VERSION ""

NS_ :

BS_:

BU_: APIM_CISM FCIMB RACM_RCIM DSP WCM DACMC HUD_ADV TRM_ITRM ACM GWM _delete APIM IPC GENERIC TSTR

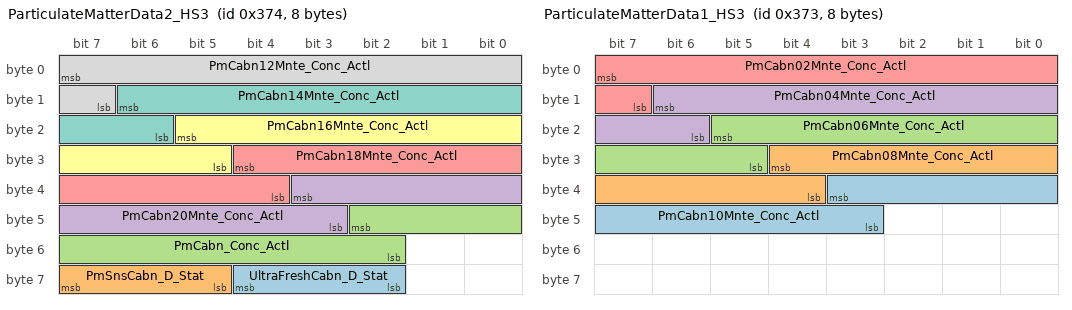
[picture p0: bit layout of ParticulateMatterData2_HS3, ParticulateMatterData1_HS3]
BO_ 884 ParticulateMatterData2_HS3: 8 GWM
 SG_ UltraFreshCabn_D_Stat : 60|3@0+ (1,0) [0|7] "SED"  APIM_CISM,GENERIC
 SG_ PmSnsCabn_D_Stat : 63|3@0+ (1,0) [0|7] "SED"  APIM_CISM,APIM,RACM_RCIM
 SG_ PmCabn_Conc_Actl : 42|9@0+ (1,0) [0|509] "parts/million"  APIM_CISM,APIM,RACM_RCIM
 SG_ PmCabn20Mnte_Conc_Actl : 35|9@0+ (1,0) [0|509] "parts/million"  RACM_RCIM,APIM_CISM,APIM
 SG_ PmCabn18Mnte_Conc_Actl : 28|9@0+ (1,0) [0|509] "parts/million"  RACM_RCIM,APIM_CISM,APIM
 SG_ PmCabn16Mnte_Conc_Actl : 21|9@0+ (1,0) [0|509] "parts/million"  RACM_RCIM,APIM_CISM,APIM
 SG_ PmCabn14Mnte_Conc_Actl : 14|9@0+ (1,0) [0|509] "parts/million"  RACM_RCIM,APIM_CISM,APIM
 SG_ PmCabn12Mnte_Conc_Actl : 7|9@0+ (1,0) [0|509] "parts/million"  RACM_RCIM,APIM_CISM,APIM

BO_ 883 ParticulateMatterData1_HS3: 8 GWM
 SG_ PmCabn10Mnte_Conc_Actl : 35|9@0+ (1,0) [0|509] "parts/million"  RACM_RCIM,APIM_CISM,APIM
 SG_ PmCabn08Mnte_Conc_Actl : 28|9@0+ (1,0) [0|509] "parts/million"  RACM_RCIM,APIM_CISM,APIM
 SG_ PmCabn06Mnte_Conc_Actl : 21|9@0+ (1,0) [0|509] "parts/million"  RACM_RCIM,APIM_CISM,APIM
 SG_ PmCabn04Mnte_Conc_Actl : 14|9@0+ (1,0) [0|509] "parts/million"  RACM_RCIM,APIM_CISM,APIM
 SG_ PmCabn02Mnte_Conc_Actl : 7|9@0+ (1,0) [0|509] "parts/million"  RACM_RCIM,APIM_CISM,APIM

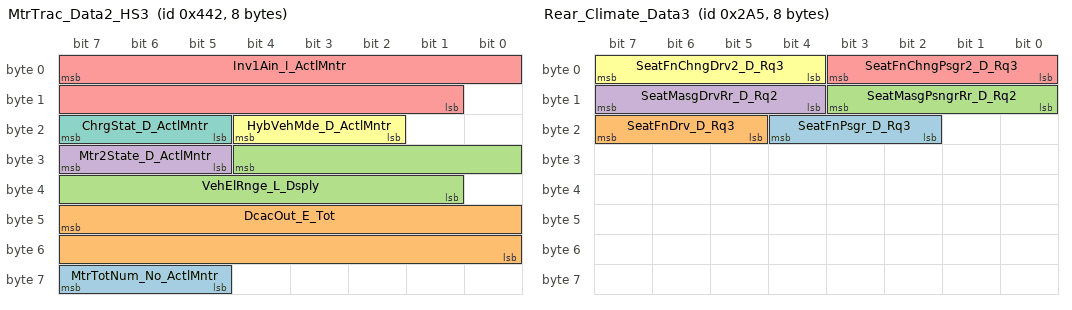
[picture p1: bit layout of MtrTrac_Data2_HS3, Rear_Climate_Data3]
BO_ 1090 MtrTrac_Data2_HS3: 8 GWM
 SG_ MtrTotNum_No_ActlMntr : 63|3@0+ (1,0) [0|7] "unitless"  GENERIC
 SG_ DcacOut_E_Tot : 47|16@0+ (20,0) [0|1310700] "watthour"  APIM_CISM,APIM
 SG_ VehElRnge_L_Dsply : 28|12@0+ (0.1,0) [0|409.3] "kilometer"  APIM_CISM,APIM,HUD_ADV,IPC
 SG_ Mtr2State_D_ActlMntr : 31|3@0+ (1,0) [0|7] "SED" Vector__XXX
 SG_ Inv1Ain_I_ActlMntr : 7|15@0+ (0.1,-1000) [-1000|2276.5] "ampere"  GENERIC
 SG_ HybVehMde_D_ActlMntr : 20|3@0+ (1,0) [0|7] "SED"  GENERIC
 SG_ ChrgStat_D_ActlMntr : 23|3@0+ (1,0) [0|7] "SED"  GENERIC

BO_ 677 Rear_Climate_Data3: 8 RACM_RCIM
 SG_ SeatFnPsgr_D_Rq3 : 20|3@0+ (1,0) [0|7] "SED"  GWM
 SG_ SeatFnDrv_D_Rq3 : 23|3@0+ (1,0) [0|7] "SED"  GWM
 SG_ SeatMasgPsngrRr_D_Rq2 : 11|4@0+ (1,0) [0|15] "SED"  GWM
 SG_ SeatMasgDrvRr_D_Rq2 : 15|4@0+ (1,0) [0|15] "SED"  GWM
 SG_ SeatFnChngPsgr2_D_Rq3 : 3|4@0+ (1,0) [0|15] "SED"  GWM
 SG_ SeatFnChngDrv2_D_Rq3 : 7|4@0+ (1,0) [0|15] "SED"  GWM

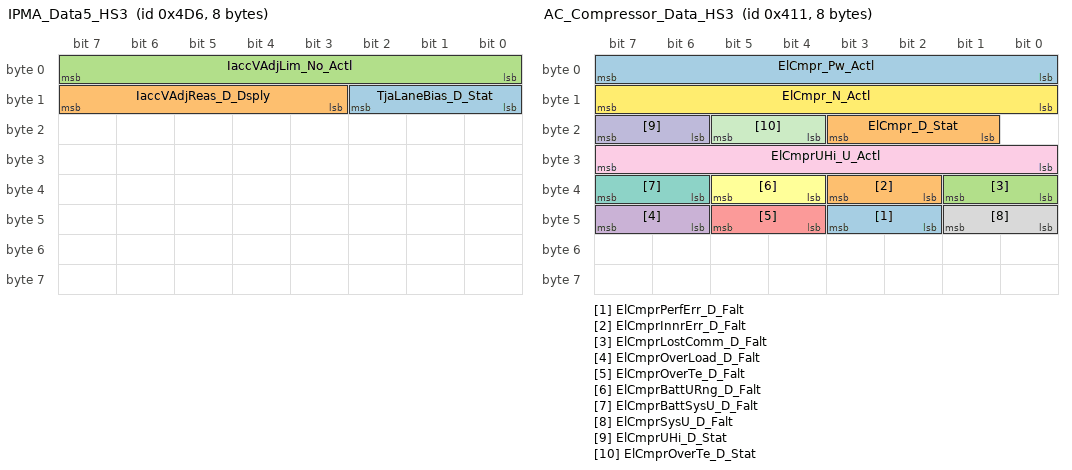
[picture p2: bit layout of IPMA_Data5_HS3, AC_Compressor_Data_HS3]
BO_ 1238 IPMA_Data5_HS3: 8 GWM
 SG_ TjaLaneBias_D_Stat : 10|3@0+ (1,0) [0|7] "SED"  IPC
 SG_ IaccVAdjReas_D_Dsply : 15|5@0+ (1,0) [0|31] "SED"  APIM,APIM_CISM,IPC
 SG_ IaccVAdjLim_No_Actl : 7|8@0+ (1,0) [0|255] "unitless"  APIM,APIM_CISM,IPC

BO_ 1041 AC_Compressor_Data_HS3: 8 GWM
 SG_ ElCmprPerfErr_D_Falt : 43|2@0+ (1,0) [0|3] "SED" Vector__XXX
 SG_ ElCmprInnrErr_D_Falt : 35|2@0+ (1,0) [0|3] "SED" Vector__XXX
 SG_ ElCmprLostComm_D_Falt : 33|2@0+ (1,0) [0|3] "SED" Vector__XXX
 SG_ ElCmprOverLoad_D_Falt : 47|2@0+ (1,0) [0|3] "SED" Vector__XXX
 SG_ ElCmprOverTe_D_Falt : 45|2@0+ (1,0) [0|3] "SED" Vector__XXX
 SG_ ElCmprBattURng_D_Falt : 37|2@0+ (1,0) [0|3] "SED" Vector__XXX
 SG_ ElCmprBattSysU_D_Falt : 39|2@0+ (1,0) [0|3] "SED" Vector__XXX
 SG_ ElCmprSysU_D_Falt : 41|2@0+ (1,0) [0|3] "SED" Vector__XXX
 SG_ ElCmprUHi_U_Actl : 31|8@0+ (2,0) [0|510] "volt" Vector__XXX
 SG_ ElCmprUHi_D_Stat : 23|2@0+ (1,0) [0|3] "SED" Vector__XXX
 SG_ ElCmprOverTe_D_Stat : 21|2@0+ (1,0) [0|3] "SED" Vector__XXX
 SG_ ElCmpr_N_Actl : 15|8@0+ (50,0) [0|12700] "RPM"  WCM
 SG_ ElCmpr_Pw_Actl : 7|8@0+ (40,0) [0|10160] "watts" Vector__XXX
 SG_ ElCmpr_D_Stat : 19|3@0+ (1,0) [0|7] "SED" Vector__XXX

BO_ 2609971416 OTAPhysGWM_ECGtoWCM: 8 GWM
 SG_ OTAPhysGWM_ECGtoWCM : 7|29@0+ (1,0) [0|536870911] "unitless"  WCM

BO_ 2610126912 OTAPhysWCMtoGWM_ECG: 8 WCM
 SG_ OTAPhysWCMtoGWM_ECG : 7|29@0+ (1,0) [0|536870911] "unitless"  GWM

BO_ 2611019992 PARSEDPhysGWM_ECGtoWCM: 8 GWM
 SG_ PARSEDPhysGWM_ECGtoWCM : 7|29@0+ (1,0) [0|536870911] "unitless"  WCM

BO_ 2611175488 PARSEDPhysWCMtoGWM_ECG: 8 WCM
 SG_ PARSEDPhysWCMtoGWM_ECG : 7|29@0+ (1,0) [0|536870911] "unitless"  GWM

BO_ 2612068568 PARSEDPushFcGWM_ECGtoWCM: 8 GWM
 SG_ PARSEDPushFcGWM_ECGtoWCM : 7|29@0+ (1,0) [0|536870911] "unitless"  WCM

BO_ 2612224064 PARSEDPushWCMtoGWM_ECG: 8 WCM
 SG_ PARSEDPushWCMtoGWM_ECG : 7|29@0+ (1,0) [0|536870911] "unitless"  GWM

BO_ 557 DSPAMP_Send_Signals_2: 8 DSP
 SG_ AudioToneTouchY_D_Stat : 15|8@0+ (1,0) [0|255] "SED"  APIM_CISM,APIM
 SG_ AudioToneTouchX_D_Stat : 7|8@0+ (1,0) [0|255] "SED"  APIM_CISM,APIM
 SG_ AudioToneTouch_D_Stat : 23|2@0+ (1,0) [0|3] "SED"  APIM_CISM,APIM

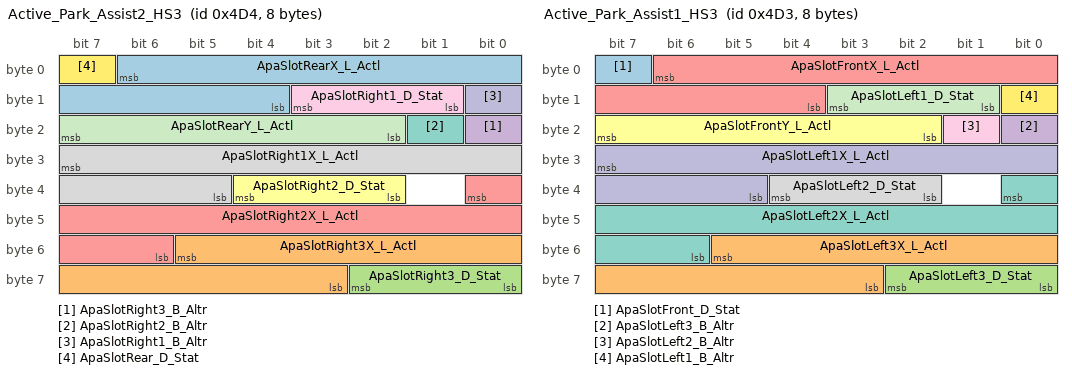
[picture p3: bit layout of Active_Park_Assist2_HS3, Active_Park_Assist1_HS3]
BO_ 1236 Active_Park_Assist2_HS3: 8 GWM
 SG_ ApaSlotRearX_L_Actl : 6|11@0+ (0.02,-20.96) [-20.96|19.98] "meter"  APIM_CISM,APIM
 SG_ ApaSlotRight3X_L_Actl : 53|11@0+ (0.02,-20.96) [-20.96|19.98] "meter"  APIM_CISM,APIM
 SG_ ApaSlotRight3_D_Stat : 58|3@0+ (1,0) [0|7] "SED"  APIM_CISM,APIM
 SG_ ApaSlotRight3_B_Altr : 16|1@0+ (1,0) [0|1] "SED"  APIM_CISM,APIM
 SG_ ApaSlotRight2X_L_Actl : 32|11@0+ (0.02,-20.96) [-20.96|19.98] "meter"  APIM_CISM,APIM
 SG_ ApaSlotRight2_D_Stat : 36|3@0+ (1,0) [0|7] "SED"  APIM_CISM,APIM
 SG_ ApaSlotRight2_B_Altr : 17|1@0+ (1,0) [0|1] "SED"  APIM_CISM,APIM
 SG_ ApaSlotRight1X_L_Actl : 31|11@0+ (0.02,-20.96) [-20.96|19.98] "meter"  APIM_CISM,APIM
 SG_ ApaSlotRight1_D_Stat : 11|3@0+ (1,0) [0|7] "SED"  APIM_CISM,APIM
 SG_ ApaSlotRight1_B_Altr : 8|1@0+ (1,0) [0|1] "SED"  APIM_CISM,APIM
 SG_ ApaSlotRearY_L_Actl : 23|6@0+ (0.2,-6.4) [-6.4|6.2] "meter"  APIM_CISM,APIM
 SG_ ApaSlotRear_D_Stat : 7|1@0+ (1,0) [0|1] "SED"  APIM_CISM,APIM

BO_ 1235 Active_Park_Assist1_HS3: 8 GWM
 SG_ ApaSlotFront_D_Stat : 7|1@0+ (1,0) [0|1] "SED"  APIM_CISM,APIM
 SG_ ApaSlotLeft3X_L_Actl : 53|11@0+ (0.02,-20.96) [-20.96|19.98] "meter"  APIM_CISM,APIM
 SG_ ApaSlotLeft3_D_Stat : 58|3@0+ (1,0) [0|7] "SED"  APIM_CISM,APIM
 SG_ ApaSlotLeft3_B_Altr : 16|1@0+ (1,0) [0|1] "SED"  APIM_CISM,APIM
 SG_ ApaSlotFrontX_L_Actl : 6|11@0+ (0.02,-20.96) [-20.96|19.98] "meter"  APIM_CISM,APIM
 SG_ ApaSlotFrontY_L_Actl : 23|6@0+ (0.2,-6.4) [-6.4|6.2] "meter"  APIM_CISM,APIM
 SG_ ApaSlotLeft2X_L_Actl : 32|11@0+ (0.02,-20.96) [-20.96|19.98] "meter"  APIM_CISM,APIM
 SG_ ApaSlotLeft2_D_Stat : 36|3@0+ (1,0) [0|7] "SED"  APIM_CISM,APIM
 SG_ ApaSlotLeft2_B_Altr : 17|1@0+ (1,0) [0|1] "SED"  APIM_CISM,APIM
 SG_ ApaSlotLeft1X_L_Actl : 31|11@0+ (0.02,-20.96) [-20.96|19.98] "meter"  APIM_CISM,APIM
 SG_ ApaSlotLeft1_D_Stat : 11|3@0+ (1,0) [0|7] "SED"  APIM_CISM,APIM
 SG_ ApaSlotLeft1_B_Altr : 8|1@0+ (1,0) [0|1] "SED"  APIM_CISM,APIM

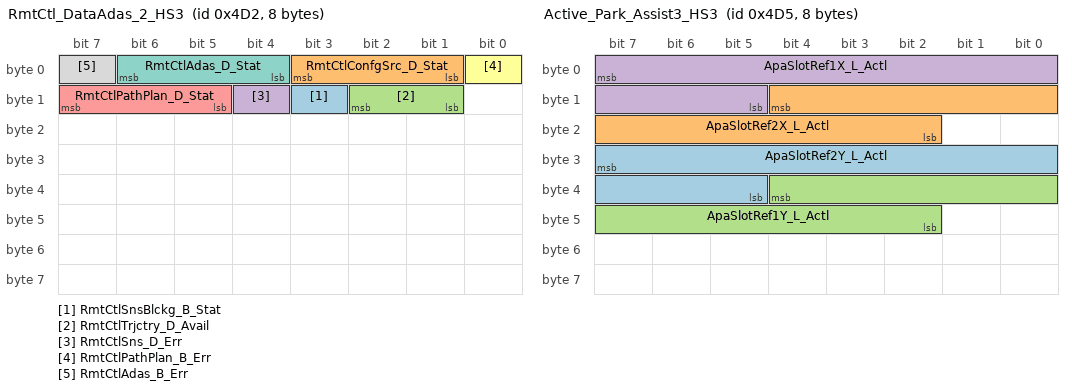
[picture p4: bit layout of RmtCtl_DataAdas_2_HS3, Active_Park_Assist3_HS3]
BO_ 1234 RmtCtl_DataAdas_2_HS3: 8 GWM
 SG_ RmtCtlSnsBlckg_B_Stat : 11|1@0+ (1,0) [0|1] "SED"  GENERIC
 SG_ RmtCtlConfgSrc_D_Stat : 3|3@0+ (1,0) [0|7] "SED"  GENERIC
 SG_ RmtCtlTrjctry_D_Avail : 10|2@0+ (1,0) [0|3] "SED"  GENERIC
 SG_ RmtCtlSns_D_Err : 12|1@0+ (1,0) [0|1] "SED"  GENERIC
 SG_ RmtCtlPathPlan_D_Stat : 15|3@0+ (1,0) [0|7] "SED"  GENERIC
 SG_ RmtCtlPathPlan_B_Err : 0|1@0+ (1,0) [0|1] "SED"  GENERIC
 SG_ RmtCtlAdas_D_Stat : 6|3@0+ (1,0) [0|7] "SED"  GENERIC
 SG_ RmtCtlAdas_B_Err : 7|1@0+ (1,0) [0|1] "SED"  GENERIC

BO_ 1237 Active_Park_Assist3_HS3: 8 GWM
 SG_ ApaSlotRef2Y_L_Actl : 31|11@0+ (0.02,-20.96) [-20.96|19.98] "meter"  APIM_CISM,APIM
 SG_ ApaSlotRef2X_L_Actl : 12|11@0+ (0.02,-20.96) [-20.96|19.98] "meter"  APIM_CISM,APIM
 SG_ ApaSlotRef1Y_L_Actl : 36|11@0+ (0.02,-20.96) [-20.96|19.98] "meter"  APIM_CISM,APIM
 SG_ ApaSlotRef1X_L_Actl : 7|11@0+ (0.02,-20.96) [-20.96|19.98] "meter"  APIM_CISM,APIM

BO_ 976 VehCharacteristicSet2_HS3: 8 GWM
 SG_ VehLong2_A_Actl_UB : 34|1@0+ (1,0) [0|1] "SED"  APIM_CISM,ACM
 SG_ VehLong2_A_Actl : 52|13@0+ (0.01,-40) [-40|41.89] "m/s^2"  APIM_CISM,ACM

BO_ 715 SSPClnt_SSPSrv_WORD_Rx: 8 APIM
 SG_ RDISP_SSP_WORD_Rx : 7|64@0+ (1,0) [0|1.84467440737096E+019] "unitless"  APIM_CISM,ACM

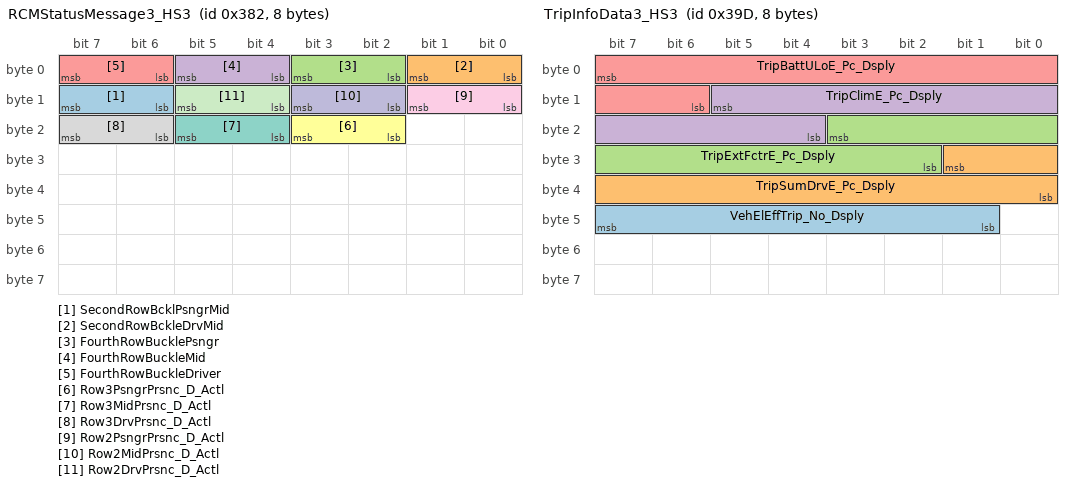
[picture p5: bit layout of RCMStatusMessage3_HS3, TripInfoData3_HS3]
BO_ 898 RCMStatusMessage3_HS3: 8 GWM
 SG_ SecondRowBcklPsngrMid : 15|2@0+ (1,0) [0|3] "SED"  IPC
 SG_ SecondRowBckleDrvMid : 1|2@0+ (1,0) [0|3] "SED"  IPC
 SG_ FourthRowBucklePsngr : 3|2@0+ (1,0) [0|3] "SED"  IPC
 SG_ FourthRowBuckleMid : 5|2@0+ (1,0) [0|3] "SED"  IPC
 SG_ FourthRowBuckleDriver : 7|2@0+ (1,0) [0|3] "SED"  IPC
 SG_ Row3PsngrPrsnc_D_Actl : 19|2@0+ (1,0) [0|3] "SED"  IPC
 SG_ Row3MidPrsnc_D_Actl : 21|2@0+ (1,0) [0|3] "SED"  IPC
 SG_ Row3DrvPrsnc_D_Actl : 23|2@0+ (1,0) [0|3] "SED"  IPC
 SG_ Row2PsngrPrsnc_D_Actl : 9|2@0+ (1,0) [0|3] "SED"  IPC
 SG_ Row2MidPrsnc_D_Actl : 11|2@0+ (1,0) [0|3] "SED"  IPC
 SG_ Row2DrvPrsnc_D_Actl : 13|2@0+ (1,0) [0|3] "SED"  IPC

BO_ 925 TripInfoData3_HS3: 8 GWM
 SG_ VehElEffTrip_No_Dsply : 47|7@0+ (10,-100) [-100|1150] "wattHr/km"  APIM_CISM,APIM,IPC
 SG_ TripSumDrvE_Pc_Dsply : 25|10@0+ (0.1,0) [0|102.1] "percent"  APIM_CISM,APIM,IPC
 SG_ TripExtFctrE_Pc_Dsply : 19|10@0+ (0.1,0) [0|102.1] "percent"  APIM_CISM,APIM,IPC
 SG_ TripClimE_Pc_Dsply : 13|10@0+ (0.1,0) [0|102.1] "percent"  APIM_CISM,APIM,IPC
 SG_ TripBattULoE_Pc_Dsply : 7|10@0+ (0.1,0) [0|102.1] "percent"  APIM_CISM,APIM,IPC

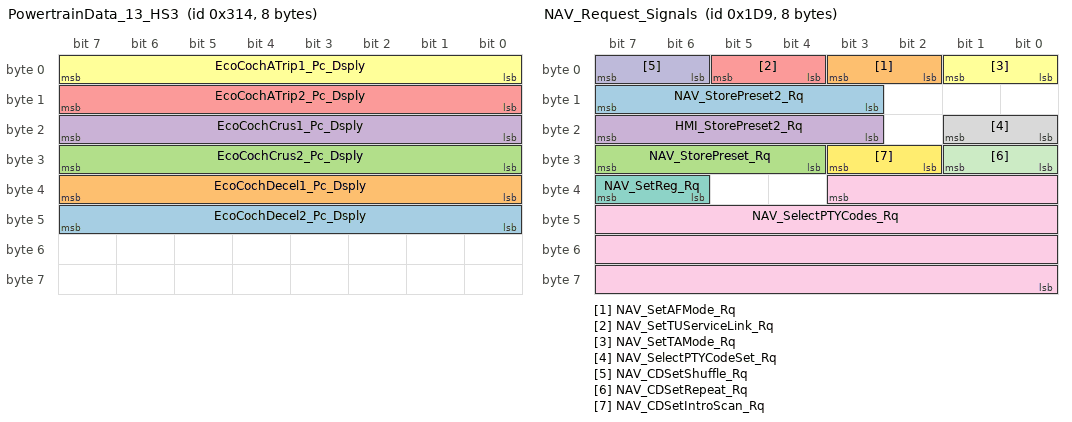
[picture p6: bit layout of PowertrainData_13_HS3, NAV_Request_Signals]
BO_ 788 PowertrainData_13_HS3: 8 GWM
 SG_ EcoCochDecel2_Pc_Dsply : 47|8@0+ (0.392157,0) [0|100.000035] "percent"  APIM_CISM,APIM
 SG_ EcoCochDecel1_Pc_Dsply : 39|8@0+ (0.392157,0) [0|100.000035] "percent"  APIM_CISM,APIM
 SG_ EcoCochCrus2_Pc_Dsply : 31|8@0+ (0.392157,0) [0|100.000035] "percent"  APIM_CISM,APIM
 SG_ EcoCochCrus1_Pc_Dsply : 23|8@0+ (0.392157,0) [0|100.000035] "percent"  APIM_CISM,APIM
 SG_ EcoCochATrip2_Pc_Dsply : 15|8@0+ (0.392157,0) [0|100.000035] "percent"  APIM_CISM,APIM
 SG_ EcoCochATrip1_Pc_Dsply : 7|8@0+ (0.392157,0) [0|100.000035] "percent"  APIM_CISM,APIM

BO_ 473 NAV_Request_Signals: 8 APIM
 SG_ NAV_StorePreset2_Rq : 15|5@0+ (1,0) [0|31] "SED"  APIM_CISM,ACM
 SG_ NAV_SetAFMode_Rq : 3|2@0+ (1,0) [0|3] "SED"  APIM_CISM,ACM,GENERIC
 SG_ NAV_StorePreset_Rq : 31|4@0+ (1,0) [0|15] "SED"  APIM_CISM,ACM,GENERIC
 SG_ HMI_StorePreset2_Rq : 23|5@0+ (1,0) [0|31] "SED"  APIM_CISM,ACM
 SG_ NAV_SetTUServiceLink_Rq : 5|2@0+ (1,0) [0|3] "SED"  APIM_CISM,ACM
 SG_ NAV_SetTAMode_Rq : 1|2@0+ (1,0) [0|3] "SED"  APIM_CISM,ACM
 SG_ NAV_SetReg_Rq : 39|2@0+ (1,0) [0|3] "SED"  APIM_CISM,ACM
 SG_ NAV_SelectPTYCodeSet_Rq : 17|2@0+ (1,0) [0|3] "SED"  APIM_CISM,ACM
 SG_ NAV_SelectPTYCodes_Rq : 35|28@0+ (1,0) [0|268435455] "unitless"  APIM_CISM,ACM
 SG_ NAV_CDSetShuffle_Rq : 7|2@0+ (1,0) [0|3] "SED"  APIM_CISM,ACM
 SG_ NAV_CDSetRepeat_Rq : 25|2@0+ (1,0) [0|3] "SED"  APIM_CISM,ACM
 SG_ NAV_CDSetIntroScan_Rq : 27|2@0+ (1,0) [0|3] "SED"  APIM_CISM,ACM

BO_ 2000 TesterPhysicalReqAPIM: 8 TSTR
 SG_ TesterPhysicalReqAPIM : 7|64@0+ (1,0) [0|1.84467E+019] "unitless"  APIM,APIM_CISM

BO_ 810 ECG_Data_HS3: 8 GWM
 SG_ ExtLghtDsply_B_StatArb : 7|1@0+ (1,0) [0|1] "SED"  APIM_CISM,APIM
 SG_ OneTEditActv_B_RqCld : 32|1@0+ (1,0) [0|1] "SED"  APIM_CISM,APIM

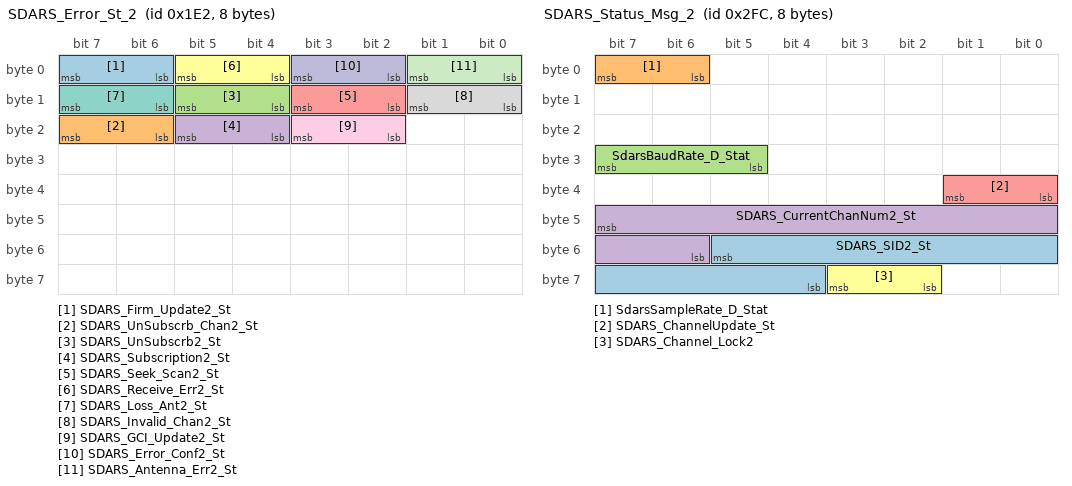
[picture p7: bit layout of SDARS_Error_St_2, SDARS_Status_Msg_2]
BO_ 482 SDARS_Error_St_2: 8 APIM
 SG_ SDARS_Firm_Update2_St : 7|2@0+ (1,0) [0|3] "SED"  RACM_RCIM,HUD_ADV,IPC
 SG_ SDARS_UnSubscrb_Chan2_St : 23|2@0+ (1,0) [0|3] "SED"  RACM_RCIM,HUD_ADV,IPC
 SG_ SDARS_UnSubscrb2_St : 13|2@0+ (1,0) [0|3] "SED"  RACM_RCIM,HUD_ADV,IPC
 SG_ SDARS_Subscription2_St : 21|2@0+ (1,0) [0|3] "SED"  RACM_RCIM,HUD_ADV,IPC
 SG_ SDARS_Seek_Scan2_St : 11|2@0+ (1,0) [0|3] "SED"  RACM_RCIM,HUD_ADV,IPC
 SG_ SDARS_Receive_Err2_St : 5|2@0+ (1,0) [0|3] "SED"  RACM_RCIM,HUD_ADV,IPC
 SG_ SDARS_Loss_Ant2_St : 15|2@0+ (1,0) [0|3] "SED"  RACM_RCIM,HUD_ADV,IPC
 SG_ SDARS_Invalid_Chan2_St : 9|2@0+ (1,0) [0|3] "SED"  RACM_RCIM,HUD_ADV,IPC
 SG_ SDARS_GCI_Update2_St : 19|2@0+ (1,0) [0|3] "SED"  RACM_RCIM,HUD_ADV,IPC
 SG_ SDARS_Error_Conf2_St : 3|2@0+ (1,0) [0|3] "SED"  RACM_RCIM,HUD_ADV,IPC
 SG_ SDARS_Antenna_Err2_St : 1|2@0+ (1,0) [0|3] "SED"  RACM_RCIM,HUD_ADV,IPC

BO_ 764 SDARS_Status_Msg_2: 8 APIM
 SG_ SDARS_SID2_St : 53|10@0+ (1,0) [0|1023] "unitless"  APIM_CISM,HUD_ADV,RACM_RCIM,ACM
 SG_ SdarsSampleRate_D_Stat : 7|2@0+ (1,0) [0|3] "SED"  APIM_CISM,ACM
 SG_ SdarsBaudRate_D_Stat : 31|3@0+ (1,0) [0|7] "SED"  APIM_CISM,ACM
 SG_ SDARS_CurrentChanNum2_St : 47|10@0+ (1,0) [0|1023] "unitless"  APIM_CISM,HUD_ADV,RACM_RCIM,IPC,ACM
 SG_ SDARS_ChannelUpdate_St : 33|2@0+ (1,0) [0|3] "SED"  APIM_CISM,ACM
 SG_ SDARS_Channel_Lock2 : 59|2@0+ (1,0) [0|3] "SED"  APIM_CISM,HUD_ADV,RACM_RCIM,ACM

BO_ 628 GWM_Send_Signals_9_HS3: 8 GWM
 SG_ CamraRearBttn_D_Stat_UB : 58|1@0+ (1,0) [0|1] "SED"  APIM_CISM,APIM
 SG_ CamraRearBttn_D_Stat : 59|1@0+ (1,0) [0|1] "SED"  APIM_CISM,APIM
 SG_ GearEngag_D_Actl_UB : 47|1@0+ (1,0) [0|1] "SED"  IPC
 SG_ GearEngag_D_Actl : 34|3@0+ (1,0) [0|7] "SED"  IPC
 SG_ RvltnMatchAllw_D_Stat_UB : 35|1@0+ (1,0) [0|1] "SED"  IPC
 SG_ RvltnMatchAllw_D_Stat : 37|2@0+ (1,0) [0|3] "SED"  IPC
 SG_ SeatScrnPsngrOn_B_Rq : 39|1@0+ (1,0) [0|1] "SED"  APIM_CISM,APIM
 SG_ SeatScrnPsngrOn_B_Rq_UB : 38|1@0+ (1,0) [0|1] "SED"  APIM_CISM,APIM
 SG_ CamraRearOn_B_RqBalrl_UB : 6|1@0+ (1,0) [0|1] "SED"  APIM_CISM,ACM,APIM
 SG_ CamraRearOn_B_RqBalrr_UB : 4|1@0+ (1,0) [0|1] "SED"  APIM_CISM,ACM,APIM
 SG_ CamraRearOn_B_RqBalrr : 5|1@0+ (1,0) [0|1] "SED"  APIM_CISM,ACM,APIM
 SG_ CamraRearOn_B_RqBalrl : 7|1@0+ (1,0) [0|1] "SED"  APIM_CISM,ACM,APIM
 SG_ PwFlwFuelDrv_D_Dsply : 50|3@0+ (1,0) [0|7] "SED"  APIM_CISM,APIM
 SG_ PwFlwFuelClimt_B_Dsply : 51|1@0+ (1,0) [0|1] "SED"  APIM_CISM,APIM
 SG_ PwFlwFuelBatt_B_Dsply : 53|1@0+ (1,0) [0|1] "SED"  APIM_CISM,APIM
 SG_ PwFlwBattGen_D_Dsply : 55|1@0+ (1,0) [0|1] "SED"  APIM_CISM,APIM
 SG_ PwFlwBattClimt_B_Dsply : 41|1@0+ (1,0) [0|1] "SED"  APIM_CISM,APIM
 SG_ PwFlwBatt_D_Dsply : 46|4@0+ (1,0) [0|15] "SED"  APIM_CISM,APIM
 SG_ PwFlwFuelDrv_D_Dsply_UB : 62|1@0+ (1,0) [0|1] "SED"  APIM_CISM,APIM
 SG_ PwFlwFuelClimt_B_Dsply_UB : 63|1@0+ (1,0) [0|1] "SED"  APIM_CISM,APIM
 SG_ PwFlwFuelBatt_B_Dsply_UB : 52|1@0+ (1,0) [0|1] "SED"  APIM_CISM,APIM
 SG_ PwFlwBattGen_D_Dsply_UB : 54|1@0+ (1,0) [0|1] "SED"  APIM_CISM,APIM
 SG_ PwFlwBattClimt_B_Dsply_UB : 40|1@0+ (1,0) [0|1] "SED"  APIM_CISM,APIM
 SG_ PwFlwBatt_D_Dsply_UB : 42|1@0+ (1,0) [0|1] "SED"  APIM_CISM,APIM
 SG_ TrailCtlMsgTxt_D_Rq : 3|4@0+ (1,0) [0|15] "SED"  IPC
 SG_ TrailCtlMsgTxt_D_Rq_UB : 15|1@0+ (1,0) [0|1] "SED"  IPC
 SG_ TrailCtl_D_Stat_UB : 20|1@0+ (1,0) [0|1] "SED"  IPC
 SG_ TrailCtl_D_Stat : 23|3@0+ (1,0) [0|7] "SED"  IPC
 SG_ Veh_V_DsplyTrailCtlSet : 14|6@0+ (0.5,0) [0|31] "unitless"  IPC
 SG_ Veh_V_DsplyTrailCtlSet_UB : 8|1@0+ (1,0) [0|1] "SED"  IPC
 SG_ SeatScrnDrvOn_B_Rq_UB : 17|1@0+ (1,0) [0|1] "SED"  APIM_CISM,APIM
 SG_ SeatScrnDrvOn_B_Rq : 18|1@0+ (1,0) [0|1] "SED"  APIM_CISM,APIM

BO_ 710 BEZEL_RDISP_WORD_Tx_HS3: 8 GWM
 SG_ BEZEL_RDISP_WORD_Tx : 7|64@0+ (1,0) [0|1.84467440737096E+019] "unitless"  APIM,APIM_CISM

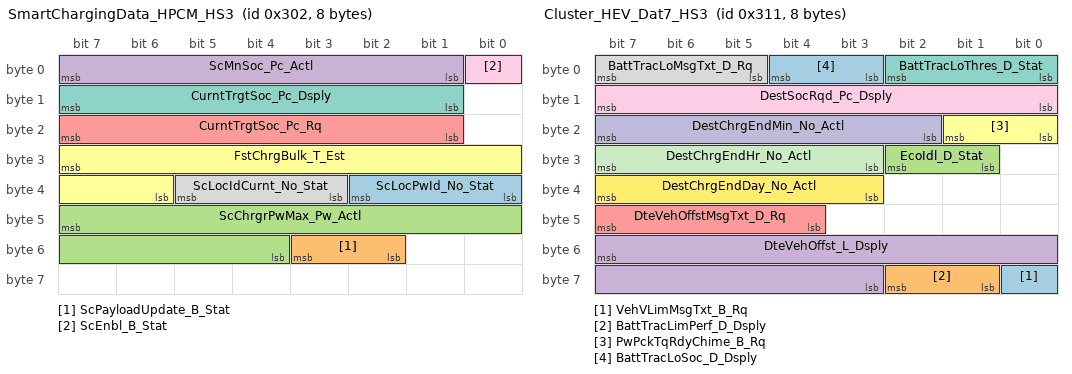
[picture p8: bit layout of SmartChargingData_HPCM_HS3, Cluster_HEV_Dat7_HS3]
BO_ 770 SmartChargingData_HPCM_HS3: 8 GWM
 SG_ ScLocPwId_No_Stat : 34|3@0+ (1,0) [0|7] "unitless"  GENERIC
 SG_ ScPayloadUpdate_B_Stat : 51|2@0+ (1,0) [0|3] "SED"  GENERIC
 SG_ ScChrgrPwMax_Pw_Actl : 47|12@0+ (50,0) [0|204700] "watts"  GENERIC
 SG_ ScMnSoc_Pc_Actl : 7|7@0+ (1,0) [0|127] "percent"  APIM_CISM,APIM
 SG_ CurntTrgtSoc_Pc_Rq : 23|7@0+ (1,0) [0|127] "percent"  GENERIC
 SG_ FstChrgBulk_T_Est : 31|10@0+ (1,0) [0|1023] "minute"  APIM_CISM,APIM,IPC
 SG_ CurntTrgtSoc_Pc_Dsply : 15|7@0+ (1,0) [0|127] "percent"  APIM_CISM,APIM,IPC
 SG_ ScLocIdCurnt_No_Stat : 37|3@0+ (1,0) [0|7] "unitless"  APIM_CISM,APIM
 SG_ ScEnbl_B_Stat : 0|1@0+ (1,0) [0|1] "SED"  APIM_CISM,APIM

BO_ 785 Cluster_HEV_Dat7_HS3: 8 GWM
 SG_ VehVLimMsgTxt_B_Rq : 56|1@0+ (1,0) [0|1] "SED"  IPC
 SG_ BattTracLimPerf_D_Dsply : 58|2@0+ (1,0) [0|3] "SED"  IPC
 SG_ EcoIdl_D_Stat : 26|2@0+ (1,0) [0|3] "SED"  APIM_CISM,APIM
 SG_ DteVehOffst_L_Dsply : 55|13@0+ (0.1,-400) [-400|418.9] "kilometer"  APIM_CISM,APIM,IPC
 SG_ DteVehOffstMsgTxt_D_Rq : 47|4@0+ (1,0) [0|15] "SED"  APIM_CISM,APIM,IPC
 SG_ PwPckTqRdyChime_B_Rq : 17|2@0+ (1,0) [0|3] "SED"  IPC
 SG_ BattTracLoThres_D_Stat : 2|3@0+ (1,0) [0|7] "SED"  APIM_CISM,APIM
 SG_ BattTracLoMsgTxt_D_Rq : 7|3@0+ (1,0) [0|7] "SED"  IPC
 SG_ DestSocRqd_Pc_Dsply : 15|8@0+ (0.5,0) [0|127.5] "percent"  APIM_CISM,APIM,IPC
 SG_ DestChrgEndMin_No_Actl : 23|6@0+ (1,0) [0|63] "Minutes"  APIM_CISM,APIM,IPC
 SG_ DestChrgEndHr_No_Actl : 31|5@0+ (1,0) [0|31] "Hours"  APIM_CISM,APIM,IPC
 SG_ DestChrgEndDay_No_Actl : 39|5@0+ (1,0) [1|31] "days"  APIM_CISM,APIM,IPC
 SG_ BattTracLoSoc_D_Dsply : 4|2@0+ (1,0) [0|3] "SED"  APIM_CISM,APIM,IPC

BO_ 1202 SDARS_VR_WORD_Rx: 8 APIM
 SG_ SDARS_VR_WORD_Rx : 7|64@0+ (1,0) [0|1.84467440737096E+019] "unitless"  APIM_CISM,ACM

BO_ 1210 SDARS_VR_WORD_Tx: 8 ACM
 SG_ SDARS_VR_WORD_Tx : 7|64@0+ (1,0) [0|1.84467440737096E+019] "unitless"  APIM_CISM,APIM

BO_ 391 ACU_Request_Signals_3: 8 ACM
 SG_ ACU_CtrlChimeChan_Rq : 7|2@0+ (1,0) [0|3] "SED"  DSP

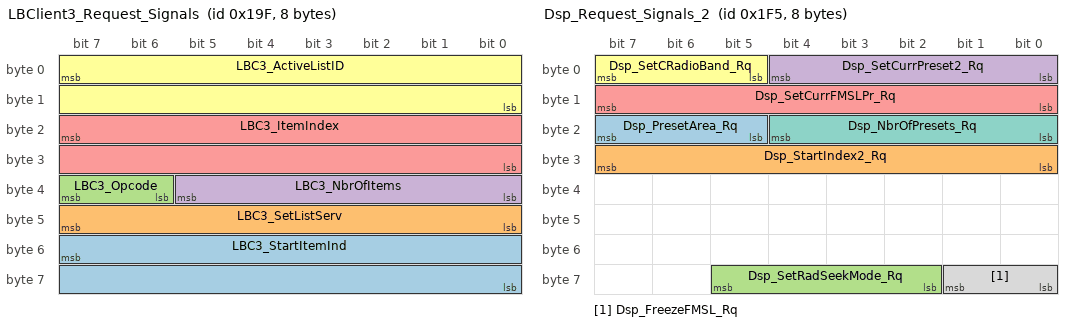
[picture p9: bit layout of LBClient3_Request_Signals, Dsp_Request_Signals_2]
BO_ 415 LBClient3_Request_Signals: 8 RACM_RCIM
 SG_ LBC3_StartItemInd : 55|16@0+ (1,0) [0|65535] "unitless"  APIM_CISM,APIM,ACM
 SG_ LBC3_SetListServ : 47|8@0+ (1,0) [0|255] "unitless"  APIM_CISM,APIM,ACM
 SG_ LBC3_Opcode : 39|2@0+ (1,0) [0|3] "SED"  APIM_CISM,APIM,ACM
 SG_ LBC3_NbrOfItems : 37|6@0+ (1,0) [0|63] "unitless"  APIM_CISM,ACM,APIM
 SG_ LBC3_ItemIndex : 23|16@0+ (1,0) [0|65535] "unitless"  APIM_CISM,ACM,APIM
 SG_ LBC3_ActiveListID : 7|16@0+ (1,0) [0|65535] "unitless"  APIM_CISM,APIM,ACM

BO_ 703 CONMP_MC_WORD_Rx: 8 IPC
 SG_ CONMP_MC_WORD_Rx : 7|64@0+ (1,0) [0|1.84467440737096E+019] "unitless"  APIM_CISM,APIM

BO_ 695 CONMP_MC_WORD_Tx: 8 APIM
 SG_ CONMP_MC_WORD_Tx : 7|64@0+ (1,0) [0|1.84467440737096E+019] "unitless"  APIM_CISM,IPC

BO_ 501 Dsp_Request_Signals_2: 8 APIM
 SG_ Dsp_PresetArea_Rq : 23|3@0+ (1,0) [0|7] "SED"  APIM_CISM,ACM
 SG_ Dsp_StartIndex2_Rq : 31|8@0+ (1,0) [0|255] "unitless"  APIM_CISM,ACM
 SG_ Dsp_SetRadSeekMode_Rq : 61|4@0+ (1,0) [0|15] "SED"  APIM_CISM,ACM
 SG_ Dsp_SetCurrPreset2_Rq : 4|5@0+ (1,0) [0|30] "SED"  APIM_CISM,ACM
 SG_ Dsp_SetCurrFMSLPr_Rq : 15|8@0+ (1,0) [0|254] "unitless"  APIM_CISM,ACM
 SG_ Dsp_SetCRadioBand_Rq : 7|3@0+ (1,0) [0|7] "SED"  APIM_CISM,ACM
 SG_ Dsp_NbrOfPresets_Rq : 20|5@0+ (1,0) [0|30] "unitless"  APIM_CISM,ACM
 SG_ Dsp_FreezeFMSL_Rq : 57|2@0+ (1,0) [0|3] "SED"  APIM_CISM,ACM

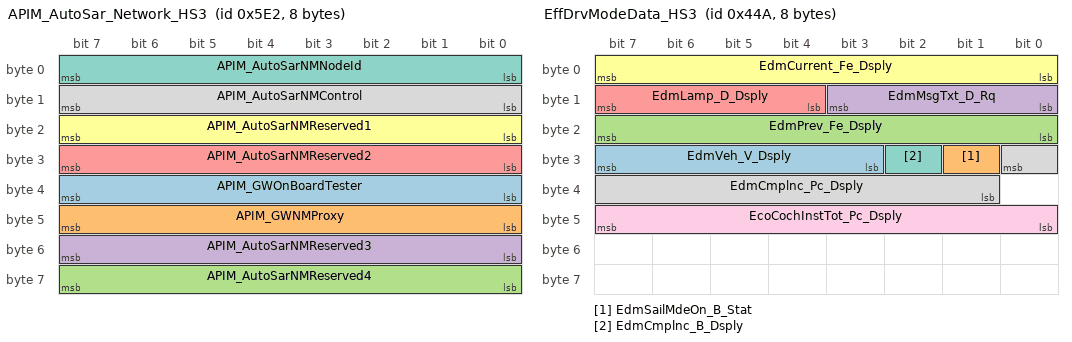
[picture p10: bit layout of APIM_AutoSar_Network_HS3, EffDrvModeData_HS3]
BO_ 1506 APIM_AutoSar_Network_HS3: 8 APIM
 SG_ APIM_GWOnBoardTester : 39|8@0+ (1,0) [0|255] "unitless"  HUD_ADV
 SG_ APIM_GWNMProxy : 47|8@0+ (1,0) [0|255] "unitless"  HUD_ADV
 SG_ APIM_AutoSarNMReserved4 : 63|8@0+ (1,0) [0|255] "unitless"  HUD_ADV
 SG_ APIM_AutoSarNMReserved3 : 55|8@0+ (1,0) [0|255] "unitless"  HUD_ADV
 SG_ APIM_AutoSarNMReserved2 : 31|8@0+ (1,0) [0|255] "unitless"  HUD_ADV
 SG_ APIM_AutoSarNMReserved1 : 23|8@0+ (1,0) [0|255] "unitless"  HUD_ADV
 SG_ APIM_AutoSarNMNodeId : 7|8@0+ (1,0) [0|255] "unitless"  HUD_ADV
 SG_ APIM_AutoSarNMControl : 15|8@0+ (1,0) [0|255] "unitless"  HUD_ADV

BO_ 651 TCU_Send_Signals_HS3: 8 GWM
 SG_ TelematicsSrvc_D_St : 47|3@0+ (1,0) [0|7] "SED"  APIM_CISM,ACM,APIM
 SG_ EmgcyCallMute_D_Stat : 39|3@0+ (1,0) [0|7] "SED"  APIM_CISM,ACM,APIM,DSP

BO_ 1098 EffDrvModeData_HS3: 8 GWM
 SG_ EdmVeh_V_Dsply : 31|5@0+ (5,0) [0|155] "km/h"  IPC
 SG_ EdmSailMdeOn_B_Stat : 25|1@0+ (1,0) [0|1] "SED"  IPC
 SG_ EdmPrev_Fe_Dsply : 23|8@0+ (0.1,0) [0|25.5] "litre/100km"  IPC
 SG_ EdmMsgTxt_D_Rq : 11|4@0+ (1,0) [0|15] "SED"  IPC
 SG_ EdmLamp_D_Dsply : 15|4@0+ (1,0) [0|15] "SED"  HUD_ADV,IPC
 SG_ EdmCurrent_Fe_Dsply : 7|8@0+ (0.1,0) [0|25.5] "litre/100km"  IPC
 SG_ EdmCmplnc_B_Dsply : 26|1@0+ (1,0) [0|1] "SED"  HUD_ADV,IPC
 SG_ EdmCmplnc_Pc_Dsply : 24|8@0+ (0.392157,0) [0|100.000035] "percent"  IPC
 SG_ EcoCochInstTot_Pc_Dsply : 47|8@0+ (0.392157,0) [0|100.000035] "percent"  IPC

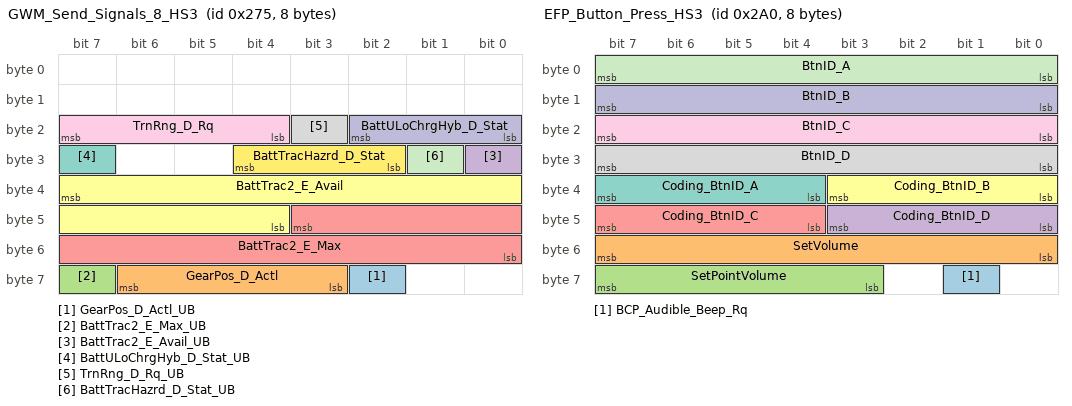
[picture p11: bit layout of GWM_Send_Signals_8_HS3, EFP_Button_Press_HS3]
BO_ 629 GWM_Send_Signals_8_HS3: 8 GWM
 SG_ GearPos_D_Actl_UB : 58|1@0+ (1,0) [0|1] "SED"  APIM,APIM_CISM
 SG_ GearPos_D_Actl : 62|4@0+ (1,0) [0|15] "SED"  APIM,APIM_CISM
 SG_ BattTrac2_E_Max_UB : 63|1@0+ (1,0) [0|1] "SED"  APIM_CISM,APIM
 SG_ BattTrac2_E_Avail_UB : 24|1@0+ (1,0) [0|1] "SED"  APIM_CISM,APIM
 SG_ BattTrac2_E_Max : 43|12@0+ (50,0) [0|204650] "watt*hour"  APIM_CISM,APIM
 SG_ BattTrac2_E_Avail : 39|12@0+ (50,0) [0|204650] "watt*hour"  APIM_CISM,APIM
 SG_ BattULoChrgHyb_D_Stat_UB : 31|1@0+ (1,0) [0|1] "SED"  IPC
 SG_ TrnRng_D_Rq_UB : 19|1@0+ (1,0) [0|1] "SED"  APIM,APIM_CISM
 SG_ TrnRng_D_Rq : 23|4@0+ (1,0) [0|15] "SED"  APIM,APIM_CISM
 SG_ BattULoChrgHyb_D_Stat : 18|3@0+ (1,0) [0|7] "SED"  IPC
 SG_ BattTracHazrd_D_Stat_UB : 25|1@0+ (1,0) [0|1] "SED"  IPC
 SG_ BattTracHazrd_D_Stat : 28|3@0+ (1,0) [0|7] "SED"  IPC

BO_ 718 BEZEL_RDISP_WORD_Rx: 8 APIM
 SG_ BEZEL_RDISP_WORD_Rx : 7|64@0+ (1,0) [0|1.84467440737096E+019] "unitless"  GWM

BO_ 672 EFP_Button_Press_HS3: 8 FCIMB
 SG_ BCP_Audible_Beep_Rq : 57|1@0+ (1,0) [0|1] "SED"  APIM_CISM,ACM,DSP
 SG_ SetVolume : 55|8@0+ (1,-30) [-30|30] "unitless"  DSP,APIM_CISM,ACM,APIM
 SG_ SetPointVolume : 63|5@0+ (1,0) [0|31] "unitless"  DSP,APIM_CISM,ACM,APIM
 SG_ Coding_BtnID_D : 43|4@0+ (1,0) [0|15] "SED"  APIM_CISM,ACM,APIM
 SG_ Coding_BtnID_C : 47|4@0+ (1,0) [0|15] "SED"  APIM_CISM,ACM,APIM
 SG_ Coding_BtnID_B : 35|4@0+ (1,0) [0|15] "SED"  APIM_CISM,ACM,APIM
 SG_ Coding_BtnID_A : 39|4@0+ (1,0) [0|15] "SED"  APIM_CISM,ACM,APIM
 SG_ BtnID_D : 31|8@0+ (1,0) [0|255] "unitless"  APIM_CISM,ACM,APIM
 SG_ BtnID_C : 23|8@0+ (1,0) [0|255] "unitless"  APIM_CISM,ACM,APIM
 SG_ BtnID_B : 15|8@0+ (1,0) [0|255] "unitless"  APIM_CISM,ACM,APIM
 SG_ BtnID_A : 7|8@0+ (1,0) [0|255] "unitless"  APIM_CISM,ACM,APIM

BO_ 1952 TesterPhysicalReqFCIMB: 8 TSTR
 SG_ TesterPhysicalReqFCIMB : 7|64@0+ (1,0) [0|1.84467E+019] "unitless"  FCIMB

BO_ 1960 TesterPhysicalResFCIMB: 8 FCIMB
 SG_ TesterPhysicalResFCIMB : 7|64@0+ (1,0) [0|1.84467E+019] "unitless"  TSTR

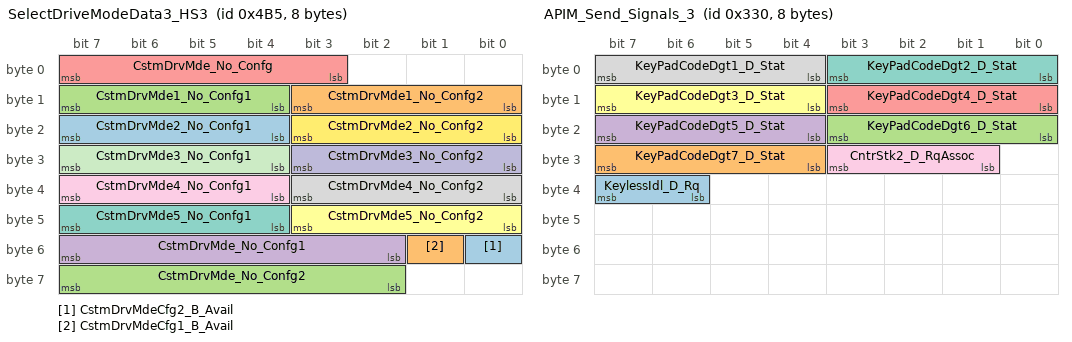
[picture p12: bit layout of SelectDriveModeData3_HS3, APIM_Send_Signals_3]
BO_ 1205 SelectDriveModeData3_HS3: 8 GWM
 SG_ CstmDrvMdeCfg2_B_Avail : 48|1@0+ (1,0) [0|1] "SED"  IPC
 SG_ CstmDrvMdeCfg1_B_Avail : 49|1@0+ (1,0) [0|1] "SED"  IPC
 SG_ CstmDrvMde_No_Confg2 : 63|6@0+ (1,0) [0|63] "unitless"  IPC
 SG_ CstmDrvMde_No_Confg1 : 55|6@0+ (1,0) [0|63] "unitless"  IPC
 SG_ CstmDrvMde_No_Confg : 7|5@0+ (1,0) [0|31] "unitless"  IPC
 SG_ CstmDrvMde5_No_Confg2 : 43|4@0+ (1,0) [0|15] "unitless"  IPC
 SG_ CstmDrvMde5_No_Confg1 : 47|4@0+ (1,0) [0|15] "unitless"  IPC
 SG_ CstmDrvMde4_No_Confg2 : 35|4@0+ (1,0) [0|15] "unitless"  IPC
 SG_ CstmDrvMde4_No_Confg1 : 39|4@0+ (1,0) [0|15] "unitless"  IPC
 SG_ CstmDrvMde3_No_Confg2 : 27|4@0+ (1,0) [0|15] "unitless"  IPC
 SG_ CstmDrvMde3_No_Confg1 : 31|4@0+ (1,0) [0|15] "unitless"  IPC
 SG_ CstmDrvMde2_No_Confg2 : 19|4@0+ (1,0) [0|15] "unitless"  IPC
 SG_ CstmDrvMde2_No_Confg1 : 23|4@0+ (1,0) [0|15] "unitless"  IPC
 SG_ CstmDrvMde1_No_Confg2 : 11|4@0+ (1,0) [0|15] "unitless"  IPC
 SG_ CstmDrvMde1_No_Confg1 : 15|4@0+ (1,0) [0|15] "unitless"  IPC

BO_ 1829 TesterPhysicalReqWCM: 8 TSTR
 SG_ TesterPhysicalReqWCM : 7|64@0+ (1,0) [0|1.84467E+019] "unitless"  WCM

BO_ 601 ECG_MC_WORD_Rx: 8 IPC
 SG_ ECG_MC_WORD_Rx : 7|64@0+ (1,0) [0|1.84467440737096E+019] "unitless"  GWM

BO_ 593 ECG_MC_WORD_Tx: 8 GWM
 SG_ ECG_MC_WORD_Tx : 7|64@0+ (1,0) [0|1.84467440737096E+019] "unitless"  IPC

BO_ 816 APIM_Send_Signals_3: 8 APIM
 SG_ KeylessIdl_D_Rq : 39|2@0+ (1,0) [0|3] "SED"  GWM
 SG_ KeyPadCodeDgt7_D_Stat : 31|4@0+ (1,0) [0|15] "SED"  GWM
 SG_ KeyPadCodeDgt6_D_Stat : 19|4@0+ (1,0) [0|15] "SED"  GWM
 SG_ KeyPadCodeDgt5_D_Stat : 23|4@0+ (1,0) [0|15] "SED"  GWM
 SG_ KeyPadCodeDgt4_D_Stat : 11|4@0+ (1,0) [0|15] "SED"  GWM
 SG_ KeyPadCodeDgt3_D_Stat : 15|4@0+ (1,0) [0|15] "SED"  GWM
 SG_ KeyPadCodeDgt2_D_Stat : 3|4@0+ (1,0) [0|15] "SED"  GWM
 SG_ KeyPadCodeDgt1_D_Stat : 7|4@0+ (1,0) [0|15] "SED"  GWM
 SG_ CntrStk2_D_RqAssoc : 27|3@0+ (1,0) [0|7] "SED"  GWM

BO_ 636 TCU_Send_Signals_3_HS3: 8 GWM
 SG_ WifiHtsptFqBand_D_Stat : 60|2@0+ (1,0) [0|3] "SED"  ACM,APIM,APIM_CISM
 SG_ WifiHtspt_D_Falt : 51|4@0+ (1,0) [0|15] "SED"  ACM,APIM,APIM_CISM
 SG_ WifiNoDevcCnnct_No_Actl : 47|8@0+ (1,0) [0|255] "unitless"  APIM_CISM,APIM
 SG_ WifiHtsptCnnct_D_Stat : 26|2@0+ (1,0) [0|3] "SED"  APIM_CISM,APIM
 SG_ Telematics_D_Falt : 39|3@0+ (1,0) [0|7] "SED"  APIM_CISM,APIM
 SG_ WifiEnbl_D_Stat : 4|2@0+ (1,0) [0|3] "SED"  APIM_CISM,APIM
 SG_ WifiHtsptVisbl_D_Stat : 13|2@0+ (1,0) [0|3] "SED"  APIM_CISM,APIM
 SG_ WifiHtsptScrty_D_Stat : 15|2@0+ (1,0) [0|3] "SED"  APIM_CISM,APIM
 SG_ WifiHtsptEnbl_D_Stat : 2|2@0+ (1,0) [0|3] "SED"  APIM_CISM,APIM
 SG_ WifiDevcListNew_B_Stat : 5|1@0+ (1,0) [0|1] "SED"  APIM_CISM,APIM
 SG_ WifiDataUsage_Pc_Actl : 20|4@0+ (5,50) [50|125] "percent"  APIM_CISM,APIM
 SG_ WifiDataUsage_D_Stat : 7|2@0+ (1,0) [0|3] "SED"  APIM_CISM,APIM
 SG_ ModemSigStren_D_Stat : 11|3@0+ (1,0) [0|7] "SED"  APIM_CISM,ACM,APIM
 SG_ ModemTechnology_D2_Stat : 31|3@0+ (1,0) [0|7] "SED"  HUD_ADV,APIM_CISM,APIM
 SG_ WifiHtsptCrdntl_B_Stat : 0|1@0+ (1,0) [0|1] "SED"  APIM,APIM_CISM
 SG_ WifiHtsptFq_D_Avail : 63|3@0+ (1,0) [0|7] "SED"  ACM,APIM,APIM_CISM
 SG_ WifiDataUsageOn_D_Stat : 28|2@0+ (1,0) [0|3] "SED"  APIM_CISM,APIM

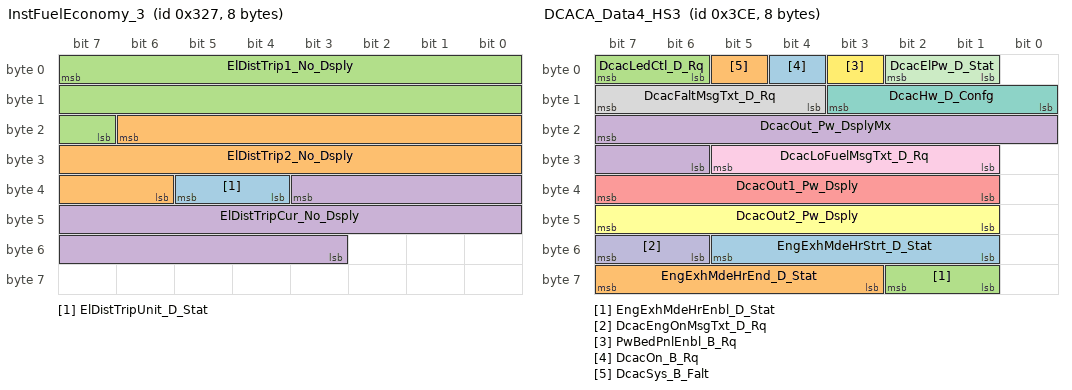
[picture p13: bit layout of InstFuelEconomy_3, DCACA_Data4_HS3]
BO_ 807 InstFuelEconomy_3: 8 IPC
 SG_ ElDistTripUnit_D_Stat : 37|2@0+ (1,0) [0|3] "SED"  APIM_CISM,APIM
 SG_ ElDistTrip2_No_Dsply : 22|17@0+ (0.1,0) [0|13107.1] "unitless"  APIM_CISM,APIM
 SG_ ElDistTrip1_No_Dsply : 7|17@0+ (0.1,0) [0|13107.1] "unitless"  APIM_CISM,APIM
 SG_ ElDistTripCur_No_Dsply : 35|17@0+ (0.1,0) [0|13107.1] "unitless"  APIM_CISM,APIM

BO_ 974 DCACA_Data4_HS3: 8 GWM
 SG_ EngExhMdeHrStrt_D_Stat : 53|5@0+ (1,0) [0|31] "SED"  APIM_CISM,APIM
 SG_ EngExhMdeHrEnd_D_Stat : 63|5@0+ (1,0) [0|31] "SED"  APIM_CISM,APIM
 SG_ EngExhMdeHrEnbl_D_Stat : 58|2@0+ (1,0) [0|3] "SED"  APIM_CISM,APIM
 SG_ DcacOut_Pw_DsplyMx : 23|10@0+ (10,0) [0|10220] "watts"  APIM_CISM,APIM
 SG_ DcacOut1_Pw_Dsply : 39|7@0+ (100,0) [0|12600] "watts"  APIM_CISM,APIM
 SG_ DcacOut2_Pw_Dsply : 47|7@0+ (100,0) [0|12600] "watts"  APIM_CISM,APIM
 SG_ DcacHw_D_Confg : 11|4@0+ (1,0) [0|15] "SED"  APIM_CISM,APIM
 SG_ DcacFaltMsgTxt_D_Rq : 15|4@0+ (1,0) [0|15] "SED"  APIM_CISM,APIM
 SG_ DcacLoFuelMsgTxt_D_Rq : 29|5@0+ (1,0) [0|31] "SED"  APIM_CISM,APIM
 SG_ DcacEngOnMsgTxt_D_Rq : 55|2@0+ (1,0) [0|3] "SED"  APIM_CISM,APIM
 SG_ DcacElPw_D_Stat : 2|2@0+ (1,0) [0|3] "SED"  APIM_CISM,APIM
 SG_ PwBedPnlEnbl_B_Rq : 3|1@0+ (1,0) [0|1] "SED"  GENERIC
 SG_ DcacOn_B_Rq : 4|1@0+ (1,0) [0|1] "SED"  GENERIC
 SG_ DcacSys_B_Falt : 5|1@0+ (1,0) [0|1] "SED"  GENERIC
 SG_ DcacLedCtl_D_Rq : 7|2@0+ (1,0) [0|3] "SED"  GWM

BO_ 805 InstFuelEconomy_2: 8 IPC
 SG_ InstFeTripUnit_D_Stat : 23|4@0+ (1,0) [0|15] "SED"  APIM_CISM,APIM
 SG_ InstFe_No_Dsply : 7|14@0+ (0.1,0) [0|1638.3] "unitless"  APIM_CISM,APIM

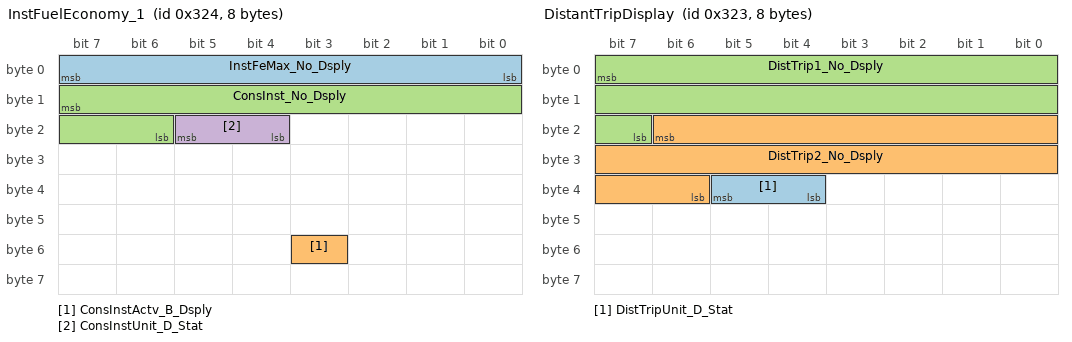
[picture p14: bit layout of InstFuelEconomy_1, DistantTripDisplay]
BO_ 804 InstFuelEconomy_1: 8 IPC
 SG_ InstFeMax_No_Dsply : 7|8@0+ (1,0) [0|255] "unitless"  APIM_CISM,APIM
 SG_ ConsInstActv_B_Dsply : 51|1@0+ (1,0) [0|1] "SED"  APIM_CISM,APIM
 SG_ ConsInst_No_Dsply : 15|10@0+ (0.1,0) [0|102.3] "percent"  APIM_CISM,APIM
 SG_ ConsInstUnit_D_Stat : 21|2@0+ (1,0) [0|3] "SED"  APIM_CISM,APIM

BO_ 803 DistantTripDisplay: 8 IPC
 SG_ DistTripUnit_D_Stat : 37|2@0+ (1,0) [0|3] "SED"  APIM_CISM,APIM
 SG_ DistTrip2_No_Dsply : 22|17@0+ (0.1,0) [0|13107.1] "unitless"  APIM_CISM,APIM
 SG_ DistTrip1_No_Dsply : 7|17@0+ (0.1,0) [0|13107.1] "unitless"  APIM_CISM,APIM

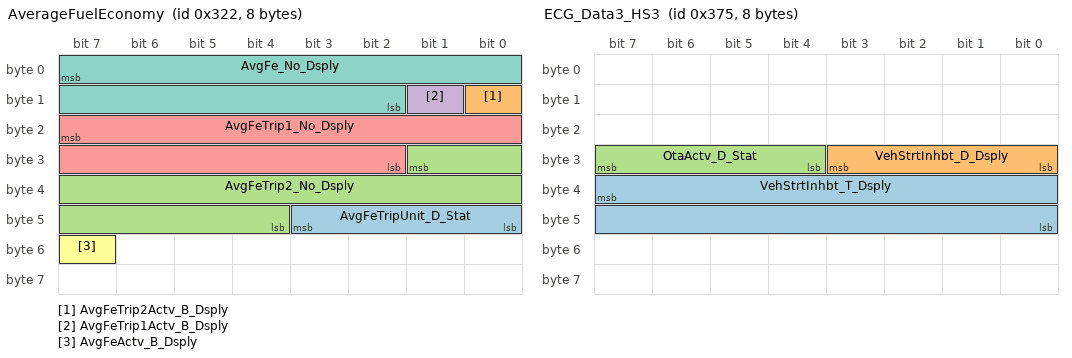
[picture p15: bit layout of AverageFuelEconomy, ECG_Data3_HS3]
BO_ 802 AverageFuelEconomy: 8 IPC
 SG_ AvgFeTripUnit_D_Stat : 43|4@0+ (1,0) [0|15] "SED"  APIM_CISM,APIM
 SG_ AvgFeTrip2Actv_B_Dsply : 8|1@0+ (1,0) [0|1] "SED"  APIM_CISM,APIM
 SG_ AvgFeTrip2_No_Dsply : 25|14@0+ (0.1,0) [0|1638.3] "unitless"  APIM_CISM,APIM
 SG_ AvgFeTrip1Actv_B_Dsply : 9|1@0+ (1,0) [0|1] "SED"  APIM_CISM,APIM
 SG_ AvgFeTrip1_No_Dsply : 23|14@0+ (0.1,0) [0|1638.3] "unitless"  APIM_CISM,APIM
 SG_ AvgFeActv_B_Dsply : 55|1@0+ (1,0) [0|1] "SED"  APIM_CISM,APIM
 SG_ AvgFe_No_Dsply : 7|14@0+ (0.1,0) [0|1638.3] "unitless"  APIM_CISM,APIM

BO_ 812 TimerDisplay_Data: 8 IPC
 SG_ TimerTrip2_T_Dsply : 29|26@0+ (1,0) [0|67108863] "second"  APIM_CISM,APIM
 SG_ TimerTrip1_T_Dsply : 7|26@0+ (1,0) [0|67108863] "second"  APIM_CISM,APIM

BO_ 885 ECG_Data3_HS3: 8 GWM
 SG_ VehStrtInhbt_T_Dsply : 39|16@0+ (1,0) [0|65535] "second"  IPC
 SG_ VehStrtInhbt_D_Dsply : 27|4@0+ (1,0) [0|15] "SED"  IPC
 SG_ OtaActv_D_Stat : 31|4@0+ (1,0) [0|15] "SED"  IPC

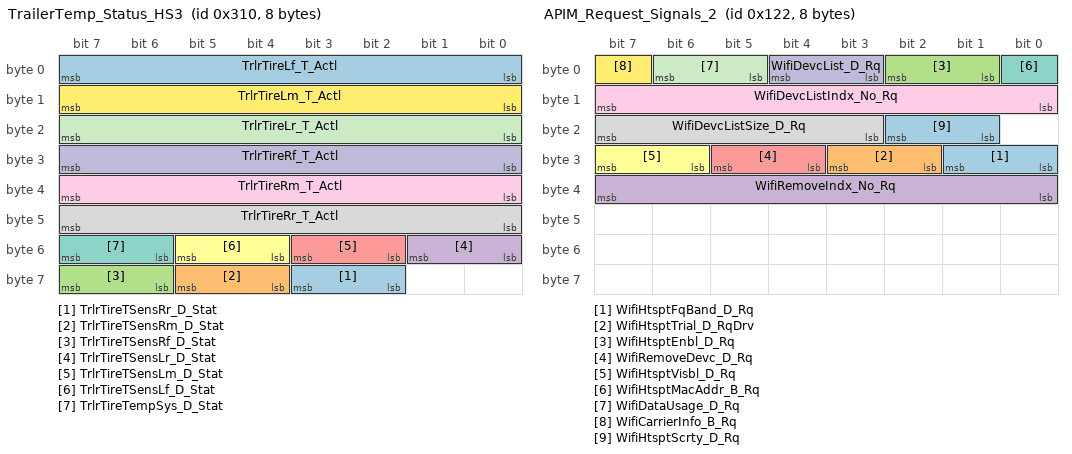
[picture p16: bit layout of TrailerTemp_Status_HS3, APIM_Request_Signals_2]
BO_ 784 TrailerTemp_Status_HS3: 8 GWM
 SG_ TrlrTireTSensRr_D_Stat : 59|2@0+ (1,0) [0|3] "SED"  IPC
 SG_ TrlrTireTSensRm_D_Stat : 61|2@0+ (1,0) [0|3] "SED"  IPC
 SG_ TrlrTireTSensRf_D_Stat : 63|2@0+ (1,0) [0|3] "SED"  IPC
 SG_ TrlrTireTSensLr_D_Stat : 49|2@0+ (1,0) [0|3] "SED"  IPC
 SG_ TrlrTireTSensLm_D_Stat : 51|2@0+ (1,0) [0|3] "SED"  IPC
 SG_ TrlrTireTSensLf_D_Stat : 53|2@0+ (1,0) [0|3] "SED"  IPC
 SG_ TrlrTireTempSys_D_Stat : 55|2@0+ (1,0) [0|3] "SED"  IPC
 SG_ TrlrTireRr_T_Actl : 47|8@0+ (1,-60) [-60|193] "degC"  IPC
 SG_ TrlrTireRm_T_Actl : 39|8@0+ (1,-60) [-60|193] "degC"  IPC
 SG_ TrlrTireRf_T_Actl : 31|8@0+ (1,-60) [-60|193] "degC"  IPC
 SG_ TrlrTireLr_T_Actl : 23|8@0+ (1,-60) [-60|193] "degC"  IPC
 SG_ TrlrTireLm_T_Actl : 15|8@0+ (1,-60) [-60|193] "degC"  IPC
 SG_ TrlrTireLf_T_Actl : 7|8@0+ (1,-60) [-60|193] "degC"  IPC

BO_ 1119 LocationServices_Data2: 8 APIM
 SG_ LocationServices_2 : 7|64@0+ (1,0) [0|1.84467440737096E+019] "unitless"  IPC,GWM

BO_ 1118 LocationServices_Data1: 8 APIM
 SG_ LocationServices_1 : 7|64@0+ (1,0) [0|1.84467440737096E+019] "unitless"  IPC,GWM

BO_ 290 APIM_Request_Signals_2: 8 APIM
 SG_ WifiHtsptFqBand_D_Rq : 25|2@0+ (1,0) [0|3] "SED"  GWM
 SG_ WifiHtsptTrial_D_RqDrv : 27|2@0+ (1,0) [0|3] "SED"  GWM
 SG_ WifiHtsptEnbl_D_Rq : 2|2@0+ (1,0) [0|3] "SED"  GWM
 SG_ WifiRemoveIndx_No_Rq : 39|8@0+ (1,0) [0|255] "unitless"  GWM
 SG_ WifiRemoveDevc_D_Rq : 29|2@0+ (1,0) [0|3] "SED"  GWM
 SG_ WifiHtsptVisbl_D_Rq : 31|2@0+ (1,0) [0|3] "SED"  GWM
 SG_ WifiHtsptMacAddr_B_Rq : 0|1@0+ (1,0) [0|1] "SED"  GWM
 SG_ WifiDevcListSize_D_Rq : 23|5@0+ (1,0) [0|31] "unitless"  GWM
 SG_ WifiDevcListIndx_No_Rq : 15|8@0+ (1,0) [0|255] "unitless"  GWM
 SG_ WifiDevcList_D_Rq : 4|2@0+ (1,0) [0|3] "SED"  GWM
 SG_ WifiDataUsage_D_Rq : 6|2@0+ (1,0) [0|3] "SED"  GWM
 SG_ WifiCarrierInfo_B_Rq : 7|1@0+ (1,0) [0|1] "SED"  GWM
 SG_ WifiHtsptScrty_D_Rq : 18|2@0+ (1,0) [0|3] "SED"  GWM

BO_ 2612101336 PARSEDPushFcGWMtoIPC: 8 GWM
 SG_ PARSEDPushFcGWM_ECGtoIPC : 7|29@0+ (1,0) [0|536870911] "unitless"  IPC

BO_ 1043 ABS_BrkData_HS3: 8 GWM
 SG_ SelDrvMdeHmi02_D_Rq : 47|5@0+ (1,0) [0|31] "SED"  APIM_CISM,APIM,HUD_ADV,IPC
 SG_ SelDrvMdeHmi04_D_Rq : 55|5@0+ (1,0) [0|31] "SED"  APIM_CISM,ACM,DACMC
 SG_ IndvMdeSusp_No_Stat : 27|4@0+ (1,0) [0|15] "unitless"  IPC
 SG_ IndvMdeSte_No_Stat : 31|4@0+ (1,0) [0|15] "unitless"  IPC
 SG_ IndvMdeSel_No_Rq : 19|4@0+ (1,0) [0|15] "unitless"  IPC
 SG_ IndvMdeSel_D_Stat : 9|2@0+ (1,0) [0|3] "SED"  IPC
 SG_ IndvMdeMsgTxt_D_Rq : 23|4@0+ (1,0) [0|15] "SED"  IPC
 SG_ IndvMde5_B_Avail : 35|1@0+ (1,0) [0|1] "SED"  IPC
 SG_ IndvMde4_B_Avail : 36|1@0+ (1,0) [0|1] "SED"  IPC
 SG_ IndvMde3_B_Avail : 37|1@0+ (1,0) [0|1] "SED"  IPC
 SG_ IndvMde2_B_Avail : 38|1@0+ (1,0) [0|1] "SED"  IPC
 SG_ IndvMde1_B_Avail : 39|1@0+ (1,0) [0|1] "SED"  IPC
 SG_ TrailOnePdlMde_D_Ind : 15|3@0+ (1,0) [0|7] "SED"  IPC
 SG_ TrailOnePdlMsgTxt_D_Rq : 12|3@0+ (1,0) [0|7] "SED"  IPC
 SG_ OrtaSwtchLamp_B_Rq : 0|1@0+ (1,0) [0|1] "SED"  APIM,APIM_CISM
 SG_ OrtaMsgTxt_D_Rq : 4|4@0+ (1,0) [0|15] "SED"  IPC
 SG_ OrtaMde_D_Ind : 7|3@0+ (1,0) [0|7] "SED"  IPC

BO_ 813 TimerDisplay_Data2: 8 IPC
 SG_ TimerTripCurnt_T_Dsply : 7|26@0+ (1,0) [0|67108863] "second"  APIM,APIM_CISM

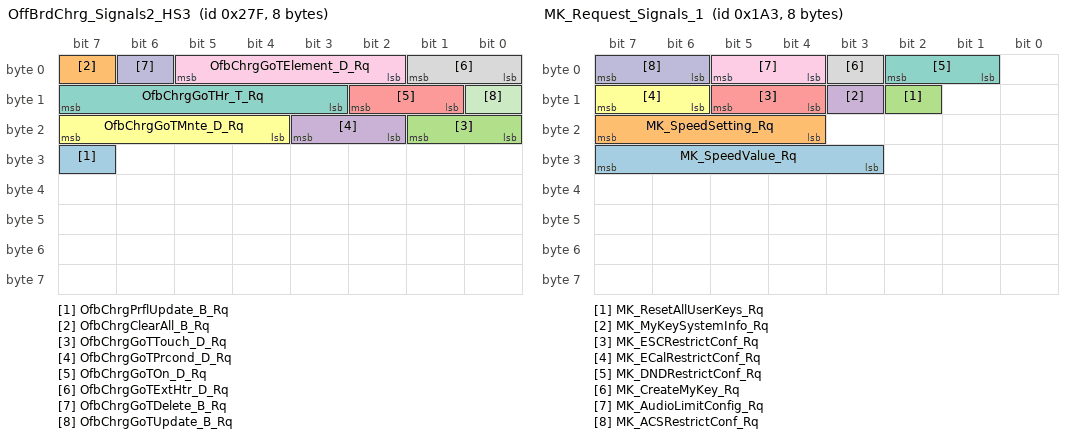
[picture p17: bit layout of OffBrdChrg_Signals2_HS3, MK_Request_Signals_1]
BO_ 639 OffBrdChrg_Signals2_HS3: 8 GWM
 SG_ OfbChrgPrflUpdate_B_Rq : 31|1@0+ (1,0) [0|1] "SED"  APIM_CISM,APIM
 SG_ OfbChrgClearAll_B_Rq : 7|1@0+ (1,0) [0|1] "SED"  GENERIC
 SG_ OfbChrgGoTTouch_D_Rq : 17|2@0+ (1,0) [0|3] "SED"  GENERIC
 SG_ OfbChrgGoTPrcond_D_Rq : 19|2@0+ (1,0) [0|3] "SED"  GENERIC
 SG_ OfbChrgGoTOn_D_Rq : 10|2@0+ (1,0) [0|3] "SED"  GENERIC
 SG_ OfbChrgGoTMnte_D_Rq : 23|4@0+ (1,0) [0|15] "minute"  GENERIC
 SG_ OfbChrgGoTHr_T_Rq : 15|5@0+ (1,0) [0|29] "hour"  GENERIC
 SG_ OfbChrgGoTExtHtr_D_Rq : 1|2@0+ (1,0) [0|3] "SED"  GENERIC
 SG_ OfbChrgGoTElement_D_Rq : 5|4@0+ (1,0) [0|15] "Unitless"  GENERIC
 SG_ OfbChrgGoTDelete_B_Rq : 6|1@0+ (1,0) [0|1] "SED"  GENERIC
 SG_ OfbChrgGoTUpdate_B_Rq : 8|1@0+ (1,0) [0|1] "SED"  APIM_CISM,APIM

BO_ 419 MK_Request_Signals_1: 8 APIM
 SG_ MK_SpeedValue_Rq : 31|5@0+ (1,0) [0|31] "SED"  IPC
 SG_ MK_SpeedSetting_Rq : 23|4@0+ (1,0) [0|15] "SED"  IPC
 SG_ MK_ResetAllUserKeys_Rq : 10|1@0+ (1,0) [0|1] "SED"  IPC
 SG_ MK_MyKeySystemInfo_Rq : 11|1@0+ (1,0) [0|1] "SED"  IPC
 SG_ MK_ESCRestrictConf_Rq : 13|2@0+ (1,0) [0|3] "SED"  IPC
 SG_ MK_ECalRestrictConf_Rq : 15|2@0+ (1,0) [0|3] "SED"  IPC
 SG_ MK_DNDRestrictConf_Rq : 2|2@0+ (1,0) [0|3] "SED"  IPC
 SG_ MK_CreateMyKey_Rq : 3|1@0+ (1,0) [0|1] "SED"  IPC
 SG_ MK_AudioLimitConfig_Rq : 5|2@0+ (1,0) [0|3] "SED"  IPC
 SG_ MK_ACSRestrictConf_Rq : 7|2@0+ (1,0) [0|3] "SED"  IPC

BO_ 542 LocationServices_3_HS3: 8 GWM
 SG_ LocationServices_3 : 7|64@0+ (1,0) [0|1.84467440737096E+019] "unitless"  APIM_CISM,IPC,APIM,ACM

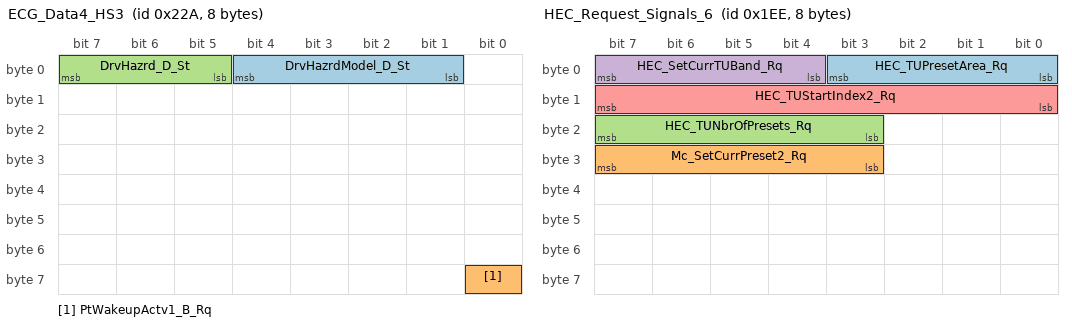
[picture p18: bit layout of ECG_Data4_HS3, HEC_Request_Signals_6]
BO_ 554 ECG_Data4_HS3: 8 GWM
 SG_ DrvHazrdModel_D_St : 4|4@0+ (1,0) [0|15] "SED"  APIM_CISM,APIM,IPC
 SG_ PtWakeupActv1_B_Rq : 56|1@0+ (1,0) [0|1] "SED"  APIM_CISM,APIM
 SG_ DrvHazrd_D_St : 7|3@0+ (1,0) [0|7] "SED"  APIM_CISM,APIM,IPC

BO_ 494 HEC_Request_Signals_6: 8 IPC
 SG_ HEC_TUPresetArea_Rq : 3|4@0+ (1,0) [0|15] "SED"  APIM_CISM,ACM
 SG_ Mc_SetCurrPreset2_Rq : 31|5@0+ (1,0) [0|30] "SED"  APIM_CISM,ACM
 SG_ HEC_TUNbrOfPresets_Rq : 23|5@0+ (1,0) [0|30] "unitless"  APIM_CISM,ACM
 SG_ HEC_SetCurrTUBand_Rq : 7|4@0+ (1,0) [0|15] "SED"  APIM_CISM,ACM
 SG_ HEC_TUStartIndex2_Rq : 15|8@0+ (1,0) [0|255] "unitless"  APIM_CISM,ACM

BO_ 714 SDARS_MC_WORD_Rx: 8 IPC
 SG_ SDARS_MC_WORD_Rx : 7|64@0+ (1,0) [0|1.84467440737096E+019] "unitless"  APIM_CISM,ACM

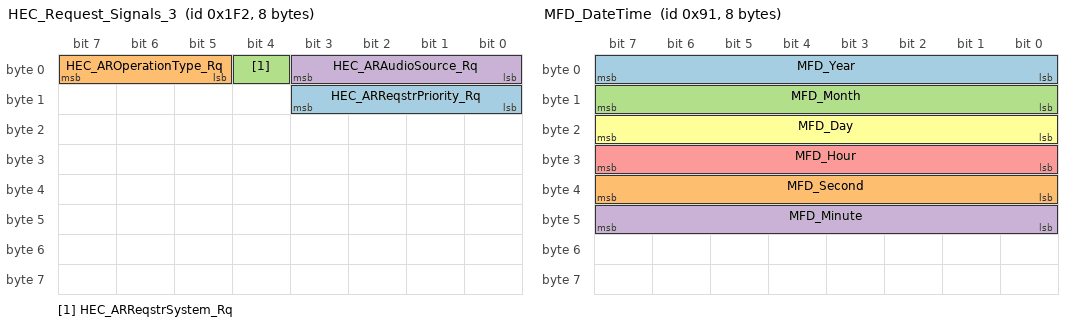
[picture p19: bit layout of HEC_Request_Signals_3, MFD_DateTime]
BO_ 498 HEC_Request_Signals_3: 8 IPC
 SG_ HEC_ARReqstrPriority_Rq : 11|4@0+ (1,0) [0|15] "SED"  APIM_CISM,ACM
 SG_ HEC_AROperationType_Rq : 7|3@0+ (1,0) [0|7] "SED"  APIM_CISM,ACM
 SG_ HEC_ARReqstrSystem_Rq : 4|1@0+ (1,0) [0|1] "SED"  APIM_CISM,ACM
 SG_ HEC_ARAudioSource_Rq : 3|4@0+ (1,0) [0|15] "SED"  APIM_CISM,ACM

BO_ 644 GWM_Send_Signals_19_HS3: 8 GWM
 SG_ VehOnSrc_D_Stat_UB : 3|1@0+ (1,0) [0|1] "SED"  APIM_CISM,APIM,IPC
 SG_ VehOnSrc_D_Stat : 7|4@0+ (1,0) [0|15] "SED"  APIM_CISM,APIM,IPC

BO_ 643 GWM_Send_Signals_18_HS3: 8 GWM
 SG_ StrtInGearMsgTxt_D_Rq_UB : 48|1@0+ (1,0) [0|1] "SED"  IPC
 SG_ StrtInGearMsgTxt_D_Rq : 59|4@0+ (1,0) [0|15] "SED"  IPC
 SG_ StabBarCnnct_D_Stat_UB : 49|1@0+ (1,0) [0|1] "SED"  APIM_CISM,APIM
 SG_ StabBarCnnct_D_Stat : 63|4@0+ (1,0) [0|15] "SED"  APIM_CISM,APIM
 SG_ FstChrgCmplt_T_Est : 33|10@0+ (1,0) [0|1023] "minute"  APIM_CISM,APIM,IPC
 SG_ GearPos_D_Trg_UB : 23|1@0+ (1,0) [0|1] "SED"  APIM_CISM,APIM
 SG_ GearPos_D_Trg : 11|4@0+ (1,0) [0|15] "SED"  APIM_CISM,APIM
 SG_ PwTgateStepMsgTxt_B_Rq : 13|1@0+ (1,0) [0|1] "SED"  IPC
 SG_ PwTgateStepMsgTxt_B_Rq_UB : 12|1@0+ (1,0) [0|1] "SED"  IPC
 SG_ PwTgateMsgTxt_B_Rq_UB : 14|1@0+ (1,0) [0|1] "SED"  IPC
 SG_ PwTgateLamp_B_Rq_UB : 0|1@0+ (1,0) [0|1] "SED"  IPC
 SG_ PwTgateMsgTxt_B_Rq : 15|1@0+ (1,0) [0|1] "SED"  IPC
 SG_ PwTgateLamp_B_Rq : 1|1@0+ (1,0) [0|1] "SED"  IPC
 SG_ PwRnngBoardSwtch_D_Stat_UB : 5|1@0+ (1,0) [0|1] "SED"  APIM_CISM,IPC,APIM
 SG_ PwRnngBoardT_D_Stat_UB : 2|1@0+ (1,0) [0|1] "SED"  APIM_CISM,IPC,APIM
 SG_ PwRnngBoardT_D_Stat : 4|2@0+ (1,0) [0|3] "SED"  APIM_CISM,IPC,APIM
 SG_ PwRnngBoardSwtch_D_Stat : 7|2@0+ (1,0) [0|3] "SED"  APIM_CISM,IPC,APIM
 SG_ OnePdlDrvLamp_B_Rq_UB : 52|1@0+ (1,0) [0|1] "SED"  IPC
 SG_ OnePdlDrv_D_Dsply_UB : 53|1@0+ (1,0) [0|1] "SED"  APIM_CISM,IPC,APIM
 SG_ OnePdlDrvLamp_B_Rq : 34|1@0+ (1,0) [0|1] "SED"  IPC
 SG_ OnePdlDrv_D_Dsply : 55|2@0+ (1,0) [0|3] "SED"  APIM_CISM,IPC,APIM
 SG_ SeatSlprPosMsgTxt_B_Rq_UB : 50|1@0+ (1,0) [0|1] "SED"  IPC
 SG_ SeatSlprPosMsgTxt_B_Rq : 51|1@0+ (1,0) [0|1] "SED"  IPC
 SG_ DrPrsntRearPsngr_D_Stat_UB : 36|1@0+ (1,0) [0|1] "SED"  IPC
 SG_ DrPrsntPsngr_D_Stat_UB : 37|1@0+ (1,0) [0|1] "SED"  IPC
 SG_ DrPsngrMsgTxt_B_Rq_UB : 38|1@0+ (1,0) [0|1] "SED"  IPC
 SG_ DrPsngrMsgTxt_B_Rq : 39|1@0+ (1,0) [0|1] "SED"  IPC
 SG_ DrPrsntRearPsngr_D_Stat : 25|2@0+ (1,0) [0|3] "SED"  IPC
 SG_ DrPrsntPsngr_D_Stat : 27|2@0+ (1,0) [0|3] "SED"  IPC
 SG_ DrPrsntRearDrv_D_Stat_UB : 30|1@0+ (1,0) [0|1] "SED"  IPC
 SG_ DrDrvMsgTxt_B_Rq_UB : 28|1@0+ (1,0) [0|1] "SED"  IPC
 SG_ DrPrsntDrv_D_Stat_UB : 31|1@0+ (1,0) [0|1] "SED"  IPC
 SG_ DrPrsntDrv_D_Stat : 19|2@0+ (1,0) [0|3] "SED"  IPC
 SG_ DrPrsntRearDrv_D_Stat : 17|2@0+ (1,0) [0|3] "SED"  IPC
 SG_ DrDrvMsgTxt_B_Rq : 29|1@0+ (1,0) [0|1] "SED"  IPC
 SG_ FstChrgCmplt_T_Est_UB : 35|1@0+ (1,0) [0|1] "SED"  APIM_CISM,APIM,IPC
 SG_ TrunkFrontOpen_D_Stat_UB : 20|1@0+ (1,0) [0|1] "SED"  APIM_CISM,APIM
 SG_ TrunkFrontOpen_D_Stat : 22|2@0+ (1,0) [0|3] "SED"  APIM_CISM,APIM

BO_ 145 MFD_DateTime: 8 APIM
 SG_ MFD_Year : 7|8@0+ (1,2000) [2000|2254] "year"  DSP,IPC,RACM_RCIM
 SG_ MFD_Second : 39|8@0+ (1,0) [0|59] "second"  DSP,IPC,RACM_RCIM
 SG_ MFD_Month : 15|8@0+ (1,0) [0|12] "month"  DSP,IPC,RACM_RCIM
 SG_ MFD_Minute : 47|8@0+ (1,0) [0|59] "minute"  DSP,IPC,RACM_RCIM
 SG_ MFD_Hour : 31|8@0+ (1,0) [0|23] "hour"  DSP,IPC,RACM_RCIM
 SG_ MFD_Day : 23|8@0+ (1,0) [0|31] "day"  DSP,IPC,RACM_RCIM

BO_TX_BU_ 715 : APIM_CISM,APIM;
BO_TX_BU_ 473 : APIM_CISM,APIM;
BO_TX_BU_ 482 : APIM_CISM,APIM;
BO_TX_BU_ 764 : APIM_CISM,APIM;
BO_TX_BU_ 1202 : APIM_CISM,APIM;
BO_TX_BU_ 1210 : APIM_CISM,ACM;
BO_TX_BU_ 391 : APIM_CISM,ACM;
BO_TX_BU_ 695 : APIM_CISM,APIM;
BO_TX_BU_ 501 : APIM_CISM,APIM;
BO_TX_BU_ 1506 : APIM_CISM,APIM;
BO_TX_BU_ 718 : APIM_CISM,APIM;
BO_TX_BU_ 672 : GWM,FCIMB;
BO_TX_BU_ 816 : APIM_CISM,APIM;
BO_TX_BU_ 1119 : APIM_CISM,APIM;
BO_TX_BU_ 1118 : APIM_CISM,APIM;
BO_TX_BU_ 290 : APIM_CISM,APIM;
BO_TX_BU_ 419 : APIM_CISM,APIM;
BO_TX_BU_ 145 : APIM_CISM,APIM;
CM_ SG_ 473 NAV_SetAFMode_Rq "Object Tuner.SetAFMode";
CM_ SG_ 473 NAV_StorePreset_Rq "Object Tuner.StorePreset

NOTE: If used on CANalyzer/CANoe for the older DENSO HighNav System, wrong values will be shown!";
CM_ SG_ 473 NAV_SetTUServiceLink_Rq "Object Tuner.NAV_SetTUServiceLink_Rq";
CM_ SG_ 473 NAV_SetTAMode_Rq "Object Tuner.SetTAMode";
CM_ SG_ 473 NAV_SetReg_Rq "Object Tuner.SetREG";
CM_ SG_ 473 NAV_SelectPTYCodeSet_Rq "Object Tuner.SelectPTYCodes

Set PTY code with the follow bit encoding";
CM_ SG_ 473 NAV_SelectPTYCodes_Rq "Object Tuner.SelectPTYCodes

28 bit bitfield where each PTY code can be set separately:
Bit 0:  0:  PTY Code 2 not selected; 1:  PTY Code 2 selected
...
Bit 27: PTY Code 29 not selected; 1:  PTY Code 29 selected";
CM_ SG_ 473 NAV_CDSetShuffle_Rq "Object Single CD.SetShuffle";
CM_ SG_ 473 NAV_CDSetRepeat_Rq "Object Single CD.SetRepeat";
CM_ SG_ 473 NAV_CDSetIntroScan_Rq "Object Single CD.SetIntroScan";
CM_ SG_ 482 SDARS_Firm_Update2_St "Object Tuner.SDARS Tuner.FirmwareUpdate";
CM_ SG_ 482 SDARS_UnSubscrb_Chan2_St "Object Tuner.SDARS Tuner.Unsubscribed Channel ";
CM_ SG_ 482 SDARS_UnSubscrb2_St "Object Tuner.SDARS Tuner.Unsubscribed Receiver ";
CM_ SG_ 482 SDARS_Subscription2_St "Object Tuner.SDARS Tuner.Subscription Update ";
CM_ SG_ 482 SDARS_Seek_Scan2_St "Method SDARS_Error_Msg
Int Seek/Scan No Channels Available

0x1: No Channel Available
Object Tuner.SDARS Tuner.";
CM_ SG_ 482 SDARS_Receive_Err2_St "Object Tuner.SDARS Tuner.Receiver Error";
CM_ SG_ 482 SDARS_Loss_Ant2_St "Object Tuner.SDARS Tuner.Loss of Antenna Signal ";
CM_ SG_ 482 SDARS_Invalid_Chan2_St "Object Tuner.SDARS Tuner.";
CM_ SG_ 482 SDARS_GCI_Update2_St "Object Tuner.SDARS Tuner.GCI Update ";
CM_ SG_ 482 SDARS_Error_Conf2_St "Object Tuner.SDARS Tuner.Configuration Status";
CM_ SG_ 482 SDARS_Antenna_Err2_St "Object Tuner.SDARS Tuner.Antenna Error";
CM_ SG_ 764 SDARS_SID2_St "Object Tuner.SDARS.ServiceID
$0: SID_0
$1: SID_1
$2: SID_2
$FE: SID_254
$FF: SID_255

";
CM_ SG_ 764 SDARS_CurrentChanNum2_St "Object Tuner.SDARS Tuner.CurrentChanNum.ChanNum 
$0: Channel_0
$1: Channel_1
$2: Channel_2
$FE: Channel_254
$FF: Inactive";
CM_ SG_ 764 SDARS_Channel_Lock2 "Method SDARS_Channel_Lock";
CM_ BO_ 710 "TP message(Transport Protocol), Rx's HS3 APIM & MFD, transmitted immediately";
CM_ SG_ 391 ACU_CtrlChimeChan_Rq "Object BodyInterface.StdChimeIF.ControlChimeChannel.Rq";
CM_ SG_ 415 LBC3_StartItemInd "Object. ListBrowser.ItemInf.Rq.StartItemInd
0x0000:Inactive
0x0001:1
0xFFFE:65634
0xFFFF:Reserved";
CM_ SG_ 415 LBC3_SetListServ "Object. ListBrowser.ItemInf.Rq.SetListServ
0x00:Inactive
0x01:ServerID_1
0xFF:ALL";
CM_ SG_ 415 LBC3_Opcode "Object. ListBrowser.ItemInf.Rq.Opcode";
CM_ SG_ 415 LBC3_NbrOfItems "Object. ListBrowser.ItemInf.Rq.NbrOfItems
0x00:Inactive
0x01:1Item
0x3F:63Items";
CM_ SG_ 415 LBC3_ItemIndex "Object. ListBrowser.ItemInf.Rq.ItemIndex
0x0000:BrowseActiveListID
0x0001:EntryIndex_1
0xFFFF:ParentOfActiveListID";
CM_ SG_ 415 LBC3_ActiveListID "Object. ListBrowser.ItemInf.Rq.ActiveListID
0x0000:Root
0xFFFF:Reserved";
CM_ SG_ 703 CONMP_MC_WORD_Rx "MM ISO 15765-2 Message Catalogue
Section CONMP - MC
Section MediaPlayerServer - MediaPlayerClient";
CM_ SG_ 695 CONMP_MC_WORD_Tx "MM ISO 15765-2 Message Catalogue
Section CONMP - MC
Section MediaPlayerServer - MediaPlayerClient";
CM_ SG_ 501 Dsp_PresetArea_Rq "Object Tuner.GetPresetInfo2.PresetArea

$5: Get AMAST (MW) Preset Data
$6: Get AM (LW) Preset Data";
CM_ SG_ 501 Dsp_StartIndex2_Rq "Object Tuner.GetPresetInfo2.StartingIndex

$1-$FF: Preset 1 to 255";
CM_ SG_ 501 Dsp_SetRadSeekMode_Rq "Object Tuner.SetRadioSeekMode";
CM_ SG_ 501 Dsp_SetCurrPreset2_Rq "Object Tuner.SetCurrentPreset2

$1-$1E: Preset 1 to 30
$0: Inactive
";
CM_ SG_ 501 Dsp_SetCurrFMSLPr_Rq "Object.AMFMSlave.SetCurrentSLStation.Rq.Index
0x01 : Index 1
0x02 : Index 2
0x03 : Index 3
...
...
0xFE : Index 254";
CM_ SG_ 501 Dsp_SetCRadioBand_Rq "Object Tuner.SetCurrRadioBand
$5: AM (LLN, HLN: MW)
$6: AM AST (LLN, HLN: LW)";
CM_ BO_ 651 "TCU CPPM Tx";
CM_ SG_ 629 GearPos_D_Actl "Powersplit HEVs with HF45, HPCM will Tx  this message.  For all other programs it will be Tx by PCM or TCM. ";
CM_ SG_ 629 TrnRng_D_Rq "Powersplit HEVs with HF45, HPCM will Tx  this message.  For all other programs it will be Tx by PCM or TCM. ";
CM_ SG_ 672 BCP_Audible_Beep_Rq "Object.AlertMethod.BCP_Audible_Beep";
CM_ SG_ 672 SetVolume "$0: -30Steps
$1: -29Steps
$2: -28Steps
$1D: -1Step
$1E: NotPressed_Inactive
$1F: +1Step
$20: +2Steps
$21: +3Steps
$3C: +30Steps";
CM_ SG_ 672 SetPointVolume "Method: EFP_Button_Press
0x0:Inactive
$0: Inactive
$1: No_Volume
$2: Volume_Step1
$3: Vol_Step2
$1F: Vol_Step30";
CM_ SG_ 672 Coding_BtnID_D "Object InputControlInterface ICI ButtonCoding_D
Object InputControlInterface ICI ButtonID_D";
CM_ SG_ 672 Coding_BtnID_C "Object InputControlInterface.ICI ButtonCoding_C
Object InputControlInterface.ICI ButtonID_C";
CM_ SG_ 672 Coding_BtnID_B "Object InputControlInterface ICI ButtonCoding_B
Object InputControlInterface.ICI ButtonID_B";
CM_ SG_ 672 Coding_BtnID_A "Object InputControlInterface ICI ButtonCoding_A
Object InputControlInterface.ICI ButtonID A";
CM_ SG_ 672 BtnID_D "Object InputControlInterface ICI ButtonID_D... 0xFF: Inactive";
CM_ SG_ 672 BtnID_C "Object InputControlInterface ICI ButtonID_D... 0xFF: Inactive";
CM_ SG_ 672 BtnID_B "Object InputControlInterface ICI ButtonID_D... 0xFF: Inactive";
CM_ SG_ 672 BtnID_A "Object InputControlInterface ICI ButtonID_D... 0xFF: Inactive";
CM_ BO_ 885 "NOTE: START BITS 8-11 MUST BE OPEN SPEC REQUIREMENT";
CM_ SG_ 1119 LocationServices_2 "Tx by HS3 APIM";
CM_ SG_ 1118 LocationServices_1 "Tx by HS3 APIM";
CM_ SG_ 419 MK_SpeedValue_Rq "Object MyKey.1 SpeedSettingConfig_Rq.SpeedValue (Parameter2)";
CM_ SG_ 419 MK_SpeedSetting_Rq "Object MyKey.1 SpeedSettingConfig_Rq.SpeedSetting (Parameter1)";
CM_ SG_ 419 MK_ResetAllUserKeys_Rq "Object MyKey.ResetAllKeys_Rq";
CM_ SG_ 419 MK_MyKeySystemInfo_Rq "Object MyKey.MyKeySystemInfo_Rq";
CM_ SG_ 419 MK_ESCRestrictConf_Rq "Object MyKey.ESCRestrictionConfig_Rq";
CM_ SG_ 419 MK_ECalRestrictConf_Rq "Object MyKey.ECallRestrictionConfig_Rq";
CM_ SG_ 419 MK_DNDRestrictConf_Rq "Object MyKey.DNDRestrictionConfig_Rq";
CM_ SG_ 419 MK_CreateMyKey_Rq "Object MyKey.CreateMyKey_Rq";
CM_ SG_ 419 MK_AudioLimitConfig_Rq "Object MyKey.AudioLimitConfig_Rq";
CM_ SG_ 419 MK_ACSRestrictConf_Rq "Object MyKey.ACSRestrictionConfig_Rq";
CM_ SG_ 542 LocationServices_3 "Tx by HS3 APIM";
CM_ BO_ 554 "TCU_CPPM Tx";
CM_ SG_ 554 PtWakeupActv1_B_Rq "ECG Application signal";
CM_ SG_ 494 HEC_TUPresetArea_Rq "Object Tuner.GetTUPresetInfo.PresetArea

$5: Get AMAST (MW) Preset Data
$6: Get AM (LW) Preset Data";
CM_ SG_ 494 Mc_SetCurrPreset2_Rq "Object Tuner.SetCurrentPreset2

$1-$1E: Preset 1 to 30
$0: Inactive
";
CM_ SG_ 494 HEC_TUNbrOfPresets_Rq "Object Tuner.GetTUPresetInfo.NumberOfPresets

$1-$1E: Preset 1 to 30";
CM_ SG_ 494 HEC_SetCurrTUBand_Rq "Object Tuner.SetCurrTUBand
$5: AM (LLN, HLN: MW)
$6: AM AST (LLN, HLN: LW)";
CM_ SG_ 494 HEC_TUStartIndex2_Rq "Object Tuner.GetTUPresetInfo.StartIndex2

$1-$FF: Preset 1 to 255";
CM_ SG_ 498 HEC_ARReqstrPriority_Rq "Object Audio Management Audio Client.AudioRequest.Requester Priority";
CM_ SG_ 498 HEC_AROperationType_Rq "Object Audio Management Audio Client.AudioRequest.Operation Type";
CM_ SG_ 498 HEC_ARReqstrSystem_Rq "Object Audio Management Audio Client.AudioRequest.Requester System";
CM_ SG_ 498 HEC_ARAudioSource_Rq "Object Audio Management Audio Client.AudioRequest.Requested Audio Source";
CM_ SG_ 643 GearPos_D_Trg "Powersplit HEVs with HF45, HPCM will Tx  this message.  For all other programs it will be Tx by PCM or TCM. ";
CM_ BO_ 145 "MFD Shall not send this message when configured as a slave

Method: Clock Modes";
CM_ SG_ 145 MFD_Year "Used by MFD to distribute actual Master Clock data to the Slave";
CM_ SG_ 145 MFD_Second "Used by MFD to distribute actual Master Clock data to the Slave";
CM_ SG_ 145 MFD_Month "Used by MFD to distribute actual Master Clock data to the Slave";
CM_ SG_ 145 MFD_Minute "Used by MFD to distribute actual Master Clock data to the Slave";
CM_ SG_ 145 MFD_Hour "Used by MFD to distribute actual Master Clock data to the Slave";
CM_ SG_ 145 MFD_Day "Used by MFD to distribute actual Master Clock data to the Slave";
BA_DEF_ BO_  "FrameRouting" STRING ;
BA_DEF_ BO_  "FrameGatewayNetwork" STRING ;
BA_DEF_ BO_  "NetworkInitialization" ENUM  "No","Yes";
BA_DEF_ BO_  "FrameGatewayId" HEX 0 1407;
BA_DEF_ BO_  "EventRateOfChange" INT 10 10000;
BA_DEF_ BO_  "GenMsgStartDelayTime" INT 0 10000;
BA_DEF_ BO_  "GenMsgNrOfRepetition" INT 0 100;
BA_DEF_ BO_  "GenMsgDelayTime" INT 0 1000;
BA_DEF_ BO_  "GenMsgCycleTime" INT 0 100000;
BA_DEF_ BO_  "GenMsgSendType" ENUM  "FixedPeriodic","Event","EnabledPeriodic","NotUsed","NotUsed","EventPeriodic","NotUsed","NotUsed","NoMsgSendType";
BA_DEF_ SG_  "U_U55X_MY2022_Tx" ENUM  "No","Yes";
BA_DEF_ SG_  "U_CD542_MY2021_Tx" ENUM  "No","Yes";
BA_DEF_ SG_  "ECGUsedTxSignal" ENUM  "No","Yes";
BA_DEF_ SG_  "U_T6_MCA_MY2020_Tx" ENUM  "No","Yes";
BA_DEF_ SG_  "U_P702_MY2021_Tx" ENUM  "No","Yes";
BA_DEF_ SG_  "U_CX727_MY2021_Tx" ENUM  "No","Yes";
BA_DEF_ SG_  "U_FNV2_IVI_Rx" ENUM  "No","Yes";
BA_DEF_ SG_  "U_U55X_MY2022_Rx" ENUM  "No","Yes";
BA_DEF_ SG_  "U_CD542_MY2021_Rx" ENUM  "No","Yes";
BA_DEF_ SG_  "ECGUsedRxSignal" ENUM  "No","Yes";
BA_DEF_ SG_  "U_T6_MCA_MY2020_Rx" ENUM  "No","Yes";
BA_DEF_ SG_  "U_P702_MY2021_Rx" ENUM  "No","Yes";
BA_DEF_ SG_  "U_CX727_MY2021_Rx" ENUM  "No","Yes";
BA_DEF_ SG_  "GenSigStartValue" HEX 0 268435455;
BA_DEF_ SG_  "MetaData" ENUM  "No","Yes";
BA_DEF_ SG_  "ContentDependant" ENUM  "No","Yes";
BA_DEF_ SG_  "GenSigStartValueInteger" INT 0 1000000000;
BA_DEF_ SG_  "UsedOnPgmDBC" ENUM  "No","Yes";
BA_DEF_ SG_  "WakeupSignal" ENUM  "No","Yes";
BA_DEF_ SG_  "GenSigInactiveValue" INT 0 100000;
BA_DEF_ SG_  "GenSigSendType" ENUM  "Cyclic","OnWrite","vector_leerstring","OnChange","vector_leerstring","IfActive","vector_leerstring","NoSigSendType";
BA_DEF_ BO_  "OvtpPushApplication" ENUM  "FALSE","TRUE";
BA_DEF_ BO_  "SCP_FreshnessValueLength" INT 0 512;
BA_DEF_ BO_  "SCP_FreshnessValueTxLength" INT 0 512;
BA_DEF_ BO_  "SCP_AuthInfoTxLength" INT 0 512;
BA_DEF_ BO_  "GenMsgRoutingTimeoutTime" INT 0 5000;
BA_DEF_ BO_  "MessageGateway" ENUM  "No","Yes";
BA_DEF_ BO_  "NmAsrMessage" ENUM  "No","Yes";
BA_DEF_ BO_  "DiagState" ENUM  "No","Yes";
BA_DEF_ BO_  "TpTxIndex" INT 0 536870911;
BA_DEF_ BO_  "DiagRequest" ENUM  "No","Yes";
BA_DEF_ BO_  "DiagResponse" ENUM  "No","Yes";
BA_DEF_ BO_  "GenMsgILSupport" ENUM  "No","Yes";
BA_DEF_DEF_  "FrameRouting" "";
BA_DEF_DEF_  "FrameGatewayNetwork" "NONE";
BA_DEF_DEF_  "NetworkInitialization" "Yes";
BA_DEF_DEF_  "FrameGatewayId" 0;
BA_DEF_DEF_  "EventRateOfChange" 10000;
BA_DEF_DEF_  "GenMsgStartDelayTime" 0;
BA_DEF_DEF_  "GenMsgNrOfRepetition" 1;
BA_DEF_DEF_  "GenMsgDelayTime" 20;
BA_DEF_DEF_  "GenMsgCycleTime" 0;
BA_DEF_DEF_  "GenMsgSendType" "NoMsgSendType";
BA_DEF_DEF_  "U_U55X_MY2022_Tx" "No";
BA_DEF_DEF_  "U_CD542_MY2021_Tx" "No";
BA_DEF_DEF_  "ECGUsedTxSignal" "No";
BA_DEF_DEF_  "U_T6_MCA_MY2020_Tx" "No";
BA_DEF_DEF_  "U_P702_MY2021_Tx" "No";
BA_DEF_DEF_  "U_CX727_MY2021_Tx" "No";
BA_DEF_DEF_  "U_FNV2_IVI_Rx" "No";
BA_DEF_DEF_  "U_U55X_MY2022_Rx" "No";
BA_DEF_DEF_  "U_CD542_MY2021_Rx" "No";
BA_DEF_DEF_  "ECGUsedRxSignal" "No";
BA_DEF_DEF_  "U_T6_MCA_MY2020_Rx" "No";
BA_DEF_DEF_  "U_P702_MY2021_Rx" "No";
BA_DEF_DEF_  "U_CX727_MY2021_Rx" "No";
BA_DEF_DEF_  "GenSigStartValue" 0;
BA_DEF_DEF_  "MetaData" "No";
BA_DEF_DEF_  "ContentDependant" "No";
BA_DEF_DEF_  "GenSigStartValueInteger" 0;
BA_DEF_DEF_  "UsedOnPgmDBC" "Yes";
BA_DEF_DEF_  "WakeupSignal" "No";
BA_DEF_DEF_  "GenSigInactiveValue" 0;
BA_DEF_DEF_  "GenSigSendType" "NoSigSendType";
BA_DEF_DEF_  "OvtpPushApplication" "FALSE";
BA_DEF_DEF_  "SCP_FreshnessValueLength" 64;
BA_DEF_DEF_  "SCP_FreshnessValueTxLength" 11;
BA_DEF_DEF_  "SCP_AuthInfoTxLength" 53;
BA_DEF_DEF_  "GenMsgRoutingTimeoutTime" 0;
BA_DEF_DEF_  "MessageGateway" "No";
BA_DEF_DEF_  "NmAsrMessage" "No";
BA_DEF_DEF_  "DiagState" "No";
BA_DEF_DEF_  "TpTxIndex" 0;
BA_DEF_DEF_  "DiagRequest" "No";
BA_DEF_DEF_  "DiagResponse" "No";
BA_DEF_DEF_  "GenMsgILSupport" "Yes";
BA_ "FrameGatewayId" BO_ 884 884;
BA_ "FrameGatewayNetwork" BO_ 884 "MS1_CAN";
BA_ "FrameRouting" BO_ 884 "MS1_CAN,0x374;";
BA_ "FrameGatewayId" BO_ 883 883;
BA_ "FrameGatewayNetwork" BO_ 883 "MS1_CAN";
BA_ "FrameRouting" BO_ 883 "MS1_CAN,0x373;";
BA_ "FrameRouting" BO_ 1090 "FD1_CAN,0x442;HS1_CAN,0x442";
BA_ "GenMsgSendType" BO_ 677 5;
BA_ "GenMsgCycleTime" BO_ 677 1000;
BA_ "FrameGatewayId" BO_ 1238 1238;
BA_ "FrameGatewayNetwork" BO_ 1238 "FD1_CAN";
BA_ "FrameRouting" BO_ 1238 "FD1_CAN,0x4D6;";
BA_ "FrameGatewayId" BO_ 1041 1041;
BA_ "FrameGatewayNetwork" BO_ 1041 "HS1_CAN";
BA_ "FrameRouting" BO_ 1041 "HS1_CAN,0x411;";
BA_ "TpTxIndex" BO_ 2609971416 462487768;
BA_ "GenMsgSendType" BO_ 2609971416 1;
BA_ "GenMsgDelayTime" BO_ 2609971416 0;
BA_ "NetworkInitialization" BO_ 2609971416 0;
BA_ "TpTxIndex" BO_ 2610126912 462487768;
BA_ "GenMsgSendType" BO_ 2610126912 1;
BA_ "GenMsgDelayTime" BO_ 2610126912 0;
BA_ "NetworkInitialization" BO_ 2610126912 0;
BA_ "TpTxIndex" BO_ 2611019992 463536344;
BA_ "GenMsgSendType" BO_ 2611019992 1;
BA_ "GenMsgDelayTime" BO_ 2611019992 0;
BA_ "NetworkInitialization" BO_ 2611019992 0;
BA_ "TpTxIndex" BO_ 2611175488 463536344;
BA_ "GenMsgSendType" BO_ 2611175488 1;
BA_ "GenMsgDelayTime" BO_ 2611175488 0;
BA_ "NetworkInitialization" BO_ 2611175488 0;
BA_ "TpTxIndex" BO_ 2612068568 464584920;
BA_ "OvtpPushApplication" BO_ 2612068568 1;
BA_ "GenMsgSendType" BO_ 2612068568 1;
BA_ "GenMsgDelayTime" BO_ 2612068568 0;
BA_ "NetworkInitialization" BO_ 2612068568 0;
BA_ "TpTxIndex" BO_ 2612224064 464584920;
BA_ "GenMsgSendType" BO_ 2612224064 1;
BA_ "GenMsgDelayTime" BO_ 2612224064 0;
BA_ "NetworkInitialization" BO_ 2612224064 0;
BA_ "GenMsgSendType" BO_ 557 5;
BA_ "GenMsgCycleTime" BO_ 557 1000;
BA_ "FrameGatewayId" BO_ 1236 1236;
BA_ "FrameGatewayNetwork" BO_ 1236 "FD1_CAN";
BA_ "FrameRouting" BO_ 1236 "FD1_CAN,0x4D4;";
BA_ "FrameGatewayId" BO_ 1235 1235;
BA_ "FrameGatewayNetwork" BO_ 1235 "FD1_CAN";
BA_ "FrameRouting" BO_ 1235 "FD1_CAN,0x4D3;";
BA_ "FrameGatewayId" BO_ 1234 1234;
BA_ "FrameGatewayNetwork" BO_ 1234 "FD1_CAN";
BA_ "FrameRouting" BO_ 1234 "FD1_CAN,0x4D2;";
BA_ "FrameGatewayId" BO_ 1237 1237;
BA_ "FrameGatewayNetwork" BO_ 1237 "FD1_CAN";
BA_ "FrameRouting" BO_ 1237 "FD1_CAN,0x4D5;";
BA_ "GenMsgSendType" BO_ 976 5;
BA_ "GenMsgCycleTime" BO_ 976 1000;
BA_ "TpTxIndex" BO_ 715 23;
BA_ "FrameGatewayId" BO_ 925 925;
BA_ "FrameGatewayNetwork" BO_ 925 "FD1_CAN";
BA_ "FrameRouting" BO_ 925 "FD1_CAN,0x39D";
BA_ "FrameGatewayId" BO_ 788 788;
BA_ "FrameGatewayNetwork" BO_ 788 "FD1_CAN";
BA_ "FrameRouting" BO_ 788 "FD1_CAN,0x314;";
BA_ "GenMsgSendType" BO_ 473 1;
BA_ "GenMsgILSupport" BO_ 2000 0;
BA_ "DiagRequest" BO_ 2000 1;
BA_ "GenMsgSendType" BO_ 2000 1;
BA_ "GenMsgDelayTime" BO_ 2000 0;
BA_ "NetworkInitialization" BO_ 2000 0;
BA_ "GenMsgSendType" BO_ 810 5;
BA_ "GenMsgCycleTime" BO_ 810 1000;
BA_ "GenMsgSendType" BO_ 482 5;
BA_ "GenMsgCycleTime" BO_ 482 1000;
BA_ "GenMsgSendType" BO_ 764 5;
BA_ "GenMsgCycleTime" BO_ 764 1000;
BA_ "GenMsgSendType" BO_ 628 5;
BA_ "GenMsgCycleTime" BO_ 628 1000;
BA_ "TpTxIndex" BO_ 710 26;
BA_ "FrameGatewayId" BO_ 710 710;
BA_ "FrameGatewayNetwork" BO_ 710 "MS1_CAN";
BA_ "FrameRouting" BO_ 710 "MS1_CAN,0x2C6;";
BA_ "FrameGatewayId" BO_ 770 770;
BA_ "FrameGatewayNetwork" BO_ 770 "FD1_CAN";
BA_ "FrameRouting" BO_ 770 "FD1_CAN,0x302;";
BA_ "FrameGatewayId" BO_ 785 785;
BA_ "FrameGatewayNetwork" BO_ 785 "FD1_CAN";
BA_ "FrameRouting" BO_ 785 "FD1_CAN,0x311;";
BA_ "TpTxIndex" BO_ 1202 40;
BA_ "TpTxIndex" BO_ 1210 40;
BA_ "GenMsgSendType" BO_ 391 1;
BA_ "GenMsgSendType" BO_ 415 1;
BA_ "TpTxIndex" BO_ 703 18;
BA_ "TpTxIndex" BO_ 695 18;
BA_ "GenMsgSendType" BO_ 501 1;
BA_ "GenMsgILSupport" BO_ 1506 0;
BA_ "NmAsrMessage" BO_ 1506 1;
BA_ "GenMsgSendType" BO_ 1506 0;
BA_ "GenMsgCycleTime" BO_ 1506 1000;
BA_ "NetworkInitialization" BO_ 1506 0;
BA_ "FrameGatewayId" BO_ 651 651;
BA_ "FrameGatewayNetwork" BO_ 651 "HS4_CAN";
BA_ "FrameRouting" BO_ 651 "HS4_CAN,0x28B";
BA_ "FrameGatewayId" BO_ 1098 1098;
BA_ "FrameGatewayNetwork" BO_ 1098 "FD1_CAN";
BA_ "FrameRouting" BO_ 1098 "FD1_CAN,0x44A;HS1_CAN,0x44A";
BA_ "GenMsgSendType" BO_ 629 5;
BA_ "GenMsgCycleTime" BO_ 629 1000;
BA_ "TpTxIndex" BO_ 718 26;
BA_ "GenMsgSendType" BO_ 672 5;
BA_ "GenMsgCycleTime" BO_ 672 1000;
BA_ "GenMsgStartDelayTime" BO_ 672 150;
BA_ "GenMsgILSupport" BO_ 1952 0;
BA_ "DiagRequest" BO_ 1952 1;
BA_ "GenMsgSendType" BO_ 1952 1;
BA_ "GenMsgDelayTime" BO_ 1952 0;
BA_ "NetworkInitialization" BO_ 1952 0;
BA_ "GenMsgILSupport" BO_ 1960 0;
BA_ "DiagResponse" BO_ 1960 1;
BA_ "GenMsgSendType" BO_ 1960 1;
BA_ "GenMsgDelayTime" BO_ 1960 0;
BA_ "NetworkInitialization" BO_ 1960 0;
BA_ "FrameGatewayId" BO_ 1205 1205;
BA_ "FrameGatewayNetwork" BO_ 1205 "FD1_CAN";
BA_ "FrameRouting" BO_ 1205 "FD1_CAN,0x4B5";
BA_ "GenMsgILSupport" BO_ 1829 0;
BA_ "DiagRequest" BO_ 1829 1;
BA_ "GenMsgSendType" BO_ 1829 1;
BA_ "GenMsgDelayTime" BO_ 1829 0;
BA_ "NetworkInitialization" BO_ 1829 0;
BA_ "TpTxIndex" BO_ 601 58;
BA_ "TpTxIndex" BO_ 593 58;
BA_ "GenMsgSendType" BO_ 816 5;
BA_ "GenMsgCycleTime" BO_ 816 1000;
BA_ "FrameGatewayId" BO_ 636 636;
BA_ "FrameGatewayNetwork" BO_ 636 "HS4_CAN";
BA_ "FrameRouting" BO_ 636 "HS4_CAN,0x27C";
BA_ "GenMsgSendType" BO_ 807 5;
BA_ "GenMsgCycleTime" BO_ 807 1000;
BA_ "FrameGatewayId" BO_ 974 878;
BA_ "FrameGatewayNetwork" BO_ 974 "FD1_CAN";
BA_ "FrameRouting" BO_ 974 "FD1_CAN,0x36E;";
BA_ "GenMsgSendType" BO_ 805 0;
BA_ "GenMsgCycleTime" BO_ 805 100;
BA_ "GenMsgSendType" BO_ 804 5;
BA_ "GenMsgCycleTime" BO_ 804 1000;
BA_ "GenMsgSendType" BO_ 803 5;
BA_ "GenMsgCycleTime" BO_ 803 1000;
BA_ "GenMsgSendType" BO_ 802 5;
BA_ "GenMsgCycleTime" BO_ 802 1000;
BA_ "GenMsgSendType" BO_ 812 5;
BA_ "GenMsgCycleTime" BO_ 812 1000;
BA_ "GenMsgSendType" BO_ 885 0;
BA_ "GenMsgCycleTime" BO_ 885 200;
BA_ "FrameGatewayId" BO_ 784 784;
BA_ "FrameGatewayNetwork" BO_ 784 "MS2_CAN";
BA_ "FrameRouting" BO_ 784 "MS2_CAN,0x310;";
BA_ "GenMsgSendType" BO_ 1119 1;
BA_ "GenMsgSendType" BO_ 1118 1;
BA_ "GenMsgSendType" BO_ 290 1;
BA_ "TpTxIndex" BO_ 2612101336 464617688;
BA_ "OvtpPushApplication" BO_ 2612101336 1;
BA_ "GenMsgSendType" BO_ 2612101336 1;
BA_ "GenMsgDelayTime" BO_ 2612101336 0;
BA_ "NetworkInitialization" BO_ 2612101336 0;
BA_ "FrameGatewayId" BO_ 1043 1043;
BA_ "FrameGatewayNetwork" BO_ 1043 "FD1_CAN";
BA_ "FrameRouting" BO_ 1043 "FD1_CAN,0x413;";
BA_ "GenMsgSendType" BO_ 813 5;
BA_ "GenMsgCycleTime" BO_ 813 1000;
BA_ "GenMsgSendType" BO_ 639 5;
BA_ "GenMsgCycleTime" BO_ 639 1000;
BA_ "GenMsgSendType" BO_ 419 1;
BA_ "FrameGatewayId" BO_ 542 542;
BA_ "FrameGatewayNetwork" BO_ 542 "HS4_CAN";
BA_ "FrameRouting" BO_ 542 "HS4_CAN,0x21E;";
BA_ "GenMsgSendType" BO_ 554 5;
BA_ "GenMsgCycleTime" BO_ 554 1000;
BA_ "GenMsgSendType" BO_ 494 1;
BA_ "TpTxIndex" BO_ 714 28;
BA_ "GenMsgSendType" BO_ 498 1;
BA_ "GenMsgSendType" BO_ 644 0;
BA_ "GenMsgCycleTime" BO_ 644 100;
BA_ "GenMsgSendType" BO_ 643 5;
BA_ "GenMsgCycleTime" BO_ 643 1000;
BA_ "GenMsgSendType" BO_ 145 1;
BA_ "GenSigStartValueInteger" SG_ 884 PmSnsCabn_D_Stat 5;
BA_ "GenSigStartValue" SG_ 884 PmSnsCabn_D_Stat 5;
BA_ "U_U55X_MY2022_Rx" SG_ 884 PmSnsCabn_D_Stat 1;
BA_ "U_P702_MY2021_Rx" SG_ 884 PmSnsCabn_D_Stat 1;
BA_ "U_T6_MCA_MY2020_Rx" SG_ 884 PmSnsCabn_D_Stat 1;
BA_ "U_CD542_MY2021_Rx" SG_ 884 PmSnsCabn_D_Stat 1;
BA_ "GenSigStartValueInteger" SG_ 884 PmCabn_Conc_Actl 510;
BA_ "GenSigStartValue" SG_ 884 PmCabn_Conc_Actl 510;
BA_ "U_U55X_MY2022_Rx" SG_ 884 PmCabn_Conc_Actl 1;
BA_ "U_P702_MY2021_Rx" SG_ 884 PmCabn_Conc_Actl 1;
BA_ "U_T6_MCA_MY2020_Rx" SG_ 884 PmCabn_Conc_Actl 1;
BA_ "U_CD542_MY2021_Rx" SG_ 884 PmCabn_Conc_Actl 1;
BA_ "GenSigStartValueInteger" SG_ 884 PmCabn20Mnte_Conc_Actl 510;
BA_ "GenSigStartValue" SG_ 884 PmCabn20Mnte_Conc_Actl 510;
BA_ "U_U55X_MY2022_Rx" SG_ 884 PmCabn20Mnte_Conc_Actl 1;
BA_ "U_P702_MY2021_Rx" SG_ 884 PmCabn20Mnte_Conc_Actl 1;
BA_ "U_T6_MCA_MY2020_Rx" SG_ 884 PmCabn20Mnte_Conc_Actl 1;
BA_ "U_CD542_MY2021_Rx" SG_ 884 PmCabn20Mnte_Conc_Actl 1;
BA_ "GenSigStartValueInteger" SG_ 884 PmCabn18Mnte_Conc_Actl 510;
BA_ "GenSigStartValue" SG_ 884 PmCabn18Mnte_Conc_Actl 510;
BA_ "U_U55X_MY2022_Rx" SG_ 884 PmCabn18Mnte_Conc_Actl 1;
BA_ "U_P702_MY2021_Rx" SG_ 884 PmCabn18Mnte_Conc_Actl 1;
BA_ "U_T6_MCA_MY2020_Rx" SG_ 884 PmCabn18Mnte_Conc_Actl 1;
BA_ "U_CD542_MY2021_Rx" SG_ 884 PmCabn18Mnte_Conc_Actl 1;
BA_ "GenSigStartValueInteger" SG_ 884 PmCabn16Mnte_Conc_Actl 510;
BA_ "GenSigStartValue" SG_ 884 PmCabn16Mnte_Conc_Actl 510;
BA_ "U_U55X_MY2022_Rx" SG_ 884 PmCabn16Mnte_Conc_Actl 1;
BA_ "U_P702_MY2021_Rx" SG_ 884 PmCabn16Mnte_Conc_Actl 1;
BA_ "U_T6_MCA_MY2020_Rx" SG_ 884 PmCabn16Mnte_Conc_Actl 1;
BA_ "U_CD542_MY2021_Rx" SG_ 884 PmCabn16Mnte_Conc_Actl 1;
BA_ "GenSigStartValueInteger" SG_ 884 PmCabn14Mnte_Conc_Actl 510;
BA_ "GenSigStartValue" SG_ 884 PmCabn14Mnte_Conc_Actl 510;
BA_ "U_U55X_MY2022_Rx" SG_ 884 PmCabn14Mnte_Conc_Actl 1;
BA_ "U_P702_MY2021_Rx" SG_ 884 PmCabn14Mnte_Conc_Actl 1;
BA_ "U_T6_MCA_MY2020_Rx" SG_ 884 PmCabn14Mnte_Conc_Actl 1;
BA_ "U_CD542_MY2021_Rx" SG_ 884 PmCabn14Mnte_Conc_Actl 1;
BA_ "GenSigStartValueInteger" SG_ 884 PmCabn12Mnte_Conc_Actl 510;
BA_ "GenSigStartValue" SG_ 884 PmCabn12Mnte_Conc_Actl 510;
BA_ "U_U55X_MY2022_Rx" SG_ 884 PmCabn12Mnte_Conc_Actl 1;
BA_ "U_P702_MY2021_Rx" SG_ 884 PmCabn12Mnte_Conc_Actl 1;
BA_ "U_T6_MCA_MY2020_Rx" SG_ 884 PmCabn12Mnte_Conc_Actl 1;
BA_ "U_CD542_MY2021_Rx" SG_ 884 PmCabn12Mnte_Conc_Actl 1;
BA_ "GenSigStartValueInteger" SG_ 883 PmCabn10Mnte_Conc_Actl 510;
BA_ "GenSigStartValue" SG_ 883 PmCabn10Mnte_Conc_Actl 510;
BA_ "U_U55X_MY2022_Rx" SG_ 883 PmCabn10Mnte_Conc_Actl 1;
BA_ "U_P702_MY2021_Rx" SG_ 883 PmCabn10Mnte_Conc_Actl 1;
BA_ "U_T6_MCA_MY2020_Rx" SG_ 883 PmCabn10Mnte_Conc_Actl 1;
BA_ "U_CD542_MY2021_Rx" SG_ 883 PmCabn10Mnte_Conc_Actl 1;
BA_ "GenSigStartValueInteger" SG_ 883 PmCabn08Mnte_Conc_Actl 510;
BA_ "GenSigStartValue" SG_ 883 PmCabn08Mnte_Conc_Actl 510;
BA_ "U_U55X_MY2022_Rx" SG_ 883 PmCabn08Mnte_Conc_Actl 1;
BA_ "U_P702_MY2021_Rx" SG_ 883 PmCabn08Mnte_Conc_Actl 1;
BA_ "U_T6_MCA_MY2020_Rx" SG_ 883 PmCabn08Mnte_Conc_Actl 1;
BA_ "U_CD542_MY2021_Rx" SG_ 883 PmCabn08Mnte_Conc_Actl 1;
BA_ "GenSigStartValueInteger" SG_ 883 PmCabn06Mnte_Conc_Actl 510;
BA_ "GenSigStartValue" SG_ 883 PmCabn06Mnte_Conc_Actl 510;
BA_ "U_U55X_MY2022_Rx" SG_ 883 PmCabn06Mnte_Conc_Actl 1;
BA_ "U_P702_MY2021_Rx" SG_ 883 PmCabn06Mnte_Conc_Actl 1;
BA_ "U_T6_MCA_MY2020_Rx" SG_ 883 PmCabn06Mnte_Conc_Actl 1;
BA_ "U_CD542_MY2021_Rx" SG_ 883 PmCabn06Mnte_Conc_Actl 1;
BA_ "GenSigStartValueInteger" SG_ 883 PmCabn04Mnte_Conc_Actl 510;
BA_ "GenSigStartValue" SG_ 883 PmCabn04Mnte_Conc_Actl 510;
BA_ "U_U55X_MY2022_Rx" SG_ 883 PmCabn04Mnte_Conc_Actl 1;
BA_ "U_P702_MY2021_Rx" SG_ 883 PmCabn04Mnte_Conc_Actl 1;
BA_ "U_T6_MCA_MY2020_Rx" SG_ 883 PmCabn04Mnte_Conc_Actl 1;
BA_ "U_CD542_MY2021_Rx" SG_ 883 PmCabn04Mnte_Conc_Actl 1;
BA_ "GenSigStartValueInteger" SG_ 883 PmCabn02Mnte_Conc_Actl 510;
BA_ "GenSigStartValue" SG_ 883 PmCabn02Mnte_Conc_Actl 510;
BA_ "U_U55X_MY2022_Rx" SG_ 883 PmCabn02Mnte_Conc_Actl 1;
BA_ "U_P702_MY2021_Rx" SG_ 883 PmCabn02Mnte_Conc_Actl 1;
BA_ "U_T6_MCA_MY2020_Rx" SG_ 883 PmCabn02Mnte_Conc_Actl 1;
BA_ "U_CD542_MY2021_Rx" SG_ 883 PmCabn02Mnte_Conc_Actl 1;
BA_ "GenSigStartValueInteger" SG_ 1090 VehElRnge_L_Dsply 4095;
BA_ "GenSigStartValue" SG_ 1090 VehElRnge_L_Dsply 4093;
BA_ "U_U55X_MY2022_Rx" SG_ 1090 VehElRnge_L_Dsply 1;
BA_ "U_T6_MCA_MY2020_Rx" SG_ 1090 VehElRnge_L_Dsply 1;
BA_ "U_CD542_MY2021_Rx" SG_ 1090 VehElRnge_L_Dsply 1;
BA_ "GenSigStartValueInteger" SG_ 1090 Inv1Ain_I_ActlMntr 32766;
BA_ "GenSigStartValue" SG_ 1090 Inv1Ain_I_ActlMntr 32765;
BA_ "GenSigSendType" SG_ 677 SeatFnPsgr_D_Rq3 3;
BA_ "U_U55X_MY2022_Tx" SG_ 677 SeatFnPsgr_D_Rq3 1;
BA_ "GenSigSendType" SG_ 677 SeatFnDrv_D_Rq3 3;
BA_ "U_U55X_MY2022_Tx" SG_ 677 SeatFnDrv_D_Rq3 1;
BA_ "GenSigSendType" SG_ 677 SeatMasgPsngrRr_D_Rq2 3;
BA_ "U_U55X_MY2022_Tx" SG_ 677 SeatMasgPsngrRr_D_Rq2 1;
BA_ "GenSigSendType" SG_ 677 SeatMasgDrvRr_D_Rq2 3;
BA_ "U_U55X_MY2022_Tx" SG_ 677 SeatMasgDrvRr_D_Rq2 1;
BA_ "GenSigSendType" SG_ 677 SeatFnChngPsgr2_D_Rq3 3;
BA_ "U_U55X_MY2022_Tx" SG_ 677 SeatFnChngPsgr2_D_Rq3 1;
BA_ "GenSigSendType" SG_ 677 SeatFnChngDrv2_D_Rq3 3;
BA_ "U_U55X_MY2022_Tx" SG_ 677 SeatFnChngDrv2_D_Rq3 1;
BA_ "U_CD542_MY2021_Rx" SG_ 1238 IaccVAdjReas_D_Dsply 1;
BA_ "U_U55X_MY2022_Rx" SG_ 1238 IaccVAdjReas_D_Dsply 1;
BA_ "U_CD542_MY2021_Rx" SG_ 1238 IaccVAdjLim_No_Actl 1;
BA_ "U_U55X_MY2022_Rx" SG_ 1238 IaccVAdjLim_No_Actl 1;
BA_ "U_U55X_MY2022_Rx" SG_ 1041 ElCmpr_N_Actl 1;
BA_ "GenSigSendType" SG_ 2609971416 OTAPhysGWM_ECGtoWCM 3;
BA_ "U_CD542_MY2021_Rx" SG_ 2609971416 OTAPhysGWM_ECGtoWCM 1;
BA_ "U_U55X_MY2022_Rx" SG_ 2609971416 OTAPhysGWM_ECGtoWCM 1;
BA_ "ECGUsedTxSignal" SG_ 2609971416 OTAPhysGWM_ECGtoWCM 1;
BA_ "U_CD542_MY2021_Tx" SG_ 2609971416 OTAPhysGWM_ECGtoWCM 1;
BA_ "GenSigSendType" SG_ 2610126912 OTAPhysWCMtoGWM_ECG 3;
BA_ "ECGUsedRxSignal" SG_ 2610126912 OTAPhysWCMtoGWM_ECG 1;
BA_ "U_CD542_MY2021_Rx" SG_ 2610126912 OTAPhysWCMtoGWM_ECG 1;
BA_ "U_CD542_MY2021_Tx" SG_ 2610126912 OTAPhysWCMtoGWM_ECG 1;
BA_ "U_U55X_MY2022_Tx" SG_ 2610126912 OTAPhysWCMtoGWM_ECG 1;
BA_ "GenSigSendType" SG_ 2611019992 PARSEDPhysGWM_ECGtoWCM 3;
BA_ "U_CD542_MY2021_Rx" SG_ 2611019992 PARSEDPhysGWM_ECGtoWCM 1;
BA_ "U_U55X_MY2022_Rx" SG_ 2611019992 PARSEDPhysGWM_ECGtoWCM 1;
BA_ "ECGUsedTxSignal" SG_ 2611019992 PARSEDPhysGWM_ECGtoWCM 1;
BA_ "U_CD542_MY2021_Tx" SG_ 2611019992 PARSEDPhysGWM_ECGtoWCM 1;
BA_ "GenSigSendType" SG_ 2611175488 PARSEDPhysWCMtoGWM_ECG 3;
BA_ "ECGUsedRxSignal" SG_ 2611175488 PARSEDPhysWCMtoGWM_ECG 1;
BA_ "U_CD542_MY2021_Rx" SG_ 2611175488 PARSEDPhysWCMtoGWM_ECG 1;
BA_ "U_U55X_MY2022_Tx" SG_ 2611175488 PARSEDPhysWCMtoGWM_ECG 1;
BA_ "GenSigSendType" SG_ 2612068568 PARSEDPushFcGWM_ECGtoWCM 3;
BA_ "U_CD542_MY2021_Rx" SG_ 2612068568 PARSEDPushFcGWM_ECGtoWCM 1;
BA_ "U_U55X_MY2022_Rx" SG_ 2612068568 PARSEDPushFcGWM_ECGtoWCM 1;
BA_ "ECGUsedTxSignal" SG_ 2612068568 PARSEDPushFcGWM_ECGtoWCM 1;
BA_ "U_CD542_MY2021_Tx" SG_ 2612068568 PARSEDPushFcGWM_ECGtoWCM 1;
BA_ "GenSigSendType" SG_ 2612224064 PARSEDPushWCMtoGWM_ECG 3;
BA_ "ECGUsedRxSignal" SG_ 2612224064 PARSEDPushWCMtoGWM_ECG 1;
BA_ "U_CD542_MY2021_Rx" SG_ 2612224064 PARSEDPushWCMtoGWM_ECG 1;
BA_ "U_CD542_MY2021_Tx" SG_ 2612224064 PARSEDPushWCMtoGWM_ECG 1;
BA_ "U_U55X_MY2022_Tx" SG_ 2612224064 PARSEDPushWCMtoGWM_ECG 1;
BA_ "GenSigSendType" SG_ 557 AudioToneTouchY_D_Stat 3;
BA_ "U_T6_MCA_MY2020_Rx" SG_ 557 AudioToneTouchY_D_Stat 1;
BA_ "U_U55X_MY2022_Rx" SG_ 557 AudioToneTouchY_D_Stat 1;
BA_ "GenSigSendType" SG_ 557 AudioToneTouchX_D_Stat 3;
BA_ "U_T6_MCA_MY2020_Rx" SG_ 557 AudioToneTouchX_D_Stat 1;
BA_ "U_U55X_MY2022_Rx" SG_ 557 AudioToneTouchX_D_Stat 1;
BA_ "GenSigSendType" SG_ 557 AudioToneTouch_D_Stat 3;
BA_ "U_T6_MCA_MY2020_Rx" SG_ 557 AudioToneTouch_D_Stat 1;
BA_ "U_U55X_MY2022_Rx" SG_ 557 AudioToneTouch_D_Stat 1;
BA_ "GenSigStartValue" SG_ 1236 ApaSlotRearX_L_Actl 1048;
BA_ "U_U55X_MY2022_Rx" SG_ 1236 ApaSlotRearX_L_Actl 1;
BA_ "GenSigStartValue" SG_ 1236 ApaSlotRight3X_L_Actl 1048;
BA_ "U_U55X_MY2022_Rx" SG_ 1236 ApaSlotRight3X_L_Actl 1;
BA_ "U_U55X_MY2022_Rx" SG_ 1236 ApaSlotRight3_D_Stat 1;
BA_ "U_U55X_MY2022_Rx" SG_ 1236 ApaSlotRight3_B_Altr 1;
BA_ "GenSigStartValue" SG_ 1236 ApaSlotRight2X_L_Actl 1048;
BA_ "U_U55X_MY2022_Rx" SG_ 1236 ApaSlotRight2X_L_Actl 1;
BA_ "U_U55X_MY2022_Rx" SG_ 1236 ApaSlotRight2_D_Stat 1;
BA_ "U_U55X_MY2022_Rx" SG_ 1236 ApaSlotRight2_B_Altr 1;
BA_ "GenSigStartValue" SG_ 1236 ApaSlotRight1X_L_Actl 1048;
BA_ "U_U55X_MY2022_Rx" SG_ 1236 ApaSlotRight1X_L_Actl 1;
BA_ "U_U55X_MY2022_Rx" SG_ 1236 ApaSlotRight1_D_Stat 1;
BA_ "U_U55X_MY2022_Rx" SG_ 1236 ApaSlotRight1_B_Altr 1;
BA_ "GenSigStartValue" SG_ 1236 ApaSlotRearY_L_Actl 32;
BA_ "U_U55X_MY2022_Rx" SG_ 1236 ApaSlotRearY_L_Actl 1;
BA_ "U_U55X_MY2022_Rx" SG_ 1236 ApaSlotRear_D_Stat 1;
BA_ "U_U55X_MY2022_Rx" SG_ 1235 ApaSlotFront_D_Stat 1;
BA_ "GenSigStartValue" SG_ 1235 ApaSlotLeft3X_L_Actl 1048;
BA_ "U_U55X_MY2022_Rx" SG_ 1235 ApaSlotLeft3X_L_Actl 1;
BA_ "U_U55X_MY2022_Rx" SG_ 1235 ApaSlotLeft3_D_Stat 1;
BA_ "U_U55X_MY2022_Rx" SG_ 1235 ApaSlotLeft3_B_Altr 1;
BA_ "GenSigStartValue" SG_ 1235 ApaSlotFrontX_L_Actl 1048;
BA_ "U_U55X_MY2022_Rx" SG_ 1235 ApaSlotFrontX_L_Actl 1;
BA_ "GenSigStartValue" SG_ 1235 ApaSlotFrontY_L_Actl 32;
BA_ "U_U55X_MY2022_Rx" SG_ 1235 ApaSlotFrontY_L_Actl 1;
BA_ "GenSigStartValue" SG_ 1235 ApaSlotLeft2X_L_Actl 1048;
BA_ "U_U55X_MY2022_Rx" SG_ 1235 ApaSlotLeft2X_L_Actl 1;
BA_ "U_U55X_MY2022_Rx" SG_ 1235 ApaSlotLeft2_D_Stat 1;
BA_ "U_U55X_MY2022_Rx" SG_ 1235 ApaSlotLeft2_B_Altr 1;
BA_ "GenSigStartValue" SG_ 1235 ApaSlotLeft1X_L_Actl 1048;
BA_ "U_U55X_MY2022_Rx" SG_ 1235 ApaSlotLeft1X_L_Actl 1;
BA_ "U_U55X_MY2022_Rx" SG_ 1235 ApaSlotLeft1_D_Stat 1;
BA_ "U_U55X_MY2022_Rx" SG_ 1235 ApaSlotLeft1_B_Altr 1;
BA_ "GenSigStartValue" SG_ 1234 RmtCtlConfgSrc_D_Stat 1;
BA_ "U_U55X_MY2022_Rx" SG_ 1237 ApaSlotRef2Y_L_Actl 1;
BA_ "U_U55X_MY2022_Rx" SG_ 1237 ApaSlotRef2X_L_Actl 1;
BA_ "U_U55X_MY2022_Rx" SG_ 1237 ApaSlotRef1Y_L_Actl 1;
BA_ "U_U55X_MY2022_Rx" SG_ 1237 ApaSlotRef1X_L_Actl 1;
BA_ "U_P702_MY2021_Rx" SG_ 976 VehLong2_A_Actl_UB 1;
BA_ "U_T6_MCA_MY2020_Rx" SG_ 976 VehLong2_A_Actl_UB 1;
BA_ "U_U55X_MY2022_Rx" SG_ 976 VehLong2_A_Actl_UB 1;
BA_ "GenSigStartValueInteger" SG_ 976 VehLong2_A_Actl 8190;
BA_ "GenSigStartValue" SG_ 976 VehLong2_A_Actl 8190;
BA_ "U_P702_MY2021_Rx" SG_ 976 VehLong2_A_Actl 1;
BA_ "U_T6_MCA_MY2020_Rx" SG_ 976 VehLong2_A_Actl 1;
BA_ "U_U55X_MY2022_Rx" SG_ 976 VehLong2_A_Actl 1;
BA_ "U_P702_MY2021_Rx" SG_ 715 RDISP_SSP_WORD_Rx 1;
BA_ "U_T6_MCA_MY2020_Rx" SG_ 715 RDISP_SSP_WORD_Rx 1;
BA_ "U_CD542_MY2021_Rx" SG_ 715 RDISP_SSP_WORD_Rx 1;
BA_ "U_U55X_MY2022_Rx" SG_ 715 RDISP_SSP_WORD_Rx 1;
BA_ "U_P702_MY2021_Tx" SG_ 715 RDISP_SSP_WORD_Rx 1;
BA_ "U_T6_MCA_MY2020_Tx" SG_ 715 RDISP_SSP_WORD_Rx 1;
BA_ "U_CD542_MY2021_Tx" SG_ 715 RDISP_SSP_WORD_Rx 1;
BA_ "U_U55X_MY2022_Tx" SG_ 715 RDISP_SSP_WORD_Rx 1;
BA_ "GenSigStartValue" SG_ 898 SecondRowBcklPsngrMid 3;
BA_ "GenSigStartValue" SG_ 898 SecondRowBckleDrvMid 3;
BA_ "GenSigStartValue" SG_ 898 FourthRowBucklePsngr 3;
BA_ "GenSigStartValue" SG_ 898 FourthRowBuckleMid 3;
BA_ "GenSigStartValue" SG_ 898 FourthRowBuckleDriver 3;
BA_ "GenSigStartValue" SG_ 898 Row3PsngrPrsnc_D_Actl 3;
BA_ "GenSigStartValue" SG_ 898 Row3MidPrsnc_D_Actl 3;
BA_ "GenSigStartValue" SG_ 898 Row3DrvPrsnc_D_Actl 3;
BA_ "GenSigStartValue" SG_ 898 Row2PsngrPrsnc_D_Actl 3;
BA_ "GenSigStartValue" SG_ 898 Row2MidPrsnc_D_Actl 3;
BA_ "GenSigStartValue" SG_ 898 Row2DrvPrsnc_D_Actl 3;
BA_ "GenSigStartValueInteger" SG_ 925 VehElEffTrip_No_Dsply 126;
BA_ "GenSigStartValue" SG_ 925 VehElEffTrip_No_Dsply 126;
BA_ "U_U55X_MY2022_Rx" SG_ 925 VehElEffTrip_No_Dsply 1;
BA_ "GenSigStartValueInteger" SG_ 925 TripSumDrvE_Pc_Dsply 1022;
BA_ "GenSigStartValue" SG_ 925 TripSumDrvE_Pc_Dsply 1022;
BA_ "U_U55X_MY2022_Rx" SG_ 925 TripSumDrvE_Pc_Dsply 1;
BA_ "GenSigStartValueInteger" SG_ 925 TripExtFctrE_Pc_Dsply 1022;
BA_ "GenSigStartValue" SG_ 925 TripExtFctrE_Pc_Dsply 1022;
BA_ "U_U55X_MY2022_Rx" SG_ 925 TripExtFctrE_Pc_Dsply 1;
BA_ "GenSigStartValueInteger" SG_ 925 TripClimE_Pc_Dsply 1022;
BA_ "GenSigStartValue" SG_ 925 TripClimE_Pc_Dsply 1022;
BA_ "U_U55X_MY2022_Rx" SG_ 925 TripClimE_Pc_Dsply 1;
BA_ "GenSigStartValueInteger" SG_ 925 TripBattULoE_Pc_Dsply 1022;
BA_ "GenSigStartValue" SG_ 925 TripBattULoE_Pc_Dsply 1022;
BA_ "U_U55X_MY2022_Rx" SG_ 925 TripBattULoE_Pc_Dsply 1;
BA_ "GenSigStartValueInteger" SG_ 788 EcoCochDecel2_Pc_Dsply 255;
BA_ "GenSigStartValue" SG_ 788 EcoCochDecel2_Pc_Dsply 255;
BA_ "U_U55X_MY2022_Rx" SG_ 788 EcoCochDecel2_Pc_Dsply 1;
BA_ "GenSigStartValueInteger" SG_ 788 EcoCochDecel1_Pc_Dsply 255;
BA_ "GenSigStartValue" SG_ 788 EcoCochDecel1_Pc_Dsply 255;
BA_ "U_U55X_MY2022_Rx" SG_ 788 EcoCochDecel1_Pc_Dsply 1;
BA_ "GenSigStartValueInteger" SG_ 788 EcoCochCrus2_Pc_Dsply 255;
BA_ "GenSigStartValue" SG_ 788 EcoCochCrus2_Pc_Dsply 255;
BA_ "U_U55X_MY2022_Rx" SG_ 788 EcoCochCrus2_Pc_Dsply 1;
BA_ "GenSigStartValueInteger" SG_ 788 EcoCochCrus1_Pc_Dsply 255;
BA_ "GenSigStartValue" SG_ 788 EcoCochCrus1_Pc_Dsply 255;
BA_ "U_U55X_MY2022_Rx" SG_ 788 EcoCochCrus1_Pc_Dsply 1;
BA_ "GenSigStartValueInteger" SG_ 788 EcoCochATrip2_Pc_Dsply 255;
BA_ "GenSigStartValue" SG_ 788 EcoCochATrip2_Pc_Dsply 255;
BA_ "U_U55X_MY2022_Rx" SG_ 788 EcoCochATrip2_Pc_Dsply 1;
BA_ "GenSigStartValueInteger" SG_ 788 EcoCochATrip1_Pc_Dsply 255;
BA_ "GenSigStartValue" SG_ 788 EcoCochATrip1_Pc_Dsply 255;
BA_ "U_U55X_MY2022_Rx" SG_ 788 EcoCochATrip1_Pc_Dsply 1;
BA_ "GenSigSendType" SG_ 473 NAV_StorePreset2_Rq 3;
BA_ "U_T6_MCA_MY2020_Rx" SG_ 473 NAV_StorePreset2_Rq 1;
BA_ "U_CD542_MY2021_Rx" SG_ 473 NAV_StorePreset2_Rq 1;
BA_ "U_U55X_MY2022_Rx" SG_ 473 NAV_StorePreset2_Rq 1;
BA_ "U_T6_MCA_MY2020_Tx" SG_ 473 NAV_StorePreset2_Rq 1;
BA_ "U_CD542_MY2021_Tx" SG_ 473 NAV_StorePreset2_Rq 1;
BA_ "U_U55X_MY2022_Tx" SG_ 473 NAV_StorePreset2_Rq 1;
BA_ "GenSigSendType" SG_ 473 NAV_SetAFMode_Rq 3;
BA_ "U_T6_MCA_MY2020_Rx" SG_ 473 NAV_SetAFMode_Rq 1;
BA_ "U_CD542_MY2021_Rx" SG_ 473 NAV_SetAFMode_Rq 1;
BA_ "U_U55X_MY2022_Rx" SG_ 473 NAV_SetAFMode_Rq 1;
BA_ "U_P702_MY2021_Tx" SG_ 473 NAV_SetAFMode_Rq 1;
BA_ "U_T6_MCA_MY2020_Tx" SG_ 473 NAV_SetAFMode_Rq 1;
BA_ "U_CD542_MY2021_Tx" SG_ 473 NAV_SetAFMode_Rq 1;
BA_ "U_U55X_MY2022_Tx" SG_ 473 NAV_SetAFMode_Rq 1;
BA_ "GenSigSendType" SG_ 473 NAV_StorePreset_Rq 3;
BA_ "U_T6_MCA_MY2020_Rx" SG_ 473 NAV_StorePreset_Rq 1;
BA_ "U_CD542_MY2021_Rx" SG_ 473 NAV_StorePreset_Rq 1;
BA_ "U_U55X_MY2022_Rx" SG_ 473 NAV_StorePreset_Rq 1;
BA_ "U_P702_MY2021_Tx" SG_ 473 NAV_StorePreset_Rq 1;
BA_ "U_T6_MCA_MY2020_Tx" SG_ 473 NAV_StorePreset_Rq 1;
BA_ "U_CD542_MY2021_Tx" SG_ 473 NAV_StorePreset_Rq 1;
BA_ "U_U55X_MY2022_Tx" SG_ 473 NAV_StorePreset_Rq 1;
BA_ "GenSigSendType" SG_ 473 HMI_StorePreset2_Rq 3;
BA_ "U_P702_MY2021_Rx" SG_ 473 HMI_StorePreset2_Rq 1;
BA_ "U_T6_MCA_MY2020_Rx" SG_ 473 HMI_StorePreset2_Rq 1;
BA_ "U_CD542_MY2021_Rx" SG_ 473 HMI_StorePreset2_Rq 1;
BA_ "U_U55X_MY2022_Rx" SG_ 473 HMI_StorePreset2_Rq 1;
BA_ "U_P702_MY2021_Tx" SG_ 473 HMI_StorePreset2_Rq 1;
BA_ "U_T6_MCA_MY2020_Tx" SG_ 473 HMI_StorePreset2_Rq 1;
BA_ "U_CD542_MY2021_Tx" SG_ 473 HMI_StorePreset2_Rq 1;
BA_ "U_U55X_MY2022_Tx" SG_ 473 HMI_StorePreset2_Rq 1;
BA_ "GenSigSendType" SG_ 473 NAV_SetTUServiceLink_Rq 3;
BA_ "U_T6_MCA_MY2020_Rx" SG_ 473 NAV_SetTUServiceLink_Rq 1;
BA_ "U_CD542_MY2021_Rx" SG_ 473 NAV_SetTUServiceLink_Rq 1;
BA_ "U_U55X_MY2022_Rx" SG_ 473 NAV_SetTUServiceLink_Rq 1;
BA_ "U_T6_MCA_MY2020_Tx" SG_ 473 NAV_SetTUServiceLink_Rq 1;
BA_ "U_CD542_MY2021_Tx" SG_ 473 NAV_SetTUServiceLink_Rq 1;
BA_ "U_U55X_MY2022_Tx" SG_ 473 NAV_SetTUServiceLink_Rq 1;
BA_ "GenSigSendType" SG_ 473 NAV_SetTAMode_Rq 3;
BA_ "U_T6_MCA_MY2020_Rx" SG_ 473 NAV_SetTAMode_Rq 1;
BA_ "U_CD542_MY2021_Rx" SG_ 473 NAV_SetTAMode_Rq 1;
BA_ "U_U55X_MY2022_Rx" SG_ 473 NAV_SetTAMode_Rq 1;
BA_ "U_T6_MCA_MY2020_Tx" SG_ 473 NAV_SetTAMode_Rq 1;
BA_ "U_CD542_MY2021_Tx" SG_ 473 NAV_SetTAMode_Rq 1;
BA_ "U_U55X_MY2022_Tx" SG_ 473 NAV_SetTAMode_Rq 1;
BA_ "GenSigSendType" SG_ 473 NAV_SetReg_Rq 3;
BA_ "U_T6_MCA_MY2020_Rx" SG_ 473 NAV_SetReg_Rq 1;
BA_ "U_CD542_MY2021_Rx" SG_ 473 NAV_SetReg_Rq 1;
BA_ "U_U55X_MY2022_Rx" SG_ 473 NAV_SetReg_Rq 1;
BA_ "U_T6_MCA_MY2020_Tx" SG_ 473 NAV_SetReg_Rq 1;
BA_ "U_CD542_MY2021_Tx" SG_ 473 NAV_SetReg_Rq 1;
BA_ "U_U55X_MY2022_Tx" SG_ 473 NAV_SetReg_Rq 1;
BA_ "GenSigSendType" SG_ 473 NAV_SelectPTYCodeSet_Rq 3;
BA_ "U_T6_MCA_MY2020_Rx" SG_ 473 NAV_SelectPTYCodeSet_Rq 1;
BA_ "U_U55X_MY2022_Rx" SG_ 473 NAV_SelectPTYCodeSet_Rq 1;
BA_ "U_T6_MCA_MY2020_Tx" SG_ 473 NAV_SelectPTYCodeSet_Rq 1;
BA_ "U_CD542_MY2021_Tx" SG_ 473 NAV_SelectPTYCodeSet_Rq 1;
BA_ "U_U55X_MY2022_Tx" SG_ 473 NAV_SelectPTYCodeSet_Rq 1;
BA_ "U_T6_MCA_MY2020_Rx" SG_ 473 NAV_SelectPTYCodes_Rq 1;
BA_ "U_CD542_MY2021_Rx" SG_ 473 NAV_SelectPTYCodes_Rq 1;
BA_ "U_U55X_MY2022_Rx" SG_ 473 NAV_SelectPTYCodes_Rq 1;
BA_ "U_T6_MCA_MY2020_Tx" SG_ 473 NAV_SelectPTYCodes_Rq 1;
BA_ "U_CD542_MY2021_Tx" SG_ 473 NAV_SelectPTYCodes_Rq 1;
BA_ "U_U55X_MY2022_Tx" SG_ 473 NAV_SelectPTYCodes_Rq 1;
BA_ "GenSigSendType" SG_ 473 NAV_CDSetShuffle_Rq 3;
BA_ "U_T6_MCA_MY2020_Rx" SG_ 473 NAV_CDSetShuffle_Rq 1;
BA_ "U_T6_MCA_MY2020_Tx" SG_ 473 NAV_CDSetShuffle_Rq 1;
BA_ "U_CD542_MY2021_Tx" SG_ 473 NAV_CDSetShuffle_Rq 1;
BA_ "U_U55X_MY2022_Tx" SG_ 473 NAV_CDSetShuffle_Rq 1;
BA_ "GenSigSendType" SG_ 473 NAV_CDSetRepeat_Rq 3;
BA_ "U_T6_MCA_MY2020_Rx" SG_ 473 NAV_CDSetRepeat_Rq 1;
BA_ "U_T6_MCA_MY2020_Tx" SG_ 473 NAV_CDSetRepeat_Rq 1;
BA_ "U_CD542_MY2021_Tx" SG_ 473 NAV_CDSetRepeat_Rq 1;
BA_ "U_U55X_MY2022_Tx" SG_ 473 NAV_CDSetRepeat_Rq 1;
BA_ "GenSigSendType" SG_ 473 NAV_CDSetIntroScan_Rq 3;
BA_ "U_T6_MCA_MY2020_Rx" SG_ 473 NAV_CDSetIntroScan_Rq 1;
BA_ "U_T6_MCA_MY2020_Tx" SG_ 473 NAV_CDSetIntroScan_Rq 1;
BA_ "U_CD542_MY2021_Tx" SG_ 473 NAV_CDSetIntroScan_Rq 1;
BA_ "U_U55X_MY2022_Tx" SG_ 473 NAV_CDSetIntroScan_Rq 1;
BA_ "GenSigSendType" SG_ 2000 TesterPhysicalReqAPIM 3;
BA_ "U_CD542_MY2021_Rx" SG_ 2000 TesterPhysicalReqAPIM 1;
BA_ "U_P702_MY2021_Rx" SG_ 2000 TesterPhysicalReqAPIM 1;
BA_ "U_T6_MCA_MY2020_Rx" SG_ 2000 TesterPhysicalReqAPIM 1;
BA_ "U_U55X_MY2022_Rx" SG_ 2000 TesterPhysicalReqAPIM 1;
BA_ "WakeupSignal" SG_ 810 ExtLghtDsply_B_StatArb 1;
BA_ "GenSigSendType" SG_ 810 ExtLghtDsply_B_StatArb 3;
BA_ "U_T6_MCA_MY2020_Rx" SG_ 810 ExtLghtDsply_B_StatArb 1;
BA_ "U_U55X_MY2022_Rx" SG_ 810 ExtLghtDsply_B_StatArb 1;
BA_ "U_T6_MCA_MY2020_Tx" SG_ 810 ExtLghtDsply_B_StatArb 1;
BA_ "ECGUsedTxSignal" SG_ 810 ExtLghtDsply_B_StatArb 1;
BA_ "U_CD542_MY2021_Tx" SG_ 810 ExtLghtDsply_B_StatArb 1;
BA_ "U_U55X_MY2022_Tx" SG_ 810 ExtLghtDsply_B_StatArb 1;
BA_ "GenSigSendType" SG_ 810 OneTEditActv_B_RqCld 3;
BA_ "U_U55X_MY2022_Rx" SG_ 810 OneTEditActv_B_RqCld 1;
BA_ "ECGUsedTxSignal" SG_ 810 OneTEditActv_B_RqCld 1;
BA_ "U_CD542_MY2021_Tx" SG_ 810 OneTEditActv_B_RqCld 1;
BA_ "U_U55X_MY2022_Tx" SG_ 810 OneTEditActv_B_RqCld 1;
BA_ "GenSigSendType" SG_ 482 SDARS_Firm_Update2_St 3;
BA_ "U_T6_MCA_MY2020_Rx" SG_ 482 SDARS_Firm_Update2_St 1;
BA_ "U_CD542_MY2021_Rx" SG_ 482 SDARS_Firm_Update2_St 1;
BA_ "U_U55X_MY2022_Rx" SG_ 482 SDARS_Firm_Update2_St 1;
BA_ "U_P702_MY2021_Tx" SG_ 482 SDARS_Firm_Update2_St 1;
BA_ "U_T6_MCA_MY2020_Tx" SG_ 482 SDARS_Firm_Update2_St 1;
BA_ "U_CD542_MY2021_Tx" SG_ 482 SDARS_Firm_Update2_St 1;
BA_ "U_U55X_MY2022_Tx" SG_ 482 SDARS_Firm_Update2_St 1;
BA_ "GenSigSendType" SG_ 482 SDARS_UnSubscrb_Chan2_St 3;
BA_ "U_T6_MCA_MY2020_Rx" SG_ 482 SDARS_UnSubscrb_Chan2_St 1;
BA_ "U_CD542_MY2021_Rx" SG_ 482 SDARS_UnSubscrb_Chan2_St 1;
BA_ "U_U55X_MY2022_Rx" SG_ 482 SDARS_UnSubscrb_Chan2_St 1;
BA_ "U_P702_MY2021_Tx" SG_ 482 SDARS_UnSubscrb_Chan2_St 1;
BA_ "U_T6_MCA_MY2020_Tx" SG_ 482 SDARS_UnSubscrb_Chan2_St 1;
BA_ "U_CD542_MY2021_Tx" SG_ 482 SDARS_UnSubscrb_Chan2_St 1;
BA_ "U_U55X_MY2022_Tx" SG_ 482 SDARS_UnSubscrb_Chan2_St 1;
BA_ "GenSigSendType" SG_ 482 SDARS_UnSubscrb2_St 3;
BA_ "U_T6_MCA_MY2020_Rx" SG_ 482 SDARS_UnSubscrb2_St 1;
BA_ "U_CD542_MY2021_Rx" SG_ 482 SDARS_UnSubscrb2_St 1;
BA_ "U_U55X_MY2022_Rx" SG_ 482 SDARS_UnSubscrb2_St 1;
BA_ "U_P702_MY2021_Tx" SG_ 482 SDARS_UnSubscrb2_St 1;
BA_ "U_T6_MCA_MY2020_Tx" SG_ 482 SDARS_UnSubscrb2_St 1;
BA_ "U_CD542_MY2021_Tx" SG_ 482 SDARS_UnSubscrb2_St 1;
BA_ "U_U55X_MY2022_Tx" SG_ 482 SDARS_UnSubscrb2_St 1;
BA_ "GenSigSendType" SG_ 482 SDARS_Subscription2_St 3;
BA_ "U_T6_MCA_MY2020_Rx" SG_ 482 SDARS_Subscription2_St 1;
BA_ "U_CD542_MY2021_Rx" SG_ 482 SDARS_Subscription2_St 1;
BA_ "U_U55X_MY2022_Rx" SG_ 482 SDARS_Subscription2_St 1;
BA_ "U_P702_MY2021_Tx" SG_ 482 SDARS_Subscription2_St 1;
BA_ "U_T6_MCA_MY2020_Tx" SG_ 482 SDARS_Subscription2_St 1;
BA_ "U_CD542_MY2021_Tx" SG_ 482 SDARS_Subscription2_St 1;
BA_ "U_U55X_MY2022_Tx" SG_ 482 SDARS_Subscription2_St 1;
BA_ "GenSigSendType" SG_ 482 SDARS_Seek_Scan2_St 3;
BA_ "U_T6_MCA_MY2020_Rx" SG_ 482 SDARS_Seek_Scan2_St 1;
BA_ "U_CD542_MY2021_Rx" SG_ 482 SDARS_Seek_Scan2_St 1;
BA_ "U_U55X_MY2022_Rx" SG_ 482 SDARS_Seek_Scan2_St 1;
BA_ "U_P702_MY2021_Tx" SG_ 482 SDARS_Seek_Scan2_St 1;
BA_ "U_T6_MCA_MY2020_Tx" SG_ 482 SDARS_Seek_Scan2_St 1;
BA_ "U_CD542_MY2021_Tx" SG_ 482 SDARS_Seek_Scan2_St 1;
BA_ "U_U55X_MY2022_Tx" SG_ 482 SDARS_Seek_Scan2_St 1;
BA_ "GenSigSendType" SG_ 482 SDARS_Receive_Err2_St 3;
BA_ "U_T6_MCA_MY2020_Rx" SG_ 482 SDARS_Receive_Err2_St 1;
BA_ "U_CD542_MY2021_Rx" SG_ 482 SDARS_Receive_Err2_St 1;
BA_ "U_U55X_MY2022_Rx" SG_ 482 SDARS_Receive_Err2_St 1;
BA_ "U_P702_MY2021_Tx" SG_ 482 SDARS_Receive_Err2_St 1;
BA_ "U_T6_MCA_MY2020_Tx" SG_ 482 SDARS_Receive_Err2_St 1;
BA_ "U_CD542_MY2021_Tx" SG_ 482 SDARS_Receive_Err2_St 1;
BA_ "U_U55X_MY2022_Tx" SG_ 482 SDARS_Receive_Err2_St 1;
BA_ "GenSigSendType" SG_ 482 SDARS_Loss_Ant2_St 3;
BA_ "U_T6_MCA_MY2020_Rx" SG_ 482 SDARS_Loss_Ant2_St 1;
BA_ "U_CD542_MY2021_Rx" SG_ 482 SDARS_Loss_Ant2_St 1;
BA_ "U_U55X_MY2022_Rx" SG_ 482 SDARS_Loss_Ant2_St 1;
BA_ "U_P702_MY2021_Tx" SG_ 482 SDARS_Loss_Ant2_St 1;
BA_ "U_T6_MCA_MY2020_Tx" SG_ 482 SDARS_Loss_Ant2_St 1;
BA_ "U_CD542_MY2021_Tx" SG_ 482 SDARS_Loss_Ant2_St 1;
BA_ "U_U55X_MY2022_Tx" SG_ 482 SDARS_Loss_Ant2_St 1;
BA_ "GenSigSendType" SG_ 482 SDARS_Invalid_Chan2_St 3;
BA_ "U_T6_MCA_MY2020_Rx" SG_ 482 SDARS_Invalid_Chan2_St 1;
BA_ "U_CD542_MY2021_Rx" SG_ 482 SDARS_Invalid_Chan2_St 1;
BA_ "U_U55X_MY2022_Rx" SG_ 482 SDARS_Invalid_Chan2_St 1;
BA_ "U_P702_MY2021_Tx" SG_ 482 SDARS_Invalid_Chan2_St 1;
BA_ "U_T6_MCA_MY2020_Tx" SG_ 482 SDARS_Invalid_Chan2_St 1;
BA_ "U_CD542_MY2021_Tx" SG_ 482 SDARS_Invalid_Chan2_St 1;
BA_ "U_U55X_MY2022_Tx" SG_ 482 SDARS_Invalid_Chan2_St 1;
BA_ "GenSigSendType" SG_ 482 SDARS_GCI_Update2_St 3;
BA_ "U_T6_MCA_MY2020_Rx" SG_ 482 SDARS_GCI_Update2_St 1;
BA_ "U_CD542_MY2021_Rx" SG_ 482 SDARS_GCI_Update2_St 1;
BA_ "U_U55X_MY2022_Rx" SG_ 482 SDARS_GCI_Update2_St 1;
BA_ "U_P702_MY2021_Tx" SG_ 482 SDARS_GCI_Update2_St 1;
BA_ "U_T6_MCA_MY2020_Tx" SG_ 482 SDARS_GCI_Update2_St 1;
BA_ "U_CD542_MY2021_Tx" SG_ 482 SDARS_GCI_Update2_St 1;
BA_ "U_U55X_MY2022_Tx" SG_ 482 SDARS_GCI_Update2_St 1;
BA_ "GenSigSendType" SG_ 482 SDARS_Error_Conf2_St 3;
BA_ "U_T6_MCA_MY2020_Rx" SG_ 482 SDARS_Error_Conf2_St 1;
BA_ "U_CD542_MY2021_Rx" SG_ 482 SDARS_Error_Conf2_St 1;
BA_ "U_U55X_MY2022_Rx" SG_ 482 SDARS_Error_Conf2_St 1;
BA_ "U_P702_MY2021_Tx" SG_ 482 SDARS_Error_Conf2_St 1;
BA_ "U_T6_MCA_MY2020_Tx" SG_ 482 SDARS_Error_Conf2_St 1;
BA_ "U_CD542_MY2021_Tx" SG_ 482 SDARS_Error_Conf2_St 1;
BA_ "U_U55X_MY2022_Tx" SG_ 482 SDARS_Error_Conf2_St 1;
BA_ "GenSigSendType" SG_ 482 SDARS_Antenna_Err2_St 3;
BA_ "U_T6_MCA_MY2020_Rx" SG_ 482 SDARS_Antenna_Err2_St 1;
BA_ "U_CD542_MY2021_Rx" SG_ 482 SDARS_Antenna_Err2_St 1;
BA_ "U_U55X_MY2022_Rx" SG_ 482 SDARS_Antenna_Err2_St 1;
BA_ "U_P702_MY2021_Tx" SG_ 482 SDARS_Antenna_Err2_St 1;
BA_ "U_T6_MCA_MY2020_Tx" SG_ 482 SDARS_Antenna_Err2_St 1;
BA_ "U_CD542_MY2021_Tx" SG_ 482 SDARS_Antenna_Err2_St 1;
BA_ "U_U55X_MY2022_Tx" SG_ 482 SDARS_Antenna_Err2_St 1;
BA_ "GenSigSendType" SG_ 764 SDARS_SID2_St 3;
BA_ "U_P702_MY2021_Rx" SG_ 764 SDARS_SID2_St 1;
BA_ "U_T6_MCA_MY2020_Rx" SG_ 764 SDARS_SID2_St 1;
BA_ "U_CD542_MY2021_Rx" SG_ 764 SDARS_SID2_St 1;
BA_ "U_U55X_MY2022_Rx" SG_ 764 SDARS_SID2_St 1;
BA_ "U_P702_MY2021_Tx" SG_ 764 SDARS_SID2_St 1;
BA_ "U_T6_MCA_MY2020_Tx" SG_ 764 SDARS_SID2_St 1;
BA_ "U_CD542_MY2021_Tx" SG_ 764 SDARS_SID2_St 1;
BA_ "U_U55X_MY2022_Tx" SG_ 764 SDARS_SID2_St 1;
BA_ "GenSigSendType" SG_ 764 SdarsSampleRate_D_Stat 3;
BA_ "U_P702_MY2021_Rx" SG_ 764 SdarsSampleRate_D_Stat 1;
BA_ "U_T6_MCA_MY2020_Rx" SG_ 764 SdarsSampleRate_D_Stat 1;
BA_ "U_CD542_MY2021_Rx" SG_ 764 SdarsSampleRate_D_Stat 1;
BA_ "U_U55X_MY2022_Rx" SG_ 764 SdarsSampleRate_D_Stat 1;
BA_ "U_P702_MY2021_Tx" SG_ 764 SdarsSampleRate_D_Stat 1;
BA_ "U_T6_MCA_MY2020_Tx" SG_ 764 SdarsSampleRate_D_Stat 1;
BA_ "U_CD542_MY2021_Tx" SG_ 764 SdarsSampleRate_D_Stat 1;
BA_ "U_U55X_MY2022_Tx" SG_ 764 SdarsSampleRate_D_Stat 1;
BA_ "GenSigSendType" SG_ 764 SdarsBaudRate_D_Stat 3;
BA_ "U_P702_MY2021_Rx" SG_ 764 SdarsBaudRate_D_Stat 1;
BA_ "U_T6_MCA_MY2020_Rx" SG_ 764 SdarsBaudRate_D_Stat 1;
BA_ "U_CD542_MY2021_Rx" SG_ 764 SdarsBaudRate_D_Stat 1;
BA_ "U_U55X_MY2022_Rx" SG_ 764 SdarsBaudRate_D_Stat 1;
BA_ "U_P702_MY2021_Tx" SG_ 764 SdarsBaudRate_D_Stat 1;
BA_ "U_T6_MCA_MY2020_Tx" SG_ 764 SdarsBaudRate_D_Stat 1;
BA_ "U_CD542_MY2021_Tx" SG_ 764 SdarsBaudRate_D_Stat 1;
BA_ "U_U55X_MY2022_Tx" SG_ 764 SdarsBaudRate_D_Stat 1;
BA_ "GenSigStartValue" SG_ 764 SDARS_CurrentChanNum2_St 1022;
BA_ "GenSigSendType" SG_ 764 SDARS_CurrentChanNum2_St 3;
BA_ "U_T6_MCA_MY2020_Rx" SG_ 764 SDARS_CurrentChanNum2_St 1;
BA_ "U_CD542_MY2021_Rx" SG_ 764 SDARS_CurrentChanNum2_St 1;
BA_ "U_U55X_MY2022_Rx" SG_ 764 SDARS_CurrentChanNum2_St 1;
BA_ "U_P702_MY2021_Rx" SG_ 764 SDARS_CurrentChanNum2_St 1;
BA_ "U_P702_MY2021_Tx" SG_ 764 SDARS_CurrentChanNum2_St 1;
BA_ "U_T6_MCA_MY2020_Tx" SG_ 764 SDARS_CurrentChanNum2_St 1;
BA_ "U_CD542_MY2021_Tx" SG_ 764 SDARS_CurrentChanNum2_St 1;
BA_ "U_U55X_MY2022_Tx" SG_ 764 SDARS_CurrentChanNum2_St 1;
BA_ "GenSigSendType" SG_ 764 SDARS_ChannelUpdate_St 3;
BA_ "U_P702_MY2021_Rx" SG_ 764 SDARS_ChannelUpdate_St 1;
BA_ "U_T6_MCA_MY2020_Rx" SG_ 764 SDARS_ChannelUpdate_St 1;
BA_ "U_CD542_MY2021_Rx" SG_ 764 SDARS_ChannelUpdate_St 1;
BA_ "U_U55X_MY2022_Rx" SG_ 764 SDARS_ChannelUpdate_St 1;
BA_ "U_P702_MY2021_Tx" SG_ 764 SDARS_ChannelUpdate_St 1;
BA_ "U_T6_MCA_MY2020_Tx" SG_ 764 SDARS_ChannelUpdate_St 1;
BA_ "U_CD542_MY2021_Tx" SG_ 764 SDARS_ChannelUpdate_St 1;
BA_ "U_U55X_MY2022_Tx" SG_ 764 SDARS_ChannelUpdate_St 1;
BA_ "GenSigSendType" SG_ 764 SDARS_Channel_Lock2 3;
BA_ "U_P702_MY2021_Rx" SG_ 764 SDARS_Channel_Lock2 1;
BA_ "U_T6_MCA_MY2020_Rx" SG_ 764 SDARS_Channel_Lock2 1;
BA_ "U_CD542_MY2021_Rx" SG_ 764 SDARS_Channel_Lock2 1;
BA_ "U_U55X_MY2022_Rx" SG_ 764 SDARS_Channel_Lock2 1;
BA_ "U_P702_MY2021_Tx" SG_ 764 SDARS_Channel_Lock2 1;
BA_ "U_T6_MCA_MY2020_Tx" SG_ 764 SDARS_Channel_Lock2 1;
BA_ "U_CD542_MY2021_Tx" SG_ 764 SDARS_Channel_Lock2 1;
BA_ "U_U55X_MY2022_Tx" SG_ 764 SDARS_Channel_Lock2 1;
BA_ "U_P702_MY2021_Rx" SG_ 628 CamraRearBttn_D_Stat_UB 1;
BA_ "U_T6_MCA_MY2020_Rx" SG_ 628 CamraRearBttn_D_Stat_UB 1;
BA_ "U_U55X_MY2022_Rx" SG_ 628 CamraRearBttn_D_Stat_UB 1;
BA_ "U_CD542_MY2021_Rx" SG_ 628 CamraRearBttn_D_Stat_UB 1;
BA_ "GenSigSendType" SG_ 628 CamraRearBttn_D_Stat 3;
BA_ "U_P702_MY2021_Rx" SG_ 628 CamraRearBttn_D_Stat 1;
BA_ "U_T6_MCA_MY2020_Rx" SG_ 628 CamraRearBttn_D_Stat 1;
BA_ "U_U55X_MY2022_Rx" SG_ 628 CamraRearBttn_D_Stat 1;
BA_ "U_CD542_MY2021_Rx" SG_ 628 CamraRearBttn_D_Stat 1;
BA_ "U_T6_MCA_MY2020_Rx" SG_ 628 GearEngag_D_Actl_UB 1;
BA_ "U_CD542_MY2021_Rx" SG_ 628 GearEngag_D_Actl_UB 1;
BA_ "U_U55X_MY2022_Rx" SG_ 628 GearEngag_D_Actl_UB 1;
BA_ "GenSigSendType" SG_ 628 GearEngag_D_Actl 3;
BA_ "U_T6_MCA_MY2020_Rx" SG_ 628 GearEngag_D_Actl 1;
BA_ "U_CD542_MY2021_Rx" SG_ 628 GearEngag_D_Actl 1;
BA_ "U_U55X_MY2022_Rx" SG_ 628 GearEngag_D_Actl 1;
BA_ "U_T6_MCA_MY2020_Rx" SG_ 628 RvltnMatchAllw_D_Stat_UB 1;
BA_ "U_CD542_MY2021_Rx" SG_ 628 RvltnMatchAllw_D_Stat_UB 1;
BA_ "U_U55X_MY2022_Rx" SG_ 628 RvltnMatchAllw_D_Stat_UB 1;
BA_ "GenSigSendType" SG_ 628 RvltnMatchAllw_D_Stat 3;
BA_ "U_T6_MCA_MY2020_Rx" SG_ 628 RvltnMatchAllw_D_Stat 1;
BA_ "U_CD542_MY2021_Rx" SG_ 628 RvltnMatchAllw_D_Stat 1;
BA_ "U_U55X_MY2022_Rx" SG_ 628 RvltnMatchAllw_D_Stat 1;
BA_ "GenSigSendType" SG_ 628 SeatScrnPsngrOn_B_Rq 3;
BA_ "U_P702_MY2021_Rx" SG_ 628 SeatScrnPsngrOn_B_Rq 1;
BA_ "U_T6_MCA_MY2020_Rx" SG_ 628 SeatScrnPsngrOn_B_Rq 1;
BA_ "U_CD542_MY2021_Rx" SG_ 628 SeatScrnPsngrOn_B_Rq 1;
BA_ "U_U55X_MY2022_Rx" SG_ 628 SeatScrnPsngrOn_B_Rq 1;
BA_ "U_P702_MY2021_Rx" SG_ 628 SeatScrnPsngrOn_B_Rq_UB 1;
BA_ "U_T6_MCA_MY2020_Rx" SG_ 628 SeatScrnPsngrOn_B_Rq_UB 1;
BA_ "U_CD542_MY2021_Rx" SG_ 628 SeatScrnPsngrOn_B_Rq_UB 1;
BA_ "U_U55X_MY2022_Rx" SG_ 628 SeatScrnPsngrOn_B_Rq_UB 1;
BA_ "U_P702_MY2021_Rx" SG_ 628 CamraRearOn_B_RqBalrl_UB 1;
BA_ "U_T6_MCA_MY2020_Rx" SG_ 628 CamraRearOn_B_RqBalrl_UB 1;
BA_ "U_CD542_MY2021_Rx" SG_ 628 CamraRearOn_B_RqBalrl_UB 1;
BA_ "U_P702_MY2021_Rx" SG_ 628 CamraRearOn_B_RqBalrr_UB 1;
BA_ "U_T6_MCA_MY2020_Rx" SG_ 628 CamraRearOn_B_RqBalrr_UB 1;
BA_ "U_CD542_MY2021_Rx" SG_ 628 CamraRearOn_B_RqBalrr_UB 1;
BA_ "GenSigSendType" SG_ 628 CamraRearOn_B_RqBalrr 3;
BA_ "U_P702_MY2021_Rx" SG_ 628 CamraRearOn_B_RqBalrr 1;
BA_ "U_T6_MCA_MY2020_Rx" SG_ 628 CamraRearOn_B_RqBalrr 1;
BA_ "U_CD542_MY2021_Rx" SG_ 628 CamraRearOn_B_RqBalrr 1;
BA_ "GenSigSendType" SG_ 628 CamraRearOn_B_RqBalrl 3;
BA_ "U_P702_MY2021_Rx" SG_ 628 CamraRearOn_B_RqBalrl 1;
BA_ "U_T6_MCA_MY2020_Rx" SG_ 628 CamraRearOn_B_RqBalrl 1;
BA_ "U_CD542_MY2021_Rx" SG_ 628 CamraRearOn_B_RqBalrl 1;
BA_ "GenSigSendType" SG_ 628 PwFlwFuelDrv_D_Dsply 3;
BA_ "U_P702_MY2021_Rx" SG_ 628 PwFlwFuelDrv_D_Dsply 1;
BA_ "U_T6_MCA_MY2020_Rx" SG_ 628 PwFlwFuelDrv_D_Dsply 1;
BA_ "U_CD542_MY2021_Rx" SG_ 628 PwFlwFuelDrv_D_Dsply 1;
BA_ "U_U55X_MY2022_Rx" SG_ 628 PwFlwFuelDrv_D_Dsply 1;
BA_ "GenSigSendType" SG_ 628 PwFlwFuelClimt_B_Dsply 3;
BA_ "U_P702_MY2021_Rx" SG_ 628 PwFlwFuelClimt_B_Dsply 1;
BA_ "U_T6_MCA_MY2020_Rx" SG_ 628 PwFlwFuelClimt_B_Dsply 1;
BA_ "U_CD542_MY2021_Rx" SG_ 628 PwFlwFuelClimt_B_Dsply 1;
BA_ "U_U55X_MY2022_Rx" SG_ 628 PwFlwFuelClimt_B_Dsply 1;
BA_ "GenSigSendType" SG_ 628 PwFlwFuelBatt_B_Dsply 3;
BA_ "U_P702_MY2021_Rx" SG_ 628 PwFlwFuelBatt_B_Dsply 1;
BA_ "U_T6_MCA_MY2020_Rx" SG_ 628 PwFlwFuelBatt_B_Dsply 1;
BA_ "U_CD542_MY2021_Rx" SG_ 628 PwFlwFuelBatt_B_Dsply 1;
BA_ "U_U55X_MY2022_Rx" SG_ 628 PwFlwFuelBatt_B_Dsply 1;
BA_ "GenSigSendType" SG_ 628 PwFlwBattGen_D_Dsply 3;
BA_ "U_P702_MY2021_Rx" SG_ 628 PwFlwBattGen_D_Dsply 1;
BA_ "U_T6_MCA_MY2020_Rx" SG_ 628 PwFlwBattGen_D_Dsply 1;
BA_ "U_CD542_MY2021_Rx" SG_ 628 PwFlwBattGen_D_Dsply 1;
BA_ "U_U55X_MY2022_Rx" SG_ 628 PwFlwBattGen_D_Dsply 1;
BA_ "GenSigSendType" SG_ 628 PwFlwBattClimt_B_Dsply 3;
BA_ "U_P702_MY2021_Rx" SG_ 628 PwFlwBattClimt_B_Dsply 1;
BA_ "U_T6_MCA_MY2020_Rx" SG_ 628 PwFlwBattClimt_B_Dsply 1;
BA_ "U_CD542_MY2021_Rx" SG_ 628 PwFlwBattClimt_B_Dsply 1;
BA_ "U_U55X_MY2022_Rx" SG_ 628 PwFlwBattClimt_B_Dsply 1;
BA_ "GenSigSendType" SG_ 628 PwFlwBatt_D_Dsply 3;
BA_ "U_P702_MY2021_Rx" SG_ 628 PwFlwBatt_D_Dsply 1;
BA_ "U_T6_MCA_MY2020_Rx" SG_ 628 PwFlwBatt_D_Dsply 1;
BA_ "U_CD542_MY2021_Rx" SG_ 628 PwFlwBatt_D_Dsply 1;
BA_ "U_U55X_MY2022_Rx" SG_ 628 PwFlwBatt_D_Dsply 1;
BA_ "U_P702_MY2021_Rx" SG_ 628 PwFlwFuelDrv_D_Dsply_UB 1;
BA_ "U_T6_MCA_MY2020_Rx" SG_ 628 PwFlwFuelDrv_D_Dsply_UB 1;
BA_ "U_CD542_MY2021_Rx" SG_ 628 PwFlwFuelDrv_D_Dsply_UB 1;
BA_ "U_U55X_MY2022_Rx" SG_ 628 PwFlwFuelDrv_D_Dsply_UB 1;
BA_ "U_P702_MY2021_Rx" SG_ 628 PwFlwFuelClimt_B_Dsply_UB 1;
BA_ "U_T6_MCA_MY2020_Rx" SG_ 628 PwFlwFuelClimt_B_Dsply_UB 1;
BA_ "U_CD542_MY2021_Rx" SG_ 628 PwFlwFuelClimt_B_Dsply_UB 1;
BA_ "U_U55X_MY2022_Rx" SG_ 628 PwFlwFuelClimt_B_Dsply_UB 1;
BA_ "U_P702_MY2021_Rx" SG_ 628 PwFlwFuelBatt_B_Dsply_UB 1;
BA_ "U_T6_MCA_MY2020_Rx" SG_ 628 PwFlwFuelBatt_B_Dsply_UB 1;
BA_ "U_CD542_MY2021_Rx" SG_ 628 PwFlwFuelBatt_B_Dsply_UB 1;
BA_ "U_U55X_MY2022_Rx" SG_ 628 PwFlwFuelBatt_B_Dsply_UB 1;
BA_ "U_P702_MY2021_Rx" SG_ 628 PwFlwBattGen_D_Dsply_UB 1;
BA_ "U_T6_MCA_MY2020_Rx" SG_ 628 PwFlwBattGen_D_Dsply_UB 1;
BA_ "U_CD542_MY2021_Rx" SG_ 628 PwFlwBattGen_D_Dsply_UB 1;
BA_ "U_U55X_MY2022_Rx" SG_ 628 PwFlwBattGen_D_Dsply_UB 1;
BA_ "U_P702_MY2021_Rx" SG_ 628 PwFlwBattClimt_B_Dsply_UB 1;
BA_ "U_T6_MCA_MY2020_Rx" SG_ 628 PwFlwBattClimt_B_Dsply_UB 1;
BA_ "U_CD542_MY2021_Rx" SG_ 628 PwFlwBattClimt_B_Dsply_UB 1;
BA_ "U_U55X_MY2022_Rx" SG_ 628 PwFlwBattClimt_B_Dsply_UB 1;
BA_ "U_P702_MY2021_Rx" SG_ 628 PwFlwBatt_D_Dsply_UB 1;
BA_ "U_T6_MCA_MY2020_Rx" SG_ 628 PwFlwBatt_D_Dsply_UB 1;
BA_ "U_CD542_MY2021_Rx" SG_ 628 PwFlwBatt_D_Dsply_UB 1;
BA_ "U_U55X_MY2022_Rx" SG_ 628 PwFlwBatt_D_Dsply_UB 1;
BA_ "GenSigSendType" SG_ 628 TrailCtlMsgTxt_D_Rq 3;
BA_ "U_T6_MCA_MY2020_Rx" SG_ 628 TrailCtlMsgTxt_D_Rq 1;
BA_ "U_U55X_MY2022_Rx" SG_ 628 TrailCtlMsgTxt_D_Rq 1;
BA_ "U_T6_MCA_MY2020_Rx" SG_ 628 TrailCtlMsgTxt_D_Rq_UB 1;
BA_ "U_U55X_MY2022_Rx" SG_ 628 TrailCtlMsgTxt_D_Rq_UB 1;
BA_ "U_T6_MCA_MY2020_Rx" SG_ 628 TrailCtl_D_Stat_UB 1;
BA_ "U_U55X_MY2022_Rx" SG_ 628 TrailCtl_D_Stat_UB 1;
BA_ "GenSigSendType" SG_ 628 TrailCtl_D_Stat 3;
BA_ "U_T6_MCA_MY2020_Rx" SG_ 628 TrailCtl_D_Stat 1;
BA_ "U_U55X_MY2022_Rx" SG_ 628 TrailCtl_D_Stat 1;
BA_ "GenSigSendType" SG_ 628 Veh_V_DsplyTrailCtlSet 3;
BA_ "U_T6_MCA_MY2020_Rx" SG_ 628 Veh_V_DsplyTrailCtlSet 1;
BA_ "U_U55X_MY2022_Rx" SG_ 628 Veh_V_DsplyTrailCtlSet 1;
BA_ "U_T6_MCA_MY2020_Rx" SG_ 628 Veh_V_DsplyTrailCtlSet_UB 1;
BA_ "U_U55X_MY2022_Rx" SG_ 628 Veh_V_DsplyTrailCtlSet_UB 1;
BA_ "U_P702_MY2021_Rx" SG_ 628 SeatScrnDrvOn_B_Rq_UB 1;
BA_ "U_T6_MCA_MY2020_Rx" SG_ 628 SeatScrnDrvOn_B_Rq_UB 1;
BA_ "U_U55X_MY2022_Rx" SG_ 628 SeatScrnDrvOn_B_Rq_UB 1;
BA_ "U_CD542_MY2021_Rx" SG_ 628 SeatScrnDrvOn_B_Rq_UB 1;
BA_ "WakeupSignal" SG_ 628 SeatScrnDrvOn_B_Rq 1;
BA_ "GenSigSendType" SG_ 628 SeatScrnDrvOn_B_Rq 3;
BA_ "U_P702_MY2021_Rx" SG_ 628 SeatScrnDrvOn_B_Rq 1;
BA_ "U_T6_MCA_MY2020_Rx" SG_ 628 SeatScrnDrvOn_B_Rq 1;
BA_ "U_U55X_MY2022_Rx" SG_ 628 SeatScrnDrvOn_B_Rq 1;
BA_ "U_CD542_MY2021_Rx" SG_ 628 SeatScrnDrvOn_B_Rq 1;
BA_ "U_T6_MCA_MY2020_Rx" SG_ 710 BEZEL_RDISP_WORD_Tx 1;
BA_ "U_U55X_MY2022_Rx" SG_ 710 BEZEL_RDISP_WORD_Tx 1;
BA_ "U_CD542_MY2021_Rx" SG_ 710 BEZEL_RDISP_WORD_Tx 1;
BA_ "GenSigStartValue" SG_ 770 ScMnSoc_Pc_Actl 100;
BA_ "U_U55X_MY2022_Rx" SG_ 770 ScMnSoc_Pc_Actl 1;
BA_ "GenSigStartValue" SG_ 770 CurntTrgtSoc_Pc_Rq 100;
BA_ "U_CD542_MY2021_Rx" SG_ 770 FstChrgBulk_T_Est 1;
BA_ "U_U55X_MY2022_Rx" SG_ 770 FstChrgBulk_T_Est 1;
BA_ "GenSigStartValue" SG_ 770 CurntTrgtSoc_Pc_Dsply 100;
BA_ "U_CD542_MY2021_Rx" SG_ 770 CurntTrgtSoc_Pc_Dsply 1;
BA_ "U_U55X_MY2022_Rx" SG_ 770 CurntTrgtSoc_Pc_Dsply 1;
BA_ "U_U55X_MY2022_Rx" SG_ 770 ScLocIdCurnt_No_Stat 1;
BA_ "U_U55X_MY2022_Rx" SG_ 770 ScEnbl_B_Stat 1;
BA_ "U_CD542_MY2021_Rx" SG_ 785 BattTracLimPerf_D_Dsply 1;
BA_ "U_U55X_MY2022_Rx" SG_ 785 EcoIdl_D_Stat 1;
BA_ "GenSigStartValue" SG_ 785 DteVehOffst_L_Dsply 8190;
BA_ "U_T6_MCA_MY2020_Rx" SG_ 785 DteVehOffst_L_Dsply 1;
BA_ "U_CD542_MY2021_Rx" SG_ 785 DteVehOffst_L_Dsply 1;
BA_ "U_U55X_MY2022_Rx" SG_ 785 DteVehOffst_L_Dsply 1;
BA_ "U_T6_MCA_MY2020_Rx" SG_ 785 DteVehOffstMsgTxt_D_Rq 1;
BA_ "U_CD542_MY2021_Rx" SG_ 785 DteVehOffstMsgTxt_D_Rq 1;
BA_ "U_U55X_MY2022_Rx" SG_ 785 DteVehOffstMsgTxt_D_Rq 1;
BA_ "U_T6_MCA_MY2020_Rx" SG_ 785 PwPckTqRdyChime_B_Rq 1;
BA_ "U_CD542_MY2021_Rx" SG_ 785 PwPckTqRdyChime_B_Rq 1;
BA_ "U_CD542_MY2021_Rx" SG_ 785 BattTracLoThres_D_Stat 1;
BA_ "U_U55X_MY2022_Rx" SG_ 785 BattTracLoThres_D_Stat 1;
BA_ "U_T6_MCA_MY2020_Rx" SG_ 785 BattTracLoMsgTxt_D_Rq 1;
BA_ "U_CD542_MY2021_Rx" SG_ 785 BattTracLoMsgTxt_D_Rq 1;
BA_ "U_T6_MCA_MY2020_Rx" SG_ 785 DestSocRqd_Pc_Dsply 1;
BA_ "U_CD542_MY2021_Rx" SG_ 785 DestSocRqd_Pc_Dsply 1;
BA_ "U_U55X_MY2022_Rx" SG_ 785 DestSocRqd_Pc_Dsply 1;
BA_ "U_T6_MCA_MY2020_Rx" SG_ 785 DestChrgEndMin_No_Actl 1;
BA_ "U_CD542_MY2021_Rx" SG_ 785 DestChrgEndMin_No_Actl 1;
BA_ "U_U55X_MY2022_Rx" SG_ 785 DestChrgEndMin_No_Actl 1;
BA_ "U_T6_MCA_MY2020_Rx" SG_ 785 DestChrgEndHr_No_Actl 1;
BA_ "U_CD542_MY2021_Rx" SG_ 785 DestChrgEndHr_No_Actl 1;
BA_ "U_U55X_MY2022_Rx" SG_ 785 DestChrgEndHr_No_Actl 1;
BA_ "GenSigStartValue" SG_ 785 DestChrgEndDay_No_Actl 1;
BA_ "U_T6_MCA_MY2020_Rx" SG_ 785 DestChrgEndDay_No_Actl 1;
BA_ "U_CD542_MY2021_Rx" SG_ 785 DestChrgEndDay_No_Actl 1;
BA_ "U_U55X_MY2022_Rx" SG_ 785 DestChrgEndDay_No_Actl 1;
BA_ "U_T6_MCA_MY2020_Rx" SG_ 785 BattTracLoSoc_D_Dsply 1;
BA_ "U_CD542_MY2021_Rx" SG_ 785 BattTracLoSoc_D_Dsply 1;
BA_ "U_U55X_MY2022_Rx" SG_ 785 BattTracLoSoc_D_Dsply 1;
BA_ "U_T6_MCA_MY2020_Rx" SG_ 1202 SDARS_VR_WORD_Rx 1;
BA_ "U_T6_MCA_MY2020_Tx" SG_ 1202 SDARS_VR_WORD_Rx 1;
BA_ "U_CD542_MY2021_Tx" SG_ 1202 SDARS_VR_WORD_Rx 1;
BA_ "U_U55X_MY2022_Tx" SG_ 1202 SDARS_VR_WORD_Rx 1;
BA_ "U_T6_MCA_MY2020_Rx" SG_ 1210 SDARS_VR_WORD_Tx 1;
BA_ "U_CD542_MY2021_Rx" SG_ 1210 SDARS_VR_WORD_Tx 1;
BA_ "U_U55X_MY2022_Rx" SG_ 1210 SDARS_VR_WORD_Tx 1;
BA_ "U_T6_MCA_MY2020_Tx" SG_ 1210 SDARS_VR_WORD_Tx 1;
BA_ "U_U55X_MY2022_Tx" SG_ 1210 SDARS_VR_WORD_Tx 1;
BA_ "GenSigSendType" SG_ 391 ACU_CtrlChimeChan_Rq 3;
BA_ "U_T6_MCA_MY2020_Rx" SG_ 391 ACU_CtrlChimeChan_Rq 1;
BA_ "U_CD542_MY2021_Rx" SG_ 391 ACU_CtrlChimeChan_Rq 1;
BA_ "U_T6_MCA_MY2020_Tx" SG_ 391 ACU_CtrlChimeChan_Rq 1;
BA_ "U_U55X_MY2022_Rx" SG_ 415 LBC3_StartItemInd 1;
BA_ "U_CD542_MY2021_Rx" SG_ 415 LBC3_StartItemInd 1;
BA_ "U_U55X_MY2022_Tx" SG_ 415 LBC3_StartItemInd 1;
BA_ "U_U55X_MY2022_Rx" SG_ 415 LBC3_SetListServ 1;
BA_ "U_CD542_MY2021_Rx" SG_ 415 LBC3_SetListServ 1;
BA_ "U_U55X_MY2022_Tx" SG_ 415 LBC3_SetListServ 1;
BA_ "GenSigSendType" SG_ 415 LBC3_Opcode 3;
BA_ "U_U55X_MY2022_Rx" SG_ 415 LBC3_Opcode 1;
BA_ "U_CD542_MY2021_Rx" SG_ 415 LBC3_Opcode 1;
BA_ "U_U55X_MY2022_Tx" SG_ 415 LBC3_Opcode 1;
BA_ "U_U55X_MY2022_Rx" SG_ 415 LBC3_NbrOfItems 1;
BA_ "U_CD542_MY2021_Rx" SG_ 415 LBC3_NbrOfItems 1;
BA_ "U_U55X_MY2022_Tx" SG_ 415 LBC3_NbrOfItems 1;
BA_ "U_U55X_MY2022_Rx" SG_ 415 LBC3_ItemIndex 1;
BA_ "U_CD542_MY2021_Rx" SG_ 415 LBC3_ItemIndex 1;
BA_ "U_U55X_MY2022_Tx" SG_ 415 LBC3_ItemIndex 1;
BA_ "U_U55X_MY2022_Rx" SG_ 415 LBC3_ActiveListID 1;
BA_ "U_CD542_MY2021_Rx" SG_ 415 LBC3_ActiveListID 1;
BA_ "U_U55X_MY2022_Tx" SG_ 415 LBC3_ActiveListID 1;
BA_ "U_T6_MCA_MY2020_Rx" SG_ 703 CONMP_MC_WORD_Rx 1;
BA_ "U_CD542_MY2021_Rx" SG_ 703 CONMP_MC_WORD_Rx 1;
BA_ "U_U55X_MY2022_Rx" SG_ 703 CONMP_MC_WORD_Rx 1;
BA_ "U_CD542_MY2021_Tx" SG_ 703 CONMP_MC_WORD_Rx 1;
BA_ "U_T6_MCA_MY2020_Rx" SG_ 695 CONMP_MC_WORD_Tx 1;
BA_ "U_CD542_MY2021_Rx" SG_ 695 CONMP_MC_WORD_Tx 1;
BA_ "U_T6_MCA_MY2020_Tx" SG_ 695 CONMP_MC_WORD_Tx 1;
BA_ "U_CD542_MY2021_Tx" SG_ 695 CONMP_MC_WORD_Tx 1;
BA_ "U_U55X_MY2022_Tx" SG_ 695 CONMP_MC_WORD_Tx 1;
BA_ "GenSigSendType" SG_ 501 Dsp_PresetArea_Rq 3;
BA_ "U_T6_MCA_MY2020_Rx" SG_ 501 Dsp_PresetArea_Rq 1;
BA_ "U_CD542_MY2021_Rx" SG_ 501 Dsp_PresetArea_Rq 1;
BA_ "U_U55X_MY2022_Rx" SG_ 501 Dsp_PresetArea_Rq 1;
BA_ "U_P702_MY2021_Tx" SG_ 501 Dsp_PresetArea_Rq 1;
BA_ "U_T6_MCA_MY2020_Tx" SG_ 501 Dsp_PresetArea_Rq 1;
BA_ "U_CD542_MY2021_Tx" SG_ 501 Dsp_PresetArea_Rq 1;
BA_ "U_U55X_MY2022_Tx" SG_ 501 Dsp_PresetArea_Rq 1;
BA_ "U_T6_MCA_MY2020_Rx" SG_ 501 Dsp_StartIndex2_Rq 1;
BA_ "U_CD542_MY2021_Rx" SG_ 501 Dsp_StartIndex2_Rq 1;
BA_ "U_U55X_MY2022_Rx" SG_ 501 Dsp_StartIndex2_Rq 1;
BA_ "U_P702_MY2021_Tx" SG_ 501 Dsp_StartIndex2_Rq 1;
BA_ "U_T6_MCA_MY2020_Tx" SG_ 501 Dsp_StartIndex2_Rq 1;
BA_ "U_CD542_MY2021_Tx" SG_ 501 Dsp_StartIndex2_Rq 1;
BA_ "U_U55X_MY2022_Tx" SG_ 501 Dsp_StartIndex2_Rq 1;
BA_ "GenSigSendType" SG_ 501 Dsp_SetRadSeekMode_Rq 3;
BA_ "U_T6_MCA_MY2020_Rx" SG_ 501 Dsp_SetRadSeekMode_Rq 1;
BA_ "U_CD542_MY2021_Rx" SG_ 501 Dsp_SetRadSeekMode_Rq 1;
BA_ "U_U55X_MY2022_Rx" SG_ 501 Dsp_SetRadSeekMode_Rq 1;
BA_ "U_P702_MY2021_Tx" SG_ 501 Dsp_SetRadSeekMode_Rq 1;
BA_ "U_T6_MCA_MY2020_Tx" SG_ 501 Dsp_SetRadSeekMode_Rq 1;
BA_ "U_CD542_MY2021_Tx" SG_ 501 Dsp_SetRadSeekMode_Rq 1;
BA_ "U_U55X_MY2022_Tx" SG_ 501 Dsp_SetRadSeekMode_Rq 1;
BA_ "GenSigSendType" SG_ 501 Dsp_SetCurrPreset2_Rq 3;
BA_ "U_T6_MCA_MY2020_Rx" SG_ 501 Dsp_SetCurrPreset2_Rq 1;
BA_ "U_CD542_MY2021_Rx" SG_ 501 Dsp_SetCurrPreset2_Rq 1;
BA_ "U_U55X_MY2022_Rx" SG_ 501 Dsp_SetCurrPreset2_Rq 1;
BA_ "U_P702_MY2021_Tx" SG_ 501 Dsp_SetCurrPreset2_Rq 1;
BA_ "U_T6_MCA_MY2020_Tx" SG_ 501 Dsp_SetCurrPreset2_Rq 1;
BA_ "U_CD542_MY2021_Tx" SG_ 501 Dsp_SetCurrPreset2_Rq 1;
BA_ "U_U55X_MY2022_Tx" SG_ 501 Dsp_SetCurrPreset2_Rq 1;
BA_ "GenSigSendType" SG_ 501 Dsp_SetCurrFMSLPr_Rq 3;
BA_ "U_T6_MCA_MY2020_Rx" SG_ 501 Dsp_SetCurrFMSLPr_Rq 1;
BA_ "U_CD542_MY2021_Rx" SG_ 501 Dsp_SetCurrFMSLPr_Rq 1;
BA_ "U_U55X_MY2022_Rx" SG_ 501 Dsp_SetCurrFMSLPr_Rq 1;
BA_ "U_P702_MY2021_Tx" SG_ 501 Dsp_SetCurrFMSLPr_Rq 1;
BA_ "U_T6_MCA_MY2020_Tx" SG_ 501 Dsp_SetCurrFMSLPr_Rq 1;
BA_ "U_CD542_MY2021_Tx" SG_ 501 Dsp_SetCurrFMSLPr_Rq 1;
BA_ "U_U55X_MY2022_Tx" SG_ 501 Dsp_SetCurrFMSLPr_Rq 1;
BA_ "GenSigSendType" SG_ 501 Dsp_SetCRadioBand_Rq 3;
BA_ "U_T6_MCA_MY2020_Rx" SG_ 501 Dsp_SetCRadioBand_Rq 1;
BA_ "U_CD542_MY2021_Rx" SG_ 501 Dsp_SetCRadioBand_Rq 1;
BA_ "U_U55X_MY2022_Rx" SG_ 501 Dsp_SetCRadioBand_Rq 1;
BA_ "U_P702_MY2021_Tx" SG_ 501 Dsp_SetCRadioBand_Rq 1;
BA_ "U_T6_MCA_MY2020_Tx" SG_ 501 Dsp_SetCRadioBand_Rq 1;
BA_ "U_CD542_MY2021_Tx" SG_ 501 Dsp_SetCRadioBand_Rq 1;
BA_ "U_U55X_MY2022_Tx" SG_ 501 Dsp_SetCRadioBand_Rq 1;
BA_ "U_T6_MCA_MY2020_Rx" SG_ 501 Dsp_NbrOfPresets_Rq 1;
BA_ "U_CD542_MY2021_Rx" SG_ 501 Dsp_NbrOfPresets_Rq 1;
BA_ "U_U55X_MY2022_Rx" SG_ 501 Dsp_NbrOfPresets_Rq 1;
BA_ "U_P702_MY2021_Tx" SG_ 501 Dsp_NbrOfPresets_Rq 1;
BA_ "U_T6_MCA_MY2020_Tx" SG_ 501 Dsp_NbrOfPresets_Rq 1;
BA_ "U_CD542_MY2021_Tx" SG_ 501 Dsp_NbrOfPresets_Rq 1;
BA_ "U_U55X_MY2022_Tx" SG_ 501 Dsp_NbrOfPresets_Rq 1;
BA_ "GenSigSendType" SG_ 501 Dsp_FreezeFMSL_Rq 3;
BA_ "U_P702_MY2021_Rx" SG_ 501 Dsp_FreezeFMSL_Rq 1;
BA_ "U_T6_MCA_MY2020_Rx" SG_ 501 Dsp_FreezeFMSL_Rq 1;
BA_ "U_CD542_MY2021_Rx" SG_ 501 Dsp_FreezeFMSL_Rq 1;
BA_ "U_U55X_MY2022_Rx" SG_ 501 Dsp_FreezeFMSL_Rq 1;
BA_ "U_P702_MY2021_Tx" SG_ 501 Dsp_FreezeFMSL_Rq 1;
BA_ "U_T6_MCA_MY2020_Tx" SG_ 501 Dsp_FreezeFMSL_Rq 1;
BA_ "U_CD542_MY2021_Tx" SG_ 501 Dsp_FreezeFMSL_Rq 1;
BA_ "U_U55X_MY2022_Tx" SG_ 501 Dsp_FreezeFMSL_Rq 1;
BA_ "GenSigStartValueInteger" SG_ 1506 APIM_GWOnBoardTester 255;
BA_ "ContentDependant" SG_ 1506 APIM_GWOnBoardTester 1;
BA_ "GenSigStartValue" SG_ 1506 APIM_GWOnBoardTester 255;
BA_ "U_T6_MCA_MY2020_Rx" SG_ 1506 APIM_GWOnBoardTester 1;
BA_ "U_U55X_MY2022_Rx" SG_ 1506 APIM_GWOnBoardTester 1;
BA_ "U_CD542_MY2021_Tx" SG_ 1506 APIM_GWOnBoardTester 1;
BA_ "U_U55X_MY2022_Tx" SG_ 1506 APIM_GWOnBoardTester 1;
BA_ "U_P702_MY2021_Tx" SG_ 1506 APIM_GWOnBoardTester 1;
BA_ "U_T6_MCA_MY2020_Tx" SG_ 1506 APIM_GWOnBoardTester 1;
BA_ "GenSigStartValueInteger" SG_ 1506 APIM_GWNMProxy 255;
BA_ "ContentDependant" SG_ 1506 APIM_GWNMProxy 1;
BA_ "GenSigStartValue" SG_ 1506 APIM_GWNMProxy 255;
BA_ "U_T6_MCA_MY2020_Rx" SG_ 1506 APIM_GWNMProxy 1;
BA_ "U_U55X_MY2022_Rx" SG_ 1506 APIM_GWNMProxy 1;
BA_ "U_CD542_MY2021_Tx" SG_ 1506 APIM_GWNMProxy 1;
BA_ "U_U55X_MY2022_Tx" SG_ 1506 APIM_GWNMProxy 1;
BA_ "U_P702_MY2021_Tx" SG_ 1506 APIM_GWNMProxy 1;
BA_ "U_T6_MCA_MY2020_Tx" SG_ 1506 APIM_GWNMProxy 1;
BA_ "GenSigStartValueInteger" SG_ 1506 APIM_AutoSarNMReserved4 255;
BA_ "ContentDependant" SG_ 1506 APIM_AutoSarNMReserved4 1;
BA_ "GenSigStartValue" SG_ 1506 APIM_AutoSarNMReserved4 255;
BA_ "U_T6_MCA_MY2020_Rx" SG_ 1506 APIM_AutoSarNMReserved4 1;
BA_ "U_U55X_MY2022_Rx" SG_ 1506 APIM_AutoSarNMReserved4 1;
BA_ "U_CD542_MY2021_Tx" SG_ 1506 APIM_AutoSarNMReserved4 1;
BA_ "U_U55X_MY2022_Tx" SG_ 1506 APIM_AutoSarNMReserved4 1;
BA_ "U_P702_MY2021_Tx" SG_ 1506 APIM_AutoSarNMReserved4 1;
BA_ "U_T6_MCA_MY2020_Tx" SG_ 1506 APIM_AutoSarNMReserved4 1;
BA_ "GenSigStartValueInteger" SG_ 1506 APIM_AutoSarNMReserved3 255;
BA_ "ContentDependant" SG_ 1506 APIM_AutoSarNMReserved3 1;
BA_ "GenSigStartValue" SG_ 1506 APIM_AutoSarNMReserved3 255;
BA_ "U_T6_MCA_MY2020_Rx" SG_ 1506 APIM_AutoSarNMReserved3 1;
BA_ "U_U55X_MY2022_Rx" SG_ 1506 APIM_AutoSarNMReserved3 1;
BA_ "U_CD542_MY2021_Tx" SG_ 1506 APIM_AutoSarNMReserved3 1;
BA_ "U_U55X_MY2022_Tx" SG_ 1506 APIM_AutoSarNMReserved3 1;
BA_ "U_P702_MY2021_Tx" SG_ 1506 APIM_AutoSarNMReserved3 1;
BA_ "U_T6_MCA_MY2020_Tx" SG_ 1506 APIM_AutoSarNMReserved3 1;
BA_ "GenSigStartValueInteger" SG_ 1506 APIM_AutoSarNMReserved2 255;
BA_ "ContentDependant" SG_ 1506 APIM_AutoSarNMReserved2 1;
BA_ "GenSigStartValue" SG_ 1506 APIM_AutoSarNMReserved2 255;
BA_ "U_T6_MCA_MY2020_Rx" SG_ 1506 APIM_AutoSarNMReserved2 1;
BA_ "U_U55X_MY2022_Rx" SG_ 1506 APIM_AutoSarNMReserved2 1;
BA_ "U_CD542_MY2021_Tx" SG_ 1506 APIM_AutoSarNMReserved2 1;
BA_ "U_U55X_MY2022_Tx" SG_ 1506 APIM_AutoSarNMReserved2 1;
BA_ "U_P702_MY2021_Tx" SG_ 1506 APIM_AutoSarNMReserved2 1;
BA_ "U_T6_MCA_MY2020_Tx" SG_ 1506 APIM_AutoSarNMReserved2 1;
BA_ "GenSigStartValueInteger" SG_ 1506 APIM_AutoSarNMReserved1 255;
BA_ "ContentDependant" SG_ 1506 APIM_AutoSarNMReserved1 1;
BA_ "GenSigStartValue" SG_ 1506 APIM_AutoSarNMReserved1 255;
BA_ "U_T6_MCA_MY2020_Rx" SG_ 1506 APIM_AutoSarNMReserved1 1;
BA_ "U_U55X_MY2022_Rx" SG_ 1506 APIM_AutoSarNMReserved1 1;
BA_ "U_CD542_MY2021_Tx" SG_ 1506 APIM_AutoSarNMReserved1 1;
BA_ "U_U55X_MY2022_Tx" SG_ 1506 APIM_AutoSarNMReserved1 1;
BA_ "U_P702_MY2021_Tx" SG_ 1506 APIM_AutoSarNMReserved1 1;
BA_ "U_T6_MCA_MY2020_Tx" SG_ 1506 APIM_AutoSarNMReserved1 1;
BA_ "GenSigStartValueInteger" SG_ 1506 APIM_AutoSarNMNodeId 226;
BA_ "ContentDependant" SG_ 1506 APIM_AutoSarNMNodeId 1;
BA_ "GenSigStartValue" SG_ 1506 APIM_AutoSarNMNodeId 226;
BA_ "U_T6_MCA_MY2020_Rx" SG_ 1506 APIM_AutoSarNMNodeId 1;
BA_ "U_U55X_MY2022_Rx" SG_ 1506 APIM_AutoSarNMNodeId 1;
BA_ "U_CD542_MY2021_Tx" SG_ 1506 APIM_AutoSarNMNodeId 1;
BA_ "U_U55X_MY2022_Tx" SG_ 1506 APIM_AutoSarNMNodeId 1;
BA_ "U_P702_MY2021_Tx" SG_ 1506 APIM_AutoSarNMNodeId 1;
BA_ "U_T6_MCA_MY2020_Tx" SG_ 1506 APIM_AutoSarNMNodeId 1;
BA_ "ContentDependant" SG_ 1506 APIM_AutoSarNMControl 1;
BA_ "U_T6_MCA_MY2020_Rx" SG_ 1506 APIM_AutoSarNMControl 1;
BA_ "U_U55X_MY2022_Rx" SG_ 1506 APIM_AutoSarNMControl 1;
BA_ "U_CD542_MY2021_Tx" SG_ 1506 APIM_AutoSarNMControl 1;
BA_ "U_U55X_MY2022_Tx" SG_ 1506 APIM_AutoSarNMControl 1;
BA_ "U_P702_MY2021_Tx" SG_ 1506 APIM_AutoSarNMControl 1;
BA_ "U_T6_MCA_MY2020_Tx" SG_ 1506 APIM_AutoSarNMControl 1;
BA_ "U_CD542_MY2021_Rx" SG_ 651 TelematicsSrvc_D_St 1;
BA_ "U_P702_MY2021_Rx" SG_ 651 TelematicsSrvc_D_St 1;
BA_ "U_T6_MCA_MY2020_Rx" SG_ 651 TelematicsSrvc_D_St 1;
BA_ "U_T6_MCA_MY2020_Rx" SG_ 651 EmgcyCallMute_D_Stat 1;
BA_ "U_CD542_MY2021_Rx" SG_ 651 EmgcyCallMute_D_Stat 1;
BA_ "U_U55X_MY2022_Rx" SG_ 651 EmgcyCallMute_D_Stat 1;
BA_ "U_P702_MY2021_Rx" SG_ 651 EmgcyCallMute_D_Stat 1;
BA_ "U_P702_MY2021_Rx" SG_ 1098 EdmVeh_V_Dsply 1;
BA_ "U_T6_MCA_MY2020_Rx" SG_ 1098 EdmVeh_V_Dsply 1;
BA_ "U_CD542_MY2021_Rx" SG_ 1098 EdmVeh_V_Dsply 1;
BA_ "U_U55X_MY2022_Rx" SG_ 1098 EdmVeh_V_Dsply 1;
BA_ "U_P702_MY2021_Rx" SG_ 1098 EdmSailMdeOn_B_Stat 1;
BA_ "U_T6_MCA_MY2020_Rx" SG_ 1098 EdmSailMdeOn_B_Stat 1;
BA_ "U_CD542_MY2021_Rx" SG_ 1098 EdmSailMdeOn_B_Stat 1;
BA_ "U_U55X_MY2022_Rx" SG_ 1098 EdmSailMdeOn_B_Stat 1;
BA_ "U_P702_MY2021_Rx" SG_ 1098 EdmPrev_Fe_Dsply 1;
BA_ "U_T6_MCA_MY2020_Rx" SG_ 1098 EdmPrev_Fe_Dsply 1;
BA_ "U_CD542_MY2021_Rx" SG_ 1098 EdmPrev_Fe_Dsply 1;
BA_ "U_U55X_MY2022_Rx" SG_ 1098 EdmPrev_Fe_Dsply 1;
BA_ "U_P702_MY2021_Rx" SG_ 1098 EdmMsgTxt_D_Rq 1;
BA_ "U_T6_MCA_MY2020_Rx" SG_ 1098 EdmMsgTxt_D_Rq 1;
BA_ "U_CD542_MY2021_Rx" SG_ 1098 EdmMsgTxt_D_Rq 1;
BA_ "U_U55X_MY2022_Rx" SG_ 1098 EdmMsgTxt_D_Rq 1;
BA_ "U_T6_MCA_MY2020_Rx" SG_ 1098 EdmLamp_D_Dsply 1;
BA_ "U_U55X_MY2022_Rx" SG_ 1098 EdmLamp_D_Dsply 1;
BA_ "U_P702_MY2021_Rx" SG_ 1098 EdmLamp_D_Dsply 1;
BA_ "U_CD542_MY2021_Rx" SG_ 1098 EdmLamp_D_Dsply 1;
BA_ "U_P702_MY2021_Rx" SG_ 1098 EdmCurrent_Fe_Dsply 1;
BA_ "U_T6_MCA_MY2020_Rx" SG_ 1098 EdmCurrent_Fe_Dsply 1;
BA_ "U_CD542_MY2021_Rx" SG_ 1098 EdmCurrent_Fe_Dsply 1;
BA_ "U_U55X_MY2022_Rx" SG_ 1098 EdmCurrent_Fe_Dsply 1;
BA_ "U_T6_MCA_MY2020_Rx" SG_ 1098 EdmCmplnc_B_Dsply 1;
BA_ "U_U55X_MY2022_Rx" SG_ 1098 EdmCmplnc_B_Dsply 1;
BA_ "U_P702_MY2021_Rx" SG_ 1098 EdmCmplnc_B_Dsply 1;
BA_ "U_CD542_MY2021_Rx" SG_ 1098 EdmCmplnc_B_Dsply 1;
BA_ "U_P702_MY2021_Rx" SG_ 1098 EdmCmplnc_Pc_Dsply 1;
BA_ "U_T6_MCA_MY2020_Rx" SG_ 1098 EdmCmplnc_Pc_Dsply 1;
BA_ "U_CD542_MY2021_Rx" SG_ 1098 EdmCmplnc_Pc_Dsply 1;
BA_ "U_U55X_MY2022_Rx" SG_ 1098 EdmCmplnc_Pc_Dsply 1;
BA_ "GenSigStartValueInteger" SG_ 1098 EcoCochInstTot_Pc_Dsply 255;
BA_ "GenSigStartValue" SG_ 1098 EcoCochInstTot_Pc_Dsply 255;
BA_ "U_T6_MCA_MY2020_Rx" SG_ 629 GearPos_D_Actl_UB 1;
BA_ "U_U55X_MY2022_Rx" SG_ 629 GearPos_D_Actl_UB 1;
BA_ "GenSigStartValueInteger" SG_ 629 GearPos_D_Actl 15;
BA_ "ContentDependant" SG_ 629 GearPos_D_Actl 1;
BA_ "GenSigStartValue" SG_ 629 GearPos_D_Actl 15;
BA_ "GenSigSendType" SG_ 629 GearPos_D_Actl 3;
BA_ "U_T6_MCA_MY2020_Rx" SG_ 629 GearPos_D_Actl 1;
BA_ "U_U55X_MY2022_Rx" SG_ 629 GearPos_D_Actl 1;
BA_ "U_CD542_MY2021_Rx" SG_ 629 BattTrac2_E_Max_UB 1;
BA_ "U_U55X_MY2022_Rx" SG_ 629 BattTrac2_E_Max_UB 1;
BA_ "U_CD542_MY2021_Rx" SG_ 629 BattTrac2_E_Avail_UB 1;
BA_ "U_U55X_MY2022_Rx" SG_ 629 BattTrac2_E_Avail_UB 1;
BA_ "GenSigStartValueInteger" SG_ 629 BattTrac2_E_Max 4094;
BA_ "GenSigStartValue" SG_ 629 BattTrac2_E_Max 4094;
BA_ "U_CD542_MY2021_Rx" SG_ 629 BattTrac2_E_Max 1;
BA_ "U_U55X_MY2022_Rx" SG_ 629 BattTrac2_E_Max 1;
BA_ "U_CD542_MY2021_Rx" SG_ 629 BattTrac2_E_Avail 1;
BA_ "U_U55X_MY2022_Rx" SG_ 629 BattTrac2_E_Avail 1;
BA_ "U_T6_MCA_MY2020_Rx" SG_ 629 BattULoChrgHyb_D_Stat_UB 1;
BA_ "U_CD542_MY2021_Rx" SG_ 629 TrnRng_D_Rq_UB 1;
BA_ "U_T6_MCA_MY2020_Rx" SG_ 629 TrnRng_D_Rq_UB 1;
BA_ "U_U55X_MY2022_Rx" SG_ 629 TrnRng_D_Rq_UB 1;
BA_ "GenSigStartValueInteger" SG_ 629 TrnRng_D_Rq 14;
BA_ "ContentDependant" SG_ 629 TrnRng_D_Rq 1;
BA_ "GenSigStartValue" SG_ 629 TrnRng_D_Rq 14;
BA_ "GenSigSendType" SG_ 629 TrnRng_D_Rq 3;
BA_ "U_CD542_MY2021_Rx" SG_ 629 TrnRng_D_Rq 1;
BA_ "U_T6_MCA_MY2020_Rx" SG_ 629 TrnRng_D_Rq 1;
BA_ "U_U55X_MY2022_Rx" SG_ 629 TrnRng_D_Rq 1;
BA_ "GenSigSendType" SG_ 629 BattULoChrgHyb_D_Stat 3;
BA_ "U_T6_MCA_MY2020_Rx" SG_ 629 BattULoChrgHyb_D_Stat 1;
BA_ "U_CD542_MY2021_Rx" SG_ 629 BattULoChrgHyb_D_Stat 1;
BA_ "U_CD542_MY2021_Rx" SG_ 629 BattTracHazrd_D_Stat_UB 1;
BA_ "GenSigSendType" SG_ 629 BattTracHazrd_D_Stat 3;
BA_ "U_CD542_MY2021_Rx" SG_ 629 BattTracHazrd_D_Stat 1;
BA_ "U_T6_MCA_MY2020_Tx" SG_ 718 BEZEL_RDISP_WORD_Rx 1;
BA_ "U_CD542_MY2021_Tx" SG_ 718 BEZEL_RDISP_WORD_Rx 1;
BA_ "U_U55X_MY2022_Tx" SG_ 718 BEZEL_RDISP_WORD_Rx 1;
BA_ "U_U55X_MY2022_Rx" SG_ 672 BCP_Audible_Beep_Rq 1;
BA_ "WakeupSignal" SG_ 672 SetVolume 1;
BA_ "GenSigStartValueInteger" SG_ 672 SetVolume 30;
BA_ "GenSigStartValue" SG_ 672 SetVolume 30;
BA_ "GenSigSendType" SG_ 672 SetVolume 3;
BA_ "U_T6_MCA_MY2020_Rx" SG_ 672 SetVolume 1;
BA_ "U_U55X_MY2022_Rx" SG_ 672 SetVolume 1;
BA_ "WakeupSignal" SG_ 672 SetPointVolume 1;
BA_ "GenSigSendType" SG_ 672 SetPointVolume 3;
BA_ "U_T6_MCA_MY2020_Rx" SG_ 672 SetPointVolume 1;
BA_ "U_U55X_MY2022_Rx" SG_ 672 SetPointVolume 1;
BA_ "WakeupSignal" SG_ 672 Coding_BtnID_D 1;
BA_ "GenSigSendType" SG_ 672 Coding_BtnID_D 3;
BA_ "U_T6_MCA_MY2020_Rx" SG_ 672 Coding_BtnID_D 1;
BA_ "U_U55X_MY2022_Rx" SG_ 672 Coding_BtnID_D 1;
BA_ "U_CD542_MY2021_Rx" SG_ 672 Coding_BtnID_D 1;
BA_ "WakeupSignal" SG_ 672 Coding_BtnID_C 1;
BA_ "GenSigSendType" SG_ 672 Coding_BtnID_C 3;
BA_ "U_T6_MCA_MY2020_Rx" SG_ 672 Coding_BtnID_C 1;
BA_ "U_U55X_MY2022_Rx" SG_ 672 Coding_BtnID_C 1;
BA_ "U_CD542_MY2021_Rx" SG_ 672 Coding_BtnID_C 1;
BA_ "WakeupSignal" SG_ 672 Coding_BtnID_B 1;
BA_ "GenSigSendType" SG_ 672 Coding_BtnID_B 3;
BA_ "U_T6_MCA_MY2020_Rx" SG_ 672 Coding_BtnID_B 1;
BA_ "U_U55X_MY2022_Rx" SG_ 672 Coding_BtnID_B 1;
BA_ "U_CD542_MY2021_Rx" SG_ 672 Coding_BtnID_B 1;
BA_ "WakeupSignal" SG_ 672 Coding_BtnID_A 1;
BA_ "GenSigSendType" SG_ 672 Coding_BtnID_A 3;
BA_ "U_T6_MCA_MY2020_Rx" SG_ 672 Coding_BtnID_A 1;
BA_ "U_U55X_MY2022_Rx" SG_ 672 Coding_BtnID_A 1;
BA_ "U_CD542_MY2021_Rx" SG_ 672 Coding_BtnID_A 1;
BA_ "WakeupSignal" SG_ 672 BtnID_D 1;
BA_ "GenSigStartValueInteger" SG_ 672 BtnID_D 255;
BA_ "GenSigStartValue" SG_ 672 BtnID_D 255;
BA_ "U_T6_MCA_MY2020_Rx" SG_ 672 BtnID_D 1;
BA_ "U_U55X_MY2022_Rx" SG_ 672 BtnID_D 1;
BA_ "U_CD542_MY2021_Rx" SG_ 672 BtnID_D 1;
BA_ "WakeupSignal" SG_ 672 BtnID_C 1;
BA_ "GenSigStartValueInteger" SG_ 672 BtnID_C 255;
BA_ "GenSigStartValue" SG_ 672 BtnID_C 255;
BA_ "U_T6_MCA_MY2020_Rx" SG_ 672 BtnID_C 1;
BA_ "U_U55X_MY2022_Rx" SG_ 672 BtnID_C 1;
BA_ "U_CD542_MY2021_Rx" SG_ 672 BtnID_C 1;
BA_ "WakeupSignal" SG_ 672 BtnID_B 1;
BA_ "GenSigStartValueInteger" SG_ 672 BtnID_B 255;
BA_ "GenSigStartValue" SG_ 672 BtnID_B 255;
BA_ "U_T6_MCA_MY2020_Rx" SG_ 672 BtnID_B 1;
BA_ "U_U55X_MY2022_Rx" SG_ 672 BtnID_B 1;
BA_ "U_CD542_MY2021_Rx" SG_ 672 BtnID_B 1;
BA_ "WakeupSignal" SG_ 672 BtnID_A 1;
BA_ "GenSigStartValueInteger" SG_ 672 BtnID_A 255;
BA_ "GenSigStartValue" SG_ 672 BtnID_A 255;
BA_ "U_T6_MCA_MY2020_Rx" SG_ 672 BtnID_A 1;
BA_ "U_U55X_MY2022_Rx" SG_ 672 BtnID_A 1;
BA_ "U_CD542_MY2021_Rx" SG_ 672 BtnID_A 1;
BA_ "GenSigSendType" SG_ 1952 TesterPhysicalReqFCIMB 3;
BA_ "GenSigSendType" SG_ 1960 TesterPhysicalResFCIMB 3;
BA_ "U_T6_MCA_MY2020_Rx" SG_ 1205 CstmDrvMdeCfg2_B_Avail 1;
BA_ "U_T6_MCA_MY2020_Rx" SG_ 1205 CstmDrvMdeCfg1_B_Avail 1;
BA_ "GenSigStartValue" SG_ 1205 CstmDrvMde_No_Confg2 63;
BA_ "U_T6_MCA_MY2020_Rx" SG_ 1205 CstmDrvMde_No_Confg2 1;
BA_ "GenSigStartValue" SG_ 1205 CstmDrvMde_No_Confg1 63;
BA_ "U_T6_MCA_MY2020_Rx" SG_ 1205 CstmDrvMde_No_Confg1 1;
BA_ "U_T6_MCA_MY2020_Rx" SG_ 1205 CstmDrvMde_No_Confg 1;
BA_ "GenSigStartValue" SG_ 1205 CstmDrvMde5_No_Confg2 15;
BA_ "U_T6_MCA_MY2020_Rx" SG_ 1205 CstmDrvMde5_No_Confg2 1;
BA_ "GenSigStartValue" SG_ 1205 CstmDrvMde5_No_Confg1 15;
BA_ "U_T6_MCA_MY2020_Rx" SG_ 1205 CstmDrvMde5_No_Confg1 1;
BA_ "GenSigStartValue" SG_ 1205 CstmDrvMde4_No_Confg2 15;
BA_ "U_T6_MCA_MY2020_Rx" SG_ 1205 CstmDrvMde4_No_Confg2 1;
BA_ "GenSigStartValue" SG_ 1205 CstmDrvMde4_No_Confg1 15;
BA_ "U_T6_MCA_MY2020_Rx" SG_ 1205 CstmDrvMde4_No_Confg1 1;
BA_ "GenSigStartValue" SG_ 1205 CstmDrvMde3_No_Confg2 15;
BA_ "U_T6_MCA_MY2020_Rx" SG_ 1205 CstmDrvMde3_No_Confg2 1;
BA_ "GenSigStartValue" SG_ 1205 CstmDrvMde3_No_Confg1 15;
BA_ "U_T6_MCA_MY2020_Rx" SG_ 1205 CstmDrvMde3_No_Confg1 1;
BA_ "GenSigStartValue" SG_ 1205 CstmDrvMde2_No_Confg2 15;
BA_ "U_T6_MCA_MY2020_Rx" SG_ 1205 CstmDrvMde2_No_Confg2 1;
BA_ "GenSigStartValue" SG_ 1205 CstmDrvMde2_No_Confg1 15;
BA_ "U_T6_MCA_MY2020_Rx" SG_ 1205 CstmDrvMde2_No_Confg1 1;
BA_ "GenSigStartValue" SG_ 1205 CstmDrvMde1_No_Confg2 15;
BA_ "U_T6_MCA_MY2020_Rx" SG_ 1205 CstmDrvMde1_No_Confg2 1;
BA_ "GenSigStartValue" SG_ 1205 CstmDrvMde1_No_Confg1 15;
BA_ "U_T6_MCA_MY2020_Rx" SG_ 1205 CstmDrvMde1_No_Confg1 1;
BA_ "GenSigSendType" SG_ 1829 TesterPhysicalReqWCM 3;
BA_ "U_CX727_MY2021_Rx" SG_ 1829 TesterPhysicalReqWCM 1;
BA_ "U_P702_MY2021_Rx" SG_ 1829 TesterPhysicalReqWCM 1;
BA_ "U_T6_MCA_MY2020_Rx" SG_ 1829 TesterPhysicalReqWCM 1;
BA_ "U_CD542_MY2021_Rx" SG_ 1829 TesterPhysicalReqWCM 1;
BA_ "U_U55X_MY2022_Rx" SG_ 1829 TesterPhysicalReqWCM 1;
BA_ "U_T6_MCA_MY2020_Rx" SG_ 601 ECG_MC_WORD_Rx 1;
BA_ "ECGUsedRxSignal" SG_ 601 ECG_MC_WORD_Rx 1;
BA_ "U_CD542_MY2021_Rx" SG_ 601 ECG_MC_WORD_Rx 1;
BA_ "U_U55X_MY2022_Rx" SG_ 601 ECG_MC_WORD_Rx 1;
BA_ "U_T6_MCA_MY2020_Tx" SG_ 601 ECG_MC_WORD_Rx 1;
BA_ "U_T6_MCA_MY2020_Rx" SG_ 593 ECG_MC_WORD_Tx 1;
BA_ "U_CD542_MY2021_Rx" SG_ 593 ECG_MC_WORD_Tx 1;
BA_ "U_T6_MCA_MY2020_Tx" SG_ 593 ECG_MC_WORD_Tx 1;
BA_ "ECGUsedTxSignal" SG_ 593 ECG_MC_WORD_Tx 1;
BA_ "U_CD542_MY2021_Tx" SG_ 593 ECG_MC_WORD_Tx 1;
BA_ "U_U55X_MY2022_Tx" SG_ 593 ECG_MC_WORD_Tx 1;
BA_ "GenSigSendType" SG_ 816 KeylessIdl_D_Rq 3;
BA_ "U_T6_MCA_MY2020_Tx" SG_ 816 KeylessIdl_D_Rq 1;
BA_ "U_CD542_MY2021_Tx" SG_ 816 KeylessIdl_D_Rq 1;
BA_ "U_U55X_MY2022_Tx" SG_ 816 KeylessIdl_D_Rq 1;
BA_ "WakeupSignal" SG_ 816 KeyPadCodeDgt7_D_Stat 1;
BA_ "GenSigSendType" SG_ 816 KeyPadCodeDgt7_D_Stat 3;
BA_ "U_T6_MCA_MY2020_Tx" SG_ 816 KeyPadCodeDgt7_D_Stat 1;
BA_ "U_CD542_MY2021_Tx" SG_ 816 KeyPadCodeDgt7_D_Stat 1;
BA_ "U_U55X_MY2022_Tx" SG_ 816 KeyPadCodeDgt7_D_Stat 1;
BA_ "WakeupSignal" SG_ 816 KeyPadCodeDgt6_D_Stat 1;
BA_ "GenSigSendType" SG_ 816 KeyPadCodeDgt6_D_Stat 3;
BA_ "U_T6_MCA_MY2020_Tx" SG_ 816 KeyPadCodeDgt6_D_Stat 1;
BA_ "U_CD542_MY2021_Tx" SG_ 816 KeyPadCodeDgt6_D_Stat 1;
BA_ "U_U55X_MY2022_Tx" SG_ 816 KeyPadCodeDgt6_D_Stat 1;
BA_ "WakeupSignal" SG_ 816 KeyPadCodeDgt5_D_Stat 1;
BA_ "GenSigSendType" SG_ 816 KeyPadCodeDgt5_D_Stat 3;
BA_ "U_T6_MCA_MY2020_Tx" SG_ 816 KeyPadCodeDgt5_D_Stat 1;
BA_ "U_CD542_MY2021_Tx" SG_ 816 KeyPadCodeDgt5_D_Stat 1;
BA_ "U_U55X_MY2022_Tx" SG_ 816 KeyPadCodeDgt5_D_Stat 1;
BA_ "WakeupSignal" SG_ 816 KeyPadCodeDgt4_D_Stat 1;
BA_ "GenSigSendType" SG_ 816 KeyPadCodeDgt4_D_Stat 3;
BA_ "U_T6_MCA_MY2020_Tx" SG_ 816 KeyPadCodeDgt4_D_Stat 1;
BA_ "U_CD542_MY2021_Tx" SG_ 816 KeyPadCodeDgt4_D_Stat 1;
BA_ "U_U55X_MY2022_Tx" SG_ 816 KeyPadCodeDgt4_D_Stat 1;
BA_ "WakeupSignal" SG_ 816 KeyPadCodeDgt3_D_Stat 1;
BA_ "GenSigSendType" SG_ 816 KeyPadCodeDgt3_D_Stat 3;
BA_ "U_T6_MCA_MY2020_Tx" SG_ 816 KeyPadCodeDgt3_D_Stat 1;
BA_ "U_CD542_MY2021_Tx" SG_ 816 KeyPadCodeDgt3_D_Stat 1;
BA_ "U_U55X_MY2022_Tx" SG_ 816 KeyPadCodeDgt3_D_Stat 1;
BA_ "WakeupSignal" SG_ 816 KeyPadCodeDgt2_D_Stat 1;
BA_ "GenSigSendType" SG_ 816 KeyPadCodeDgt2_D_Stat 3;
BA_ "U_T6_MCA_MY2020_Tx" SG_ 816 KeyPadCodeDgt2_D_Stat 1;
BA_ "U_CD542_MY2021_Tx" SG_ 816 KeyPadCodeDgt2_D_Stat 1;
BA_ "U_U55X_MY2022_Tx" SG_ 816 KeyPadCodeDgt2_D_Stat 1;
BA_ "WakeupSignal" SG_ 816 KeyPadCodeDgt1_D_Stat 1;
BA_ "GenSigSendType" SG_ 816 KeyPadCodeDgt1_D_Stat 3;
BA_ "U_T6_MCA_MY2020_Tx" SG_ 816 KeyPadCodeDgt1_D_Stat 1;
BA_ "U_CD542_MY2021_Tx" SG_ 816 KeyPadCodeDgt1_D_Stat 1;
BA_ "U_U55X_MY2022_Tx" SG_ 816 KeyPadCodeDgt1_D_Stat 1;
BA_ "WakeupSignal" SG_ 816 CntrStk2_D_RqAssoc 1;
BA_ "GenSigStartValueInteger" SG_ 816 CntrStk2_D_RqAssoc 3;
BA_ "GenSigStartValue" SG_ 816 CntrStk2_D_RqAssoc 3;
BA_ "GenSigSendType" SG_ 816 CntrStk2_D_RqAssoc 3;
BA_ "U_T6_MCA_MY2020_Tx" SG_ 816 CntrStk2_D_RqAssoc 1;
BA_ "U_CD542_MY2021_Tx" SG_ 816 CntrStk2_D_RqAssoc 1;
BA_ "U_U55X_MY2022_Tx" SG_ 816 CntrStk2_D_RqAssoc 1;
BA_ "U_CD542_MY2021_Rx" SG_ 636 WifiHtsptFqBand_D_Stat 1;
BA_ "U_P702_MY2021_Rx" SG_ 636 WifiHtsptFqBand_D_Stat 1;
BA_ "U_T6_MCA_MY2020_Rx" SG_ 636 WifiHtsptFqBand_D_Stat 1;
BA_ "U_CD542_MY2021_Rx" SG_ 636 WifiHtspt_D_Falt 1;
BA_ "U_P702_MY2021_Rx" SG_ 636 WifiHtspt_D_Falt 1;
BA_ "U_T6_MCA_MY2020_Rx" SG_ 636 WifiHtspt_D_Falt 1;
BA_ "U_CD542_MY2021_Rx" SG_ 636 WifiNoDevcCnnct_No_Actl 1;
BA_ "U_P702_MY2021_Rx" SG_ 636 WifiNoDevcCnnct_No_Actl 1;
BA_ "U_T6_MCA_MY2020_Rx" SG_ 636 WifiNoDevcCnnct_No_Actl 1;
BA_ "U_U55X_MY2022_Rx" SG_ 636 WifiNoDevcCnnct_No_Actl 1;
BA_ "U_CD542_MY2021_Rx" SG_ 636 WifiHtsptCnnct_D_Stat 1;
BA_ "U_P702_MY2021_Rx" SG_ 636 WifiHtsptCnnct_D_Stat 1;
BA_ "U_T6_MCA_MY2020_Rx" SG_ 636 WifiHtsptCnnct_D_Stat 1;
BA_ "U_U55X_MY2022_Rx" SG_ 636 WifiHtsptCnnct_D_Stat 1;
BA_ "U_CD542_MY2021_Rx" SG_ 636 Telematics_D_Falt 1;
BA_ "U_P702_MY2021_Rx" SG_ 636 Telematics_D_Falt 1;
BA_ "U_T6_MCA_MY2020_Rx" SG_ 636 Telematics_D_Falt 1;
BA_ "U_U55X_MY2022_Rx" SG_ 636 Telematics_D_Falt 1;
BA_ "U_CD542_MY2021_Rx" SG_ 636 WifiEnbl_D_Stat 1;
BA_ "U_P702_MY2021_Rx" SG_ 636 WifiEnbl_D_Stat 1;
BA_ "U_T6_MCA_MY2020_Rx" SG_ 636 WifiEnbl_D_Stat 1;
BA_ "U_U55X_MY2022_Rx" SG_ 636 WifiEnbl_D_Stat 1;
BA_ "U_CD542_MY2021_Rx" SG_ 636 WifiHtsptVisbl_D_Stat 1;
BA_ "U_P702_MY2021_Rx" SG_ 636 WifiHtsptVisbl_D_Stat 1;
BA_ "U_T6_MCA_MY2020_Rx" SG_ 636 WifiHtsptVisbl_D_Stat 1;
BA_ "U_U55X_MY2022_Rx" SG_ 636 WifiHtsptVisbl_D_Stat 1;
BA_ "U_CD542_MY2021_Rx" SG_ 636 WifiHtsptScrty_D_Stat 1;
BA_ "U_P702_MY2021_Rx" SG_ 636 WifiHtsptScrty_D_Stat 1;
BA_ "U_T6_MCA_MY2020_Rx" SG_ 636 WifiHtsptScrty_D_Stat 1;
BA_ "U_U55X_MY2022_Rx" SG_ 636 WifiHtsptScrty_D_Stat 1;
BA_ "U_CD542_MY2021_Rx" SG_ 636 WifiHtsptEnbl_D_Stat 1;
BA_ "U_P702_MY2021_Rx" SG_ 636 WifiHtsptEnbl_D_Stat 1;
BA_ "U_T6_MCA_MY2020_Rx" SG_ 636 WifiHtsptEnbl_D_Stat 1;
BA_ "U_U55X_MY2022_Rx" SG_ 636 WifiHtsptEnbl_D_Stat 1;
BA_ "U_CD542_MY2021_Rx" SG_ 636 WifiDevcListNew_B_Stat 1;
BA_ "U_P702_MY2021_Rx" SG_ 636 WifiDevcListNew_B_Stat 1;
BA_ "U_T6_MCA_MY2020_Rx" SG_ 636 WifiDevcListNew_B_Stat 1;
BA_ "U_U55X_MY2022_Rx" SG_ 636 WifiDevcListNew_B_Stat 1;
BA_ "U_CD542_MY2021_Rx" SG_ 636 WifiDataUsage_Pc_Actl 1;
BA_ "U_P702_MY2021_Rx" SG_ 636 WifiDataUsage_Pc_Actl 1;
BA_ "U_T6_MCA_MY2020_Rx" SG_ 636 WifiDataUsage_Pc_Actl 1;
BA_ "U_U55X_MY2022_Rx" SG_ 636 WifiDataUsage_Pc_Actl 1;
BA_ "U_CD542_MY2021_Rx" SG_ 636 WifiDataUsage_D_Stat 1;
BA_ "U_P702_MY2021_Rx" SG_ 636 WifiDataUsage_D_Stat 1;
BA_ "U_T6_MCA_MY2020_Rx" SG_ 636 WifiDataUsage_D_Stat 1;
BA_ "U_U55X_MY2022_Rx" SG_ 636 WifiDataUsage_D_Stat 1;
BA_ "GenSigStartValueInteger" SG_ 636 ModemSigStren_D_Stat 6;
BA_ "GenSigStartValue" SG_ 636 ModemSigStren_D_Stat 6;
BA_ "U_CD542_MY2021_Rx" SG_ 636 ModemSigStren_D_Stat 1;
BA_ "U_P702_MY2021_Rx" SG_ 636 ModemSigStren_D_Stat 1;
BA_ "U_T6_MCA_MY2020_Rx" SG_ 636 ModemSigStren_D_Stat 1;
BA_ "U_CD542_MY2021_Rx" SG_ 636 ModemTechnology_D2_Stat 1;
BA_ "U_T6_MCA_MY2020_Rx" SG_ 636 ModemTechnology_D2_Stat 1;
BA_ "U_U55X_MY2022_Rx" SG_ 636 ModemTechnology_D2_Stat 1;
BA_ "U_P702_MY2021_Rx" SG_ 636 ModemTechnology_D2_Stat 1;
BA_ "U_CD542_MY2021_Rx" SG_ 636 WifiHtsptCrdntl_B_Stat 1;
BA_ "U_T6_MCA_MY2020_Rx" SG_ 636 WifiHtsptCrdntl_B_Stat 1;
BA_ "U_U55X_MY2022_Rx" SG_ 636 WifiHtsptCrdntl_B_Stat 1;
BA_ "U_CD542_MY2021_Rx" SG_ 636 WifiHtsptFq_D_Avail 1;
BA_ "U_P702_MY2021_Rx" SG_ 636 WifiHtsptFq_D_Avail 1;
BA_ "U_T6_MCA_MY2020_Rx" SG_ 636 WifiHtsptFq_D_Avail 1;
BA_ "U_CD542_MY2021_Rx" SG_ 636 WifiDataUsageOn_D_Stat 1;
BA_ "U_P702_MY2021_Rx" SG_ 636 WifiDataUsageOn_D_Stat 1;
BA_ "U_T6_MCA_MY2020_Rx" SG_ 636 WifiDataUsageOn_D_Stat 1;
BA_ "U_U55X_MY2022_Rx" SG_ 636 WifiDataUsageOn_D_Stat 1;
BA_ "GenSigSendType" SG_ 807 ElDistTripUnit_D_Stat 3;
BA_ "U_T6_MCA_MY2020_Rx" SG_ 807 ElDistTripUnit_D_Stat 1;
BA_ "U_CD542_MY2021_Rx" SG_ 807 ElDistTripUnit_D_Stat 1;
BA_ "U_U55X_MY2022_Rx" SG_ 807 ElDistTripUnit_D_Stat 1;
BA_ "U_T6_MCA_MY2020_Tx" SG_ 807 ElDistTripUnit_D_Stat 1;
BA_ "U_CD542_MY2021_Tx" SG_ 807 ElDistTripUnit_D_Stat 1;
BA_ "U_U55X_MY2022_Tx" SG_ 807 ElDistTripUnit_D_Stat 1;
BA_ "GenSigSendType" SG_ 807 ElDistTrip2_No_Dsply 3;
BA_ "U_T6_MCA_MY2020_Rx" SG_ 807 ElDistTrip2_No_Dsply 1;
BA_ "U_CD542_MY2021_Rx" SG_ 807 ElDistTrip2_No_Dsply 1;
BA_ "U_U55X_MY2022_Rx" SG_ 807 ElDistTrip2_No_Dsply 1;
BA_ "U_T6_MCA_MY2020_Tx" SG_ 807 ElDistTrip2_No_Dsply 1;
BA_ "U_CD542_MY2021_Tx" SG_ 807 ElDistTrip2_No_Dsply 1;
BA_ "U_U55X_MY2022_Tx" SG_ 807 ElDistTrip2_No_Dsply 1;
BA_ "GenSigSendType" SG_ 807 ElDistTrip1_No_Dsply 3;
BA_ "U_T6_MCA_MY2020_Rx" SG_ 807 ElDistTrip1_No_Dsply 1;
BA_ "U_CD542_MY2021_Rx" SG_ 807 ElDistTrip1_No_Dsply 1;
BA_ "U_U55X_MY2022_Rx" SG_ 807 ElDistTrip1_No_Dsply 1;
BA_ "U_T6_MCA_MY2020_Tx" SG_ 807 ElDistTrip1_No_Dsply 1;
BA_ "U_CD542_MY2021_Tx" SG_ 807 ElDistTrip1_No_Dsply 1;
BA_ "U_U55X_MY2022_Tx" SG_ 807 ElDistTrip1_No_Dsply 1;
BA_ "GenSigSendType" SG_ 807 ElDistTripCur_No_Dsply 3;
BA_ "U_CD542_MY2021_Rx" SG_ 807 ElDistTripCur_No_Dsply 1;
BA_ "U_U55X_MY2022_Rx" SG_ 807 ElDistTripCur_No_Dsply 1;
BA_ "U_CD542_MY2021_Tx" SG_ 807 ElDistTripCur_No_Dsply 1;
BA_ "U_U55X_MY2022_Tx" SG_ 807 ElDistTripCur_No_Dsply 1;
BA_ "U_U55X_MY2022_Rx" SG_ 974 EngExhMdeHrStrt_D_Stat 1;
BA_ "U_U55X_MY2022_Rx" SG_ 974 EngExhMdeHrEnd_D_Stat 1;
BA_ "U_U55X_MY2022_Rx" SG_ 974 EngExhMdeHrEnbl_D_Stat 1;
BA_ "U_CD542_MY2021_Rx" SG_ 974 DcacOut_Pw_DsplyMx 1;
BA_ "U_U55X_MY2022_Rx" SG_ 974 DcacOut_Pw_DsplyMx 1;
BA_ "U_CD542_MY2021_Rx" SG_ 974 DcacOut1_Pw_Dsply 1;
BA_ "U_U55X_MY2022_Rx" SG_ 974 DcacOut1_Pw_Dsply 1;
BA_ "U_CD542_MY2021_Rx" SG_ 974 DcacOut2_Pw_Dsply 1;
BA_ "U_U55X_MY2022_Rx" SG_ 974 DcacOut2_Pw_Dsply 1;
BA_ "GenSigStartValueInteger" SG_ 974 DcacHw_D_Confg 1;
BA_ "U_CD542_MY2021_Rx" SG_ 974 DcacHw_D_Confg 1;
BA_ "U_U55X_MY2022_Rx" SG_ 974 DcacHw_D_Confg 1;
BA_ "GenSigStartValueInteger" SG_ 974 DcacFaltMsgTxt_D_Rq 1;
BA_ "U_CD542_MY2021_Rx" SG_ 974 DcacFaltMsgTxt_D_Rq 1;
BA_ "U_U55X_MY2022_Rx" SG_ 974 DcacFaltMsgTxt_D_Rq 1;
BA_ "U_CD542_MY2021_Rx" SG_ 974 DcacLoFuelMsgTxt_D_Rq 1;
BA_ "U_U55X_MY2022_Rx" SG_ 974 DcacLoFuelMsgTxt_D_Rq 1;
BA_ "U_CD542_MY2021_Rx" SG_ 974 DcacEngOnMsgTxt_D_Rq 1;
BA_ "U_U55X_MY2022_Rx" SG_ 974 DcacEngOnMsgTxt_D_Rq 1;
BA_ "GenSigStartValueInteger" SG_ 974 DcacElPw_D_Stat 1;
BA_ "GenSigStartValue" SG_ 974 DcacElPw_D_Stat 1;
BA_ "U_CD542_MY2021_Rx" SG_ 974 DcacElPw_D_Stat 1;
BA_ "U_U55X_MY2022_Rx" SG_ 974 DcacElPw_D_Stat 1;
BA_ "U_T6_MCA_MY2020_Rx" SG_ 805 InstFeTripUnit_D_Stat 1;
BA_ "U_U55X_MY2022_Rx" SG_ 805 InstFeTripUnit_D_Stat 1;
BA_ "U_CD542_MY2021_Rx" SG_ 805 InstFeTripUnit_D_Stat 1;
BA_ "U_T6_MCA_MY2020_Tx" SG_ 805 InstFeTripUnit_D_Stat 1;
BA_ "U_CD542_MY2021_Tx" SG_ 805 InstFeTripUnit_D_Stat 1;
BA_ "U_U55X_MY2022_Tx" SG_ 805 InstFeTripUnit_D_Stat 1;
BA_ "U_T6_MCA_MY2020_Rx" SG_ 805 InstFe_No_Dsply 1;
BA_ "U_U55X_MY2022_Rx" SG_ 805 InstFe_No_Dsply 1;
BA_ "U_CD542_MY2021_Rx" SG_ 805 InstFe_No_Dsply 1;
BA_ "U_T6_MCA_MY2020_Tx" SG_ 805 InstFe_No_Dsply 1;
BA_ "U_CD542_MY2021_Tx" SG_ 805 InstFe_No_Dsply 1;
BA_ "U_U55X_MY2022_Tx" SG_ 805 InstFe_No_Dsply 1;
BA_ "GenSigSendType" SG_ 804 InstFeMax_No_Dsply 3;
BA_ "U_T6_MCA_MY2020_Rx" SG_ 804 InstFeMax_No_Dsply 1;
BA_ "U_U55X_MY2022_Rx" SG_ 804 InstFeMax_No_Dsply 1;
BA_ "U_CD542_MY2021_Rx" SG_ 804 InstFeMax_No_Dsply 1;
BA_ "U_T6_MCA_MY2020_Tx" SG_ 804 InstFeMax_No_Dsply 1;
BA_ "U_CD542_MY2021_Tx" SG_ 804 InstFeMax_No_Dsply 1;
BA_ "U_U55X_MY2022_Tx" SG_ 804 InstFeMax_No_Dsply 1;
BA_ "GenSigSendType" SG_ 804 ConsInstActv_B_Dsply 3;
BA_ "U_T6_MCA_MY2020_Rx" SG_ 804 ConsInstActv_B_Dsply 1;
BA_ "U_U55X_MY2022_Rx" SG_ 804 ConsInstActv_B_Dsply 1;
BA_ "U_CD542_MY2021_Rx" SG_ 804 ConsInstActv_B_Dsply 1;
BA_ "U_T6_MCA_MY2020_Tx" SG_ 804 ConsInstActv_B_Dsply 1;
BA_ "U_CD542_MY2021_Tx" SG_ 804 ConsInstActv_B_Dsply 1;
BA_ "U_U55X_MY2022_Tx" SG_ 804 ConsInstActv_B_Dsply 1;
BA_ "GenSigSendType" SG_ 804 ConsInst_No_Dsply 3;
BA_ "U_T6_MCA_MY2020_Rx" SG_ 804 ConsInst_No_Dsply 1;
BA_ "U_U55X_MY2022_Rx" SG_ 804 ConsInst_No_Dsply 1;
BA_ "U_CD542_MY2021_Rx" SG_ 804 ConsInst_No_Dsply 1;
BA_ "U_T6_MCA_MY2020_Tx" SG_ 804 ConsInst_No_Dsply 1;
BA_ "U_CD542_MY2021_Tx" SG_ 804 ConsInst_No_Dsply 1;
BA_ "U_U55X_MY2022_Tx" SG_ 804 ConsInst_No_Dsply 1;
BA_ "GenSigSendType" SG_ 804 ConsInstUnit_D_Stat 3;
BA_ "U_T6_MCA_MY2020_Rx" SG_ 804 ConsInstUnit_D_Stat 1;
BA_ "U_U55X_MY2022_Rx" SG_ 804 ConsInstUnit_D_Stat 1;
BA_ "U_CD542_MY2021_Tx" SG_ 804 ConsInstUnit_D_Stat 1;
BA_ "U_U55X_MY2022_Tx" SG_ 804 ConsInstUnit_D_Stat 1;
BA_ "GenSigSendType" SG_ 803 DistTripUnit_D_Stat 3;
BA_ "U_T6_MCA_MY2020_Rx" SG_ 803 DistTripUnit_D_Stat 1;
BA_ "U_CD542_MY2021_Rx" SG_ 803 DistTripUnit_D_Stat 1;
BA_ "U_U55X_MY2022_Rx" SG_ 803 DistTripUnit_D_Stat 1;
BA_ "U_T6_MCA_MY2020_Tx" SG_ 803 DistTripUnit_D_Stat 1;
BA_ "U_CD542_MY2021_Tx" SG_ 803 DistTripUnit_D_Stat 1;
BA_ "U_U55X_MY2022_Tx" SG_ 803 DistTripUnit_D_Stat 1;
BA_ "GenSigSendType" SG_ 803 DistTrip2_No_Dsply 3;
BA_ "U_T6_MCA_MY2020_Rx" SG_ 803 DistTrip2_No_Dsply 1;
BA_ "U_CD542_MY2021_Rx" SG_ 803 DistTrip2_No_Dsply 1;
BA_ "U_U55X_MY2022_Rx" SG_ 803 DistTrip2_No_Dsply 1;
BA_ "U_T6_MCA_MY2020_Tx" SG_ 803 DistTrip2_No_Dsply 1;
BA_ "U_CD542_MY2021_Tx" SG_ 803 DistTrip2_No_Dsply 1;
BA_ "U_U55X_MY2022_Tx" SG_ 803 DistTrip2_No_Dsply 1;
BA_ "GenSigSendType" SG_ 803 DistTrip1_No_Dsply 3;
BA_ "U_T6_MCA_MY2020_Rx" SG_ 803 DistTrip1_No_Dsply 1;
BA_ "U_CD542_MY2021_Rx" SG_ 803 DistTrip1_No_Dsply 1;
BA_ "U_U55X_MY2022_Rx" SG_ 803 DistTrip1_No_Dsply 1;
BA_ "U_T6_MCA_MY2020_Tx" SG_ 803 DistTrip1_No_Dsply 1;
BA_ "U_CD542_MY2021_Tx" SG_ 803 DistTrip1_No_Dsply 1;
BA_ "U_U55X_MY2022_Tx" SG_ 803 DistTrip1_No_Dsply 1;
BA_ "GenSigSendType" SG_ 802 AvgFeTripUnit_D_Stat 3;
BA_ "U_T6_MCA_MY2020_Rx" SG_ 802 AvgFeTripUnit_D_Stat 1;
BA_ "U_U55X_MY2022_Rx" SG_ 802 AvgFeTripUnit_D_Stat 1;
BA_ "U_CD542_MY2021_Rx" SG_ 802 AvgFeTripUnit_D_Stat 1;
BA_ "U_T6_MCA_MY2020_Tx" SG_ 802 AvgFeTripUnit_D_Stat 1;
BA_ "U_CD542_MY2021_Tx" SG_ 802 AvgFeTripUnit_D_Stat 1;
BA_ "U_U55X_MY2022_Tx" SG_ 802 AvgFeTripUnit_D_Stat 1;
BA_ "GenSigSendType" SG_ 802 AvgFeTrip2Actv_B_Dsply 3;
BA_ "U_T6_MCA_MY2020_Rx" SG_ 802 AvgFeTrip2Actv_B_Dsply 1;
BA_ "U_U55X_MY2022_Rx" SG_ 802 AvgFeTrip2Actv_B_Dsply 1;
BA_ "U_CD542_MY2021_Rx" SG_ 802 AvgFeTrip2Actv_B_Dsply 1;
BA_ "U_T6_MCA_MY2020_Tx" SG_ 802 AvgFeTrip2Actv_B_Dsply 1;
BA_ "U_CD542_MY2021_Tx" SG_ 802 AvgFeTrip2Actv_B_Dsply 1;
BA_ "U_U55X_MY2022_Tx" SG_ 802 AvgFeTrip2Actv_B_Dsply 1;
BA_ "GenSigSendType" SG_ 802 AvgFeTrip2_No_Dsply 3;
BA_ "U_T6_MCA_MY2020_Rx" SG_ 802 AvgFeTrip2_No_Dsply 1;
BA_ "U_U55X_MY2022_Rx" SG_ 802 AvgFeTrip2_No_Dsply 1;
BA_ "U_CD542_MY2021_Rx" SG_ 802 AvgFeTrip2_No_Dsply 1;
BA_ "U_T6_MCA_MY2020_Tx" SG_ 802 AvgFeTrip2_No_Dsply 1;
BA_ "U_CD542_MY2021_Tx" SG_ 802 AvgFeTrip2_No_Dsply 1;
BA_ "U_U55X_MY2022_Tx" SG_ 802 AvgFeTrip2_No_Dsply 1;
BA_ "GenSigSendType" SG_ 802 AvgFeTrip1Actv_B_Dsply 3;
BA_ "U_T6_MCA_MY2020_Rx" SG_ 802 AvgFeTrip1Actv_B_Dsply 1;
BA_ "U_U55X_MY2022_Rx" SG_ 802 AvgFeTrip1Actv_B_Dsply 1;
BA_ "U_CD542_MY2021_Rx" SG_ 802 AvgFeTrip1Actv_B_Dsply 1;
BA_ "U_T6_MCA_MY2020_Tx" SG_ 802 AvgFeTrip1Actv_B_Dsply 1;
BA_ "U_CD542_MY2021_Tx" SG_ 802 AvgFeTrip1Actv_B_Dsply 1;
BA_ "U_U55X_MY2022_Tx" SG_ 802 AvgFeTrip1Actv_B_Dsply 1;
BA_ "GenSigSendType" SG_ 802 AvgFeTrip1_No_Dsply 3;
BA_ "U_T6_MCA_MY2020_Rx" SG_ 802 AvgFeTrip1_No_Dsply 1;
BA_ "U_U55X_MY2022_Rx" SG_ 802 AvgFeTrip1_No_Dsply 1;
BA_ "U_CD542_MY2021_Rx" SG_ 802 AvgFeTrip1_No_Dsply 1;
BA_ "U_T6_MCA_MY2020_Tx" SG_ 802 AvgFeTrip1_No_Dsply 1;
BA_ "U_CD542_MY2021_Tx" SG_ 802 AvgFeTrip1_No_Dsply 1;
BA_ "U_U55X_MY2022_Tx" SG_ 802 AvgFeTrip1_No_Dsply 1;
BA_ "GenSigSendType" SG_ 802 AvgFeActv_B_Dsply 3;
BA_ "U_T6_MCA_MY2020_Rx" SG_ 802 AvgFeActv_B_Dsply 1;
BA_ "U_U55X_MY2022_Rx" SG_ 802 AvgFeActv_B_Dsply 1;
BA_ "U_CD542_MY2021_Rx" SG_ 802 AvgFeActv_B_Dsply 1;
BA_ "U_T6_MCA_MY2020_Tx" SG_ 802 AvgFeActv_B_Dsply 1;
BA_ "U_CD542_MY2021_Tx" SG_ 802 AvgFeActv_B_Dsply 1;
BA_ "U_U55X_MY2022_Tx" SG_ 802 AvgFeActv_B_Dsply 1;
BA_ "GenSigSendType" SG_ 802 AvgFe_No_Dsply 3;
BA_ "U_T6_MCA_MY2020_Rx" SG_ 802 AvgFe_No_Dsply 1;
BA_ "U_U55X_MY2022_Rx" SG_ 802 AvgFe_No_Dsply 1;
BA_ "U_CD542_MY2021_Rx" SG_ 802 AvgFe_No_Dsply 1;
BA_ "U_T6_MCA_MY2020_Tx" SG_ 802 AvgFe_No_Dsply 1;
BA_ "U_CD542_MY2021_Tx" SG_ 802 AvgFe_No_Dsply 1;
BA_ "U_U55X_MY2022_Tx" SG_ 802 AvgFe_No_Dsply 1;
BA_ "GenSigSendType" SG_ 812 TimerTrip2_T_Dsply 3;
BA_ "U_T6_MCA_MY2020_Rx" SG_ 812 TimerTrip2_T_Dsply 1;
BA_ "U_CD542_MY2021_Rx" SG_ 812 TimerTrip2_T_Dsply 1;
BA_ "U_U55X_MY2022_Rx" SG_ 812 TimerTrip2_T_Dsply 1;
BA_ "U_T6_MCA_MY2020_Tx" SG_ 812 TimerTrip2_T_Dsply 1;
BA_ "U_U55X_MY2022_Tx" SG_ 812 TimerTrip2_T_Dsply 1;
BA_ "GenSigSendType" SG_ 812 TimerTrip1_T_Dsply 3;
BA_ "U_T6_MCA_MY2020_Rx" SG_ 812 TimerTrip1_T_Dsply 1;
BA_ "U_CD542_MY2021_Rx" SG_ 812 TimerTrip1_T_Dsply 1;
BA_ "U_U55X_MY2022_Rx" SG_ 812 TimerTrip1_T_Dsply 1;
BA_ "U_T6_MCA_MY2020_Tx" SG_ 812 TimerTrip1_T_Dsply 1;
BA_ "U_CD542_MY2021_Tx" SG_ 812 TimerTrip1_T_Dsply 1;
BA_ "U_U55X_MY2022_Tx" SG_ 812 TimerTrip1_T_Dsply 1;
BA_ "U_T6_MCA_MY2020_Rx" SG_ 885 VehStrtInhbt_T_Dsply 1;
BA_ "U_CD542_MY2021_Rx" SG_ 885 VehStrtInhbt_T_Dsply 1;
BA_ "U_U55X_MY2022_Rx" SG_ 885 VehStrtInhbt_T_Dsply 1;
BA_ "U_T6_MCA_MY2020_Tx" SG_ 885 VehStrtInhbt_T_Dsply 1;
BA_ "ECGUsedTxSignal" SG_ 885 VehStrtInhbt_T_Dsply 1;
BA_ "U_CD542_MY2021_Tx" SG_ 885 VehStrtInhbt_T_Dsply 1;
BA_ "U_U55X_MY2022_Tx" SG_ 885 VehStrtInhbt_T_Dsply 1;
BA_ "U_T6_MCA_MY2020_Rx" SG_ 885 VehStrtInhbt_D_Dsply 1;
BA_ "U_CD542_MY2021_Rx" SG_ 885 VehStrtInhbt_D_Dsply 1;
BA_ "U_U55X_MY2022_Rx" SG_ 885 VehStrtInhbt_D_Dsply 1;
BA_ "U_T6_MCA_MY2020_Tx" SG_ 885 VehStrtInhbt_D_Dsply 1;
BA_ "ECGUsedTxSignal" SG_ 885 VehStrtInhbt_D_Dsply 1;
BA_ "U_CD542_MY2021_Tx" SG_ 885 VehStrtInhbt_D_Dsply 1;
BA_ "U_U55X_MY2022_Tx" SG_ 885 VehStrtInhbt_D_Dsply 1;
BA_ "U_T6_MCA_MY2020_Rx" SG_ 885 OtaActv_D_Stat 1;
BA_ "U_CD542_MY2021_Rx" SG_ 885 OtaActv_D_Stat 1;
BA_ "U_U55X_MY2022_Rx" SG_ 885 OtaActv_D_Stat 1;
BA_ "U_T6_MCA_MY2020_Tx" SG_ 885 OtaActv_D_Stat 1;
BA_ "ECGUsedTxSignal" SG_ 885 OtaActv_D_Stat 1;
BA_ "U_CD542_MY2021_Tx" SG_ 885 OtaActv_D_Stat 1;
BA_ "U_U55X_MY2022_Tx" SG_ 885 OtaActv_D_Stat 1;
BA_ "U_T6_MCA_MY2020_Rx" SG_ 784 TrlrTireTSensRr_D_Stat 1;
BA_ "U_U55X_MY2022_Rx" SG_ 784 TrlrTireTSensRr_D_Stat 1;
BA_ "U_T6_MCA_MY2020_Rx" SG_ 784 TrlrTireTSensRm_D_Stat 1;
BA_ "U_U55X_MY2022_Rx" SG_ 784 TrlrTireTSensRm_D_Stat 1;
BA_ "U_T6_MCA_MY2020_Rx" SG_ 784 TrlrTireTSensRf_D_Stat 1;
BA_ "U_U55X_MY2022_Rx" SG_ 784 TrlrTireTSensRf_D_Stat 1;
BA_ "U_T6_MCA_MY2020_Rx" SG_ 784 TrlrTireTSensLr_D_Stat 1;
BA_ "U_U55X_MY2022_Rx" SG_ 784 TrlrTireTSensLr_D_Stat 1;
BA_ "U_T6_MCA_MY2020_Rx" SG_ 784 TrlrTireTSensLm_D_Stat 1;
BA_ "U_U55X_MY2022_Rx" SG_ 784 TrlrTireTSensLm_D_Stat 1;
BA_ "U_T6_MCA_MY2020_Rx" SG_ 784 TrlrTireTSensLf_D_Stat 1;
BA_ "U_U55X_MY2022_Rx" SG_ 784 TrlrTireTSensLf_D_Stat 1;
BA_ "GenSigStartValueInteger" SG_ 784 TrlrTireTempSys_D_Stat 3;
BA_ "GenSigStartValue" SG_ 784 TrlrTireTempSys_D_Stat 3;
BA_ "U_T6_MCA_MY2020_Rx" SG_ 784 TrlrTireTempSys_D_Stat 1;
BA_ "U_U55X_MY2022_Rx" SG_ 784 TrlrTireTempSys_D_Stat 1;
BA_ "GenSigStartValue" SG_ 784 TrlrTireRr_T_Actl 253;
BA_ "U_T6_MCA_MY2020_Rx" SG_ 784 TrlrTireRr_T_Actl 1;
BA_ "U_U55X_MY2022_Rx" SG_ 784 TrlrTireRr_T_Actl 1;
BA_ "GenSigStartValue" SG_ 784 TrlrTireRm_T_Actl 253;
BA_ "U_T6_MCA_MY2020_Rx" SG_ 784 TrlrTireRm_T_Actl 1;
BA_ "U_U55X_MY2022_Rx" SG_ 784 TrlrTireRm_T_Actl 1;
BA_ "GenSigStartValue" SG_ 784 TrlrTireRf_T_Actl 253;
BA_ "U_T6_MCA_MY2020_Rx" SG_ 784 TrlrTireRf_T_Actl 1;
BA_ "U_U55X_MY2022_Rx" SG_ 784 TrlrTireRf_T_Actl 1;
BA_ "GenSigStartValue" SG_ 784 TrlrTireLr_T_Actl 253;
BA_ "U_T6_MCA_MY2020_Rx" SG_ 784 TrlrTireLr_T_Actl 1;
BA_ "U_U55X_MY2022_Rx" SG_ 784 TrlrTireLr_T_Actl 1;
BA_ "GenSigStartValue" SG_ 784 TrlrTireLm_T_Actl 253;
BA_ "U_T6_MCA_MY2020_Rx" SG_ 784 TrlrTireLm_T_Actl 1;
BA_ "U_U55X_MY2022_Rx" SG_ 784 TrlrTireLm_T_Actl 1;
BA_ "GenSigStartValue" SG_ 784 TrlrTireLf_T_Actl 253;
BA_ "U_T6_MCA_MY2020_Rx" SG_ 784 TrlrTireLf_T_Actl 1;
BA_ "U_U55X_MY2022_Rx" SG_ 784 TrlrTireLf_T_Actl 1;
BA_ "GenSigSendType" SG_ 1119 LocationServices_2 1;
BA_ "U_T6_MCA_MY2020_Rx" SG_ 1119 LocationServices_2 1;
BA_ "ECGUsedRxSignal" SG_ 1119 LocationServices_2 1;
BA_ "U_CD542_MY2021_Rx" SG_ 1119 LocationServices_2 1;
BA_ "U_U55X_MY2022_Rx" SG_ 1119 LocationServices_2 1;
BA_ "U_P702_MY2021_Tx" SG_ 1119 LocationServices_2 1;
BA_ "U_T6_MCA_MY2020_Tx" SG_ 1119 LocationServices_2 1;
BA_ "U_CD542_MY2021_Tx" SG_ 1119 LocationServices_2 1;
BA_ "U_U55X_MY2022_Tx" SG_ 1119 LocationServices_2 1;
BA_ "GenSigSendType" SG_ 1118 LocationServices_1 1;
BA_ "U_T6_MCA_MY2020_Rx" SG_ 1118 LocationServices_1 1;
BA_ "ECGUsedRxSignal" SG_ 1118 LocationServices_1 1;
BA_ "U_CD542_MY2021_Rx" SG_ 1118 LocationServices_1 1;
BA_ "U_U55X_MY2022_Rx" SG_ 1118 LocationServices_1 1;
BA_ "U_P702_MY2021_Tx" SG_ 1118 LocationServices_1 1;
BA_ "U_T6_MCA_MY2020_Tx" SG_ 1118 LocationServices_1 1;
BA_ "U_CD542_MY2021_Tx" SG_ 1118 LocationServices_1 1;
BA_ "U_U55X_MY2022_Tx" SG_ 1118 LocationServices_1 1;
BA_ "GenSigSendType" SG_ 290 WifiHtsptFqBand_D_Rq 3;
BA_ "U_CD542_MY2021_Tx" SG_ 290 WifiHtsptFqBand_D_Rq 1;
BA_ "U_U55X_MY2022_Tx" SG_ 290 WifiHtsptFqBand_D_Rq 1;
BA_ "U_P702_MY2021_Tx" SG_ 290 WifiHtsptFqBand_D_Rq 1;
BA_ "U_T6_MCA_MY2020_Tx" SG_ 290 WifiHtsptFqBand_D_Rq 1;
BA_ "GenSigSendType" SG_ 290 WifiHtsptTrial_D_RqDrv 3;
BA_ "U_CD542_MY2021_Tx" SG_ 290 WifiHtsptTrial_D_RqDrv 1;
BA_ "U_U55X_MY2022_Tx" SG_ 290 WifiHtsptTrial_D_RqDrv 1;
BA_ "U_P702_MY2021_Tx" SG_ 290 WifiHtsptTrial_D_RqDrv 1;
BA_ "U_T6_MCA_MY2020_Tx" SG_ 290 WifiHtsptTrial_D_RqDrv 1;
BA_ "GenSigSendType" SG_ 290 WifiHtsptEnbl_D_Rq 3;
BA_ "U_CD542_MY2021_Tx" SG_ 290 WifiHtsptEnbl_D_Rq 1;
BA_ "U_U55X_MY2022_Tx" SG_ 290 WifiHtsptEnbl_D_Rq 1;
BA_ "U_P702_MY2021_Tx" SG_ 290 WifiHtsptEnbl_D_Rq 1;
BA_ "U_T6_MCA_MY2020_Tx" SG_ 290 WifiHtsptEnbl_D_Rq 1;
BA_ "GenSigStartValueInteger" SG_ 290 WifiRemoveIndx_No_Rq 20;
BA_ "GenSigStartValue" SG_ 290 WifiRemoveIndx_No_Rq 20;
BA_ "U_P702_MY2021_Tx" SG_ 290 WifiRemoveIndx_No_Rq 1;
BA_ "U_T6_MCA_MY2020_Tx" SG_ 290 WifiRemoveIndx_No_Rq 1;
BA_ "U_CD542_MY2021_Tx" SG_ 290 WifiRemoveIndx_No_Rq 1;
BA_ "U_U55X_MY2022_Tx" SG_ 290 WifiRemoveIndx_No_Rq 1;
BA_ "GenSigSendType" SG_ 290 WifiRemoveDevc_D_Rq 3;
BA_ "U_P702_MY2021_Tx" SG_ 290 WifiRemoveDevc_D_Rq 1;
BA_ "U_T6_MCA_MY2020_Tx" SG_ 290 WifiRemoveDevc_D_Rq 1;
BA_ "U_CD542_MY2021_Tx" SG_ 290 WifiRemoveDevc_D_Rq 1;
BA_ "U_U55X_MY2022_Tx" SG_ 290 WifiRemoveDevc_D_Rq 1;
BA_ "GenSigSendType" SG_ 290 WifiHtsptVisbl_D_Rq 3;
BA_ "U_P702_MY2021_Tx" SG_ 290 WifiHtsptVisbl_D_Rq 1;
BA_ "U_T6_MCA_MY2020_Tx" SG_ 290 WifiHtsptVisbl_D_Rq 1;
BA_ "U_CD542_MY2021_Tx" SG_ 290 WifiHtsptVisbl_D_Rq 1;
BA_ "U_U55X_MY2022_Tx" SG_ 290 WifiHtsptVisbl_D_Rq 1;
BA_ "GenSigSendType" SG_ 290 WifiHtsptMacAddr_B_Rq 3;
BA_ "U_P702_MY2021_Tx" SG_ 290 WifiHtsptMacAddr_B_Rq 1;
BA_ "U_T6_MCA_MY2020_Tx" SG_ 290 WifiHtsptMacAddr_B_Rq 1;
BA_ "U_CD542_MY2021_Tx" SG_ 290 WifiHtsptMacAddr_B_Rq 1;
BA_ "U_U55X_MY2022_Tx" SG_ 290 WifiHtsptMacAddr_B_Rq 1;
BA_ "U_P702_MY2021_Tx" SG_ 290 WifiDevcListSize_D_Rq 1;
BA_ "U_T6_MCA_MY2020_Tx" SG_ 290 WifiDevcListSize_D_Rq 1;
BA_ "U_CD542_MY2021_Tx" SG_ 290 WifiDevcListSize_D_Rq 1;
BA_ "U_U55X_MY2022_Tx" SG_ 290 WifiDevcListSize_D_Rq 1;
BA_ "GenSigStartValueInteger" SG_ 290 WifiDevcListIndx_No_Rq 22;
BA_ "GenSigStartValue" SG_ 290 WifiDevcListIndx_No_Rq 22;
BA_ "U_P702_MY2021_Tx" SG_ 290 WifiDevcListIndx_No_Rq 1;
BA_ "U_T6_MCA_MY2020_Tx" SG_ 290 WifiDevcListIndx_No_Rq 1;
BA_ "U_CD542_MY2021_Tx" SG_ 290 WifiDevcListIndx_No_Rq 1;
BA_ "U_U55X_MY2022_Tx" SG_ 290 WifiDevcListIndx_No_Rq 1;
BA_ "GenSigSendType" SG_ 290 WifiDevcList_D_Rq 3;
BA_ "U_P702_MY2021_Tx" SG_ 290 WifiDevcList_D_Rq 1;
BA_ "U_T6_MCA_MY2020_Tx" SG_ 290 WifiDevcList_D_Rq 1;
BA_ "U_CD542_MY2021_Tx" SG_ 290 WifiDevcList_D_Rq 1;
BA_ "U_U55X_MY2022_Tx" SG_ 290 WifiDevcList_D_Rq 1;
BA_ "GenSigSendType" SG_ 290 WifiDataUsage_D_Rq 3;
BA_ "U_P702_MY2021_Tx" SG_ 290 WifiDataUsage_D_Rq 1;
BA_ "U_T6_MCA_MY2020_Tx" SG_ 290 WifiDataUsage_D_Rq 1;
BA_ "U_CD542_MY2021_Tx" SG_ 290 WifiDataUsage_D_Rq 1;
BA_ "U_U55X_MY2022_Tx" SG_ 290 WifiDataUsage_D_Rq 1;
BA_ "GenSigSendType" SG_ 290 WifiCarrierInfo_B_Rq 3;
BA_ "U_P702_MY2021_Tx" SG_ 290 WifiCarrierInfo_B_Rq 1;
BA_ "U_T6_MCA_MY2020_Tx" SG_ 290 WifiCarrierInfo_B_Rq 1;
BA_ "U_CD542_MY2021_Tx" SG_ 290 WifiCarrierInfo_B_Rq 1;
BA_ "U_U55X_MY2022_Tx" SG_ 290 WifiCarrierInfo_B_Rq 1;
BA_ "GenSigSendType" SG_ 290 WifiHtsptScrty_D_Rq 3;
BA_ "U_CD542_MY2021_Tx" SG_ 290 WifiHtsptScrty_D_Rq 1;
BA_ "U_U55X_MY2022_Tx" SG_ 290 WifiHtsptScrty_D_Rq 1;
BA_ "U_P702_MY2021_Tx" SG_ 290 WifiHtsptScrty_D_Rq 1;
BA_ "U_T6_MCA_MY2020_Tx" SG_ 290 WifiHtsptScrty_D_Rq 1;
BA_ "GenSigSendType" SG_ 2612101336 PARSEDPushFcGWM_ECGtoIPC 3;
BA_ "U_T6_MCA_MY2020_Rx" SG_ 2612101336 PARSEDPushFcGWM_ECGtoIPC 1;
BA_ "U_CD542_MY2021_Rx" SG_ 2612101336 PARSEDPushFcGWM_ECGtoIPC 1;
BA_ "U_U55X_MY2022_Rx" SG_ 2612101336 PARSEDPushFcGWM_ECGtoIPC 1;
BA_ "U_T6_MCA_MY2020_Tx" SG_ 2612101336 PARSEDPushFcGWM_ECGtoIPC 1;
BA_ "ECGUsedTxSignal" SG_ 2612101336 PARSEDPushFcGWM_ECGtoIPC 1;
BA_ "U_CD542_MY2021_Tx" SG_ 2612101336 PARSEDPushFcGWM_ECGtoIPC 1;
BA_ "U_U55X_MY2022_Tx" SG_ 2612101336 PARSEDPushFcGWM_ECGtoIPC 1;
BA_ "U_T6_MCA_MY2020_Rx" SG_ 1043 SelDrvMdeHmi02_D_Rq 1;
BA_ "U_U55X_MY2022_Rx" SG_ 1043 SelDrvMdeHmi02_D_Rq 1;
BA_ "U_T6_MCA_MY2020_Rx" SG_ 1043 SelDrvMdeHmi04_D_Rq 1;
BA_ "U_U55X_MY2022_Rx" SG_ 1043 SelDrvMdeHmi04_D_Rq 1;
BA_ "GenSigStartValue" SG_ 1043 IndvMdeSusp_No_Stat 15;
BA_ "U_T6_MCA_MY2020_Rx" SG_ 1043 IndvMdeSusp_No_Stat 1;
BA_ "GenSigStartValue" SG_ 1043 IndvMdeSte_No_Stat 15;
BA_ "U_T6_MCA_MY2020_Rx" SG_ 1043 IndvMdeSte_No_Stat 1;
BA_ "GenSigStartValue" SG_ 1043 IndvMdeSel_No_Rq 15;
BA_ "U_T6_MCA_MY2020_Rx" SG_ 1043 IndvMdeSel_No_Rq 1;
BA_ "U_T6_MCA_MY2020_Rx" SG_ 1043 IndvMdeSel_D_Stat 1;
BA_ "U_T6_MCA_MY2020_Rx" SG_ 1043 IndvMdeMsgTxt_D_Rq 1;
BA_ "U_T6_MCA_MY2020_Rx" SG_ 1043 IndvMde5_B_Avail 1;
BA_ "U_T6_MCA_MY2020_Rx" SG_ 1043 IndvMde4_B_Avail 1;
BA_ "U_T6_MCA_MY2020_Rx" SG_ 1043 IndvMde3_B_Avail 1;
BA_ "U_T6_MCA_MY2020_Rx" SG_ 1043 IndvMde2_B_Avail 1;
BA_ "U_T6_MCA_MY2020_Rx" SG_ 1043 IndvMde1_B_Avail 1;
BA_ "U_T6_MCA_MY2020_Rx" SG_ 1043 TrailOnePdlMde_D_Ind 1;
BA_ "U_T6_MCA_MY2020_Rx" SG_ 1043 TrailOnePdlMsgTxt_D_Rq 1;
BA_ "U_CD542_MY2021_Rx" SG_ 1043 OrtaSwtchLamp_B_Rq 1;
BA_ "U_T6_MCA_MY2020_Rx" SG_ 1043 OrtaMsgTxt_D_Rq 1;
BA_ "U_T6_MCA_MY2020_Rx" SG_ 1043 OrtaMde_D_Ind 1;
BA_ "GenSigSendType" SG_ 813 TimerTripCurnt_T_Dsply 3;
BA_ "U_U55X_MY2022_Rx" SG_ 813 TimerTripCurnt_T_Dsply 1;
BA_ "U_CD542_MY2021_Rx" SG_ 813 TimerTripCurnt_T_Dsply 1;
BA_ "U_CD542_MY2021_Tx" SG_ 813 TimerTripCurnt_T_Dsply 1;
BA_ "GenSigSendType" SG_ 639 OfbChrgPrflUpdate_B_Rq 3;
BA_ "U_CD542_MY2021_Rx" SG_ 639 OfbChrgPrflUpdate_B_Rq 1;
BA_ "U_U55X_MY2022_Rx" SG_ 639 OfbChrgPrflUpdate_B_Rq 1;
BA_ "ECGUsedTxSignal" SG_ 639 OfbChrgPrflUpdate_B_Rq 1;
BA_ "U_CD542_MY2021_Tx" SG_ 639 OfbChrgPrflUpdate_B_Rq 1;
BA_ "U_U55X_MY2022_Tx" SG_ 639 OfbChrgPrflUpdate_B_Rq 1;
BA_ "GenSigSendType" SG_ 639 OfbChrgClearAll_B_Rq 3;
BA_ "ECGUsedTxSignal" SG_ 639 OfbChrgClearAll_B_Rq 1;
BA_ "U_CD542_MY2021_Tx" SG_ 639 OfbChrgClearAll_B_Rq 1;
BA_ "U_U55X_MY2022_Tx" SG_ 639 OfbChrgClearAll_B_Rq 1;
BA_ "GenSigSendType" SG_ 639 OfbChrgGoTTouch_D_Rq 3;
BA_ "ECGUsedTxSignal" SG_ 639 OfbChrgGoTTouch_D_Rq 1;
BA_ "U_CD542_MY2021_Tx" SG_ 639 OfbChrgGoTTouch_D_Rq 1;
BA_ "U_U55X_MY2022_Tx" SG_ 639 OfbChrgGoTTouch_D_Rq 1;
BA_ "ECGUsedTxSignal" SG_ 639 OfbChrgGoTPrcond_D_Rq 1;
BA_ "U_CD542_MY2021_Tx" SG_ 639 OfbChrgGoTPrcond_D_Rq 1;
BA_ "U_U55X_MY2022_Tx" SG_ 639 OfbChrgGoTPrcond_D_Rq 1;
BA_ "GenSigStartValueInteger" SG_ 639 OfbChrgGoTOn_D_Rq 2;
BA_ "GenSigSendType" SG_ 639 OfbChrgGoTOn_D_Rq 3;
BA_ "ECGUsedTxSignal" SG_ 639 OfbChrgGoTOn_D_Rq 1;
BA_ "U_CD542_MY2021_Tx" SG_ 639 OfbChrgGoTOn_D_Rq 1;
BA_ "U_U55X_MY2022_Tx" SG_ 639 OfbChrgGoTOn_D_Rq 1;
BA_ "ECGUsedTxSignal" SG_ 639 OfbChrgGoTMnte_D_Rq 1;
BA_ "U_CD542_MY2021_Tx" SG_ 639 OfbChrgGoTMnte_D_Rq 1;
BA_ "U_U55X_MY2022_Tx" SG_ 639 OfbChrgGoTMnte_D_Rq 1;
BA_ "GenSigStartValueInteger" SG_ 639 OfbChrgGoTHr_T_Rq 30;
BA_ "GenSigStartValue" SG_ 639 OfbChrgGoTHr_T_Rq 30;
BA_ "ECGUsedTxSignal" SG_ 639 OfbChrgGoTHr_T_Rq 1;
BA_ "U_CD542_MY2021_Tx" SG_ 639 OfbChrgGoTHr_T_Rq 1;
BA_ "U_U55X_MY2022_Tx" SG_ 639 OfbChrgGoTHr_T_Rq 1;
BA_ "GenSigSendType" SG_ 639 OfbChrgGoTExtHtr_D_Rq 3;
BA_ "ECGUsedTxSignal" SG_ 639 OfbChrgGoTExtHtr_D_Rq 1;
BA_ "U_CD542_MY2021_Tx" SG_ 639 OfbChrgGoTExtHtr_D_Rq 1;
BA_ "U_U55X_MY2022_Tx" SG_ 639 OfbChrgGoTExtHtr_D_Rq 1;
BA_ "GenSigSendType" SG_ 639 OfbChrgGoTElement_D_Rq 3;
BA_ "ECGUsedTxSignal" SG_ 639 OfbChrgGoTElement_D_Rq 1;
BA_ "U_CD542_MY2021_Tx" SG_ 639 OfbChrgGoTElement_D_Rq 1;
BA_ "U_U55X_MY2022_Tx" SG_ 639 OfbChrgGoTElement_D_Rq 1;
BA_ "ECGUsedTxSignal" SG_ 639 OfbChrgGoTDelete_B_Rq 1;
BA_ "U_CD542_MY2021_Tx" SG_ 639 OfbChrgGoTDelete_B_Rq 1;
BA_ "U_U55X_MY2022_Tx" SG_ 639 OfbChrgGoTDelete_B_Rq 1;
BA_ "GenSigSendType" SG_ 639 OfbChrgGoTUpdate_B_Rq 3;
BA_ "U_P702_MY2021_Rx" SG_ 639 OfbChrgGoTUpdate_B_Rq 1;
BA_ "U_CD542_MY2021_Rx" SG_ 639 OfbChrgGoTUpdate_B_Rq 1;
BA_ "U_U55X_MY2022_Rx" SG_ 639 OfbChrgGoTUpdate_B_Rq 1;
BA_ "ECGUsedTxSignal" SG_ 639 OfbChrgGoTUpdate_B_Rq 1;
BA_ "U_CD542_MY2021_Tx" SG_ 639 OfbChrgGoTUpdate_B_Rq 1;
BA_ "U_U55X_MY2022_Tx" SG_ 639 OfbChrgGoTUpdate_B_Rq 1;
BA_ "U_T6_MCA_MY2020_Rx" SG_ 419 MK_SpeedValue_Rq 1;
BA_ "U_CD542_MY2021_Rx" SG_ 419 MK_SpeedValue_Rq 1;
BA_ "U_U55X_MY2022_Rx" SG_ 419 MK_SpeedValue_Rq 1;
BA_ "U_T6_MCA_MY2020_Tx" SG_ 419 MK_SpeedValue_Rq 1;
BA_ "U_CD542_MY2021_Tx" SG_ 419 MK_SpeedValue_Rq 1;
BA_ "U_U55X_MY2022_Tx" SG_ 419 MK_SpeedValue_Rq 1;
BA_ "GenSigSendType" SG_ 419 MK_SpeedSetting_Rq 3;
BA_ "U_T6_MCA_MY2020_Rx" SG_ 419 MK_SpeedSetting_Rq 1;
BA_ "U_CD542_MY2021_Rx" SG_ 419 MK_SpeedSetting_Rq 1;
BA_ "U_U55X_MY2022_Rx" SG_ 419 MK_SpeedSetting_Rq 1;
BA_ "U_T6_MCA_MY2020_Tx" SG_ 419 MK_SpeedSetting_Rq 1;
BA_ "U_CD542_MY2021_Tx" SG_ 419 MK_SpeedSetting_Rq 1;
BA_ "U_U55X_MY2022_Tx" SG_ 419 MK_SpeedSetting_Rq 1;
BA_ "GenSigSendType" SG_ 419 MK_ResetAllUserKeys_Rq 3;
BA_ "U_T6_MCA_MY2020_Rx" SG_ 419 MK_ResetAllUserKeys_Rq 1;
BA_ "U_CD542_MY2021_Rx" SG_ 419 MK_ResetAllUserKeys_Rq 1;
BA_ "U_U55X_MY2022_Rx" SG_ 419 MK_ResetAllUserKeys_Rq 1;
BA_ "U_T6_MCA_MY2020_Tx" SG_ 419 MK_ResetAllUserKeys_Rq 1;
BA_ "U_CD542_MY2021_Tx" SG_ 419 MK_ResetAllUserKeys_Rq 1;
BA_ "U_U55X_MY2022_Tx" SG_ 419 MK_ResetAllUserKeys_Rq 1;
BA_ "GenSigSendType" SG_ 419 MK_MyKeySystemInfo_Rq 3;
BA_ "U_T6_MCA_MY2020_Rx" SG_ 419 MK_MyKeySystemInfo_Rq 1;
BA_ "U_CD542_MY2021_Rx" SG_ 419 MK_MyKeySystemInfo_Rq 1;
BA_ "U_U55X_MY2022_Rx" SG_ 419 MK_MyKeySystemInfo_Rq 1;
BA_ "U_T6_MCA_MY2020_Tx" SG_ 419 MK_MyKeySystemInfo_Rq 1;
BA_ "U_CD542_MY2021_Tx" SG_ 419 MK_MyKeySystemInfo_Rq 1;
BA_ "U_U55X_MY2022_Tx" SG_ 419 MK_MyKeySystemInfo_Rq 1;
BA_ "GenSigSendType" SG_ 419 MK_ESCRestrictConf_Rq 3;
BA_ "U_T6_MCA_MY2020_Rx" SG_ 419 MK_ESCRestrictConf_Rq 1;
BA_ "U_CD542_MY2021_Rx" SG_ 419 MK_ESCRestrictConf_Rq 1;
BA_ "U_U55X_MY2022_Rx" SG_ 419 MK_ESCRestrictConf_Rq 1;
BA_ "U_T6_MCA_MY2020_Tx" SG_ 419 MK_ESCRestrictConf_Rq 1;
BA_ "U_CD542_MY2021_Tx" SG_ 419 MK_ESCRestrictConf_Rq 1;
BA_ "U_U55X_MY2022_Tx" SG_ 419 MK_ESCRestrictConf_Rq 1;
BA_ "GenSigSendType" SG_ 419 MK_ECalRestrictConf_Rq 3;
BA_ "U_T6_MCA_MY2020_Rx" SG_ 419 MK_ECalRestrictConf_Rq 1;
BA_ "U_CD542_MY2021_Rx" SG_ 419 MK_ECalRestrictConf_Rq 1;
BA_ "U_U55X_MY2022_Rx" SG_ 419 MK_ECalRestrictConf_Rq 1;
BA_ "U_T6_MCA_MY2020_Tx" SG_ 419 MK_ECalRestrictConf_Rq 1;
BA_ "U_CD542_MY2021_Tx" SG_ 419 MK_ECalRestrictConf_Rq 1;
BA_ "U_U55X_MY2022_Tx" SG_ 419 MK_ECalRestrictConf_Rq 1;
BA_ "GenSigSendType" SG_ 419 MK_DNDRestrictConf_Rq 3;
BA_ "U_T6_MCA_MY2020_Rx" SG_ 419 MK_DNDRestrictConf_Rq 1;
BA_ "U_CD542_MY2021_Rx" SG_ 419 MK_DNDRestrictConf_Rq 1;
BA_ "U_U55X_MY2022_Rx" SG_ 419 MK_DNDRestrictConf_Rq 1;
BA_ "U_T6_MCA_MY2020_Tx" SG_ 419 MK_DNDRestrictConf_Rq 1;
BA_ "U_CD542_MY2021_Tx" SG_ 419 MK_DNDRestrictConf_Rq 1;
BA_ "U_U55X_MY2022_Tx" SG_ 419 MK_DNDRestrictConf_Rq 1;
BA_ "GenSigSendType" SG_ 419 MK_CreateMyKey_Rq 3;
BA_ "U_T6_MCA_MY2020_Rx" SG_ 419 MK_CreateMyKey_Rq 1;
BA_ "U_CD542_MY2021_Rx" SG_ 419 MK_CreateMyKey_Rq 1;
BA_ "U_U55X_MY2022_Rx" SG_ 419 MK_CreateMyKey_Rq 1;
BA_ "U_T6_MCA_MY2020_Tx" SG_ 419 MK_CreateMyKey_Rq 1;
BA_ "U_CD542_MY2021_Tx" SG_ 419 MK_CreateMyKey_Rq 1;
BA_ "U_U55X_MY2022_Tx" SG_ 419 MK_CreateMyKey_Rq 1;
BA_ "GenSigSendType" SG_ 419 MK_AudioLimitConfig_Rq 3;
BA_ "U_T6_MCA_MY2020_Rx" SG_ 419 MK_AudioLimitConfig_Rq 1;
BA_ "U_CD542_MY2021_Rx" SG_ 419 MK_AudioLimitConfig_Rq 1;
BA_ "U_U55X_MY2022_Rx" SG_ 419 MK_AudioLimitConfig_Rq 1;
BA_ "U_T6_MCA_MY2020_Tx" SG_ 419 MK_AudioLimitConfig_Rq 1;
BA_ "U_CD542_MY2021_Tx" SG_ 419 MK_AudioLimitConfig_Rq 1;
BA_ "U_U55X_MY2022_Tx" SG_ 419 MK_AudioLimitConfig_Rq 1;
BA_ "GenSigSendType" SG_ 419 MK_ACSRestrictConf_Rq 3;
BA_ "U_T6_MCA_MY2020_Rx" SG_ 419 MK_ACSRestrictConf_Rq 1;
BA_ "U_CD542_MY2021_Rx" SG_ 419 MK_ACSRestrictConf_Rq 1;
BA_ "U_U55X_MY2022_Rx" SG_ 419 MK_ACSRestrictConf_Rq 1;
BA_ "U_T6_MCA_MY2020_Tx" SG_ 419 MK_ACSRestrictConf_Rq 1;
BA_ "U_CD542_MY2021_Tx" SG_ 419 MK_ACSRestrictConf_Rq 1;
BA_ "U_U55X_MY2022_Tx" SG_ 419 MK_ACSRestrictConf_Rq 1;
BA_ "U_P702_MY2021_Rx" SG_ 542 LocationServices_3 1;
BA_ "U_T6_MCA_MY2020_Rx" SG_ 542 LocationServices_3 1;
BA_ "U_U55X_MY2022_Rx" SG_ 542 LocationServices_3 1;
BA_ "U_CD542_MY2021_Rx" SG_ 542 LocationServices_3 1;
BA_ "GenSigSendType" SG_ 554 DrvHazrdModel_D_St 3;
BA_ "U_T6_MCA_MY2020_Rx" SG_ 554 DrvHazrdModel_D_St 1;
BA_ "U_U55X_MY2022_Rx" SG_ 554 DrvHazrdModel_D_St 1;
BA_ "U_T6_MCA_MY2020_Tx" SG_ 554 DrvHazrdModel_D_St 1;
BA_ "ECGUsedTxSignal" SG_ 554 DrvHazrdModel_D_St 1;
BA_ "U_CD542_MY2021_Tx" SG_ 554 DrvHazrdModel_D_St 1;
BA_ "U_U55X_MY2022_Tx" SG_ 554 DrvHazrdModel_D_St 1;
BA_ "WakeupSignal" SG_ 554 PtWakeupActv1_B_Rq 1;
BA_ "GenSigSendType" SG_ 554 PtWakeupActv1_B_Rq 3;
BA_ "U_T6_MCA_MY2020_Rx" SG_ 554 PtWakeupActv1_B_Rq 1;
BA_ "U_CD542_MY2021_Rx" SG_ 554 PtWakeupActv1_B_Rq 1;
BA_ "U_U55X_MY2022_Rx" SG_ 554 PtWakeupActv1_B_Rq 1;
BA_ "ECGUsedTxSignal" SG_ 554 PtWakeupActv1_B_Rq 1;
BA_ "U_CD542_MY2021_Tx" SG_ 554 PtWakeupActv1_B_Rq 1;
BA_ "U_U55X_MY2022_Tx" SG_ 554 PtWakeupActv1_B_Rq 1;
BA_ "GenSigSendType" SG_ 554 DrvHazrd_D_St 3;
BA_ "U_T6_MCA_MY2020_Rx" SG_ 554 DrvHazrd_D_St 1;
BA_ "U_U55X_MY2022_Rx" SG_ 554 DrvHazrd_D_St 1;
BA_ "U_T6_MCA_MY2020_Tx" SG_ 554 DrvHazrd_D_St 1;
BA_ "ECGUsedTxSignal" SG_ 554 DrvHazrd_D_St 1;
BA_ "U_CD542_MY2021_Tx" SG_ 554 DrvHazrd_D_St 1;
BA_ "U_U55X_MY2022_Tx" SG_ 554 DrvHazrd_D_St 1;
BA_ "GenSigSendType" SG_ 494 HEC_TUPresetArea_Rq 3;
BA_ "U_T6_MCA_MY2020_Rx" SG_ 494 HEC_TUPresetArea_Rq 1;
BA_ "U_U55X_MY2022_Rx" SG_ 494 HEC_TUPresetArea_Rq 1;
BA_ "U_T6_MCA_MY2020_Tx" SG_ 494 HEC_TUPresetArea_Rq 1;
BA_ "U_U55X_MY2022_Tx" SG_ 494 HEC_TUPresetArea_Rq 1;
BA_ "GenSigSendType" SG_ 494 Mc_SetCurrPreset2_Rq 3;
BA_ "U_T6_MCA_MY2020_Rx" SG_ 494 Mc_SetCurrPreset2_Rq 1;
BA_ "U_U55X_MY2022_Rx" SG_ 494 Mc_SetCurrPreset2_Rq 1;
BA_ "U_T6_MCA_MY2020_Tx" SG_ 494 Mc_SetCurrPreset2_Rq 1;
BA_ "U_U55X_MY2022_Tx" SG_ 494 Mc_SetCurrPreset2_Rq 1;
BA_ "U_T6_MCA_MY2020_Rx" SG_ 494 HEC_TUNbrOfPresets_Rq 1;
BA_ "U_U55X_MY2022_Rx" SG_ 494 HEC_TUNbrOfPresets_Rq 1;
BA_ "U_T6_MCA_MY2020_Tx" SG_ 494 HEC_TUNbrOfPresets_Rq 1;
BA_ "U_U55X_MY2022_Tx" SG_ 494 HEC_TUNbrOfPresets_Rq 1;
BA_ "GenSigSendType" SG_ 494 HEC_SetCurrTUBand_Rq 3;
BA_ "U_T6_MCA_MY2020_Rx" SG_ 494 HEC_SetCurrTUBand_Rq 1;
BA_ "U_U55X_MY2022_Rx" SG_ 494 HEC_SetCurrTUBand_Rq 1;
BA_ "U_T6_MCA_MY2020_Tx" SG_ 494 HEC_SetCurrTUBand_Rq 1;
BA_ "U_U55X_MY2022_Tx" SG_ 494 HEC_SetCurrTUBand_Rq 1;
BA_ "U_T6_MCA_MY2020_Rx" SG_ 494 HEC_TUStartIndex2_Rq 1;
BA_ "U_U55X_MY2022_Rx" SG_ 494 HEC_TUStartIndex2_Rq 1;
BA_ "U_T6_MCA_MY2020_Tx" SG_ 494 HEC_TUStartIndex2_Rq 1;
BA_ "U_U55X_MY2022_Tx" SG_ 494 HEC_TUStartIndex2_Rq 1;
BA_ "U_T6_MCA_MY2020_Rx" SG_ 714 SDARS_MC_WORD_Rx 1;
BA_ "U_CD542_MY2021_Rx" SG_ 714 SDARS_MC_WORD_Rx 1;
BA_ "U_T6_MCA_MY2020_Tx" SG_ 714 SDARS_MC_WORD_Rx 1;
BA_ "U_U55X_MY2022_Tx" SG_ 714 SDARS_MC_WORD_Rx 1;
BA_ "U_T6_MCA_MY2020_Rx" SG_ 498 HEC_ARReqstrPriority_Rq 1;
BA_ "U_U55X_MY2022_Rx" SG_ 498 HEC_ARReqstrPriority_Rq 1;
BA_ "U_T6_MCA_MY2020_Tx" SG_ 498 HEC_ARReqstrPriority_Rq 1;
BA_ "U_CD542_MY2021_Tx" SG_ 498 HEC_ARReqstrPriority_Rq 1;
BA_ "U_U55X_MY2022_Tx" SG_ 498 HEC_ARReqstrPriority_Rq 1;
BA_ "GenSigSendType" SG_ 498 HEC_AROperationType_Rq 3;
BA_ "U_T6_MCA_MY2020_Rx" SG_ 498 HEC_AROperationType_Rq 1;
BA_ "U_U55X_MY2022_Rx" SG_ 498 HEC_AROperationType_Rq 1;
BA_ "U_T6_MCA_MY2020_Tx" SG_ 498 HEC_AROperationType_Rq 1;
BA_ "U_CD542_MY2021_Tx" SG_ 498 HEC_AROperationType_Rq 1;
BA_ "U_U55X_MY2022_Tx" SG_ 498 HEC_AROperationType_Rq 1;
BA_ "U_T6_MCA_MY2020_Rx" SG_ 498 HEC_ARReqstrSystem_Rq 1;
BA_ "U_U55X_MY2022_Rx" SG_ 498 HEC_ARReqstrSystem_Rq 1;
BA_ "U_T6_MCA_MY2020_Tx" SG_ 498 HEC_ARReqstrSystem_Rq 1;
BA_ "U_CD542_MY2021_Tx" SG_ 498 HEC_ARReqstrSystem_Rq 1;
BA_ "U_U55X_MY2022_Tx" SG_ 498 HEC_ARReqstrSystem_Rq 1;
BA_ "U_T6_MCA_MY2020_Rx" SG_ 498 HEC_ARAudioSource_Rq 1;
BA_ "U_U55X_MY2022_Rx" SG_ 498 HEC_ARAudioSource_Rq 1;
BA_ "U_T6_MCA_MY2020_Tx" SG_ 498 HEC_ARAudioSource_Rq 1;
BA_ "U_CD542_MY2021_Tx" SG_ 498 HEC_ARAudioSource_Rq 1;
BA_ "U_U55X_MY2022_Tx" SG_ 498 HEC_ARAudioSource_Rq 1;
BA_ "U_T6_MCA_MY2020_Rx" SG_ 644 VehOnSrc_D_Stat_UB 1;
BA_ "U_U55X_MY2022_Rx" SG_ 644 VehOnSrc_D_Stat_UB 1;
BA_ "U_CD542_MY2021_Rx" SG_ 644 VehOnSrc_D_Stat_UB 1;
BA_ "U_T6_MCA_MY2020_Rx" SG_ 644 VehOnSrc_D_Stat 1;
BA_ "U_U55X_MY2022_Rx" SG_ 644 VehOnSrc_D_Stat 1;
BA_ "U_CD542_MY2021_Rx" SG_ 644 VehOnSrc_D_Stat 1;
BA_ "U_T6_MCA_MY2020_Rx" SG_ 643 StrtInGearMsgTxt_D_Rq_UB 1;
BA_ "GenSigSendType" SG_ 643 StrtInGearMsgTxt_D_Rq 3;
BA_ "U_T6_MCA_MY2020_Rx" SG_ 643 StrtInGearMsgTxt_D_Rq 1;
BA_ "U_T6_MCA_MY2020_Rx" SG_ 643 StabBarCnnct_D_Stat_UB 1;
BA_ "U_U55X_MY2022_Rx" SG_ 643 StabBarCnnct_D_Stat_UB 1;
BA_ "GenSigSendType" SG_ 643 StabBarCnnct_D_Stat 3;
BA_ "U_T6_MCA_MY2020_Rx" SG_ 643 StabBarCnnct_D_Stat 1;
BA_ "U_U55X_MY2022_Rx" SG_ 643 StabBarCnnct_D_Stat 1;
BA_ "U_T6_MCA_MY2020_Rx" SG_ 643 FstChrgCmplt_T_Est 1;
BA_ "U_CD542_MY2021_Rx" SG_ 643 FstChrgCmplt_T_Est 1;
BA_ "U_U55X_MY2022_Rx" SG_ 643 FstChrgCmplt_T_Est 1;
BA_ "U_T6_MCA_MY2020_Rx" SG_ 643 GearPos_D_Trg_UB 1;
BA_ "U_CD542_MY2021_Rx" SG_ 643 GearPos_D_Trg_UB 1;
BA_ "U_U55X_MY2022_Rx" SG_ 643 GearPos_D_Trg_UB 1;
BA_ "GenSigStartValueInteger" SG_ 643 GearPos_D_Trg 15;
BA_ "ContentDependant" SG_ 643 GearPos_D_Trg 1;
BA_ "GenSigStartValue" SG_ 643 GearPos_D_Trg 15;
BA_ "GenSigSendType" SG_ 643 GearPos_D_Trg 3;
BA_ "U_T6_MCA_MY2020_Rx" SG_ 643 GearPos_D_Trg 1;
BA_ "U_CD542_MY2021_Rx" SG_ 643 GearPos_D_Trg 1;
BA_ "U_U55X_MY2022_Rx" SG_ 643 GearPos_D_Trg 1;
BA_ "GenSigSendType" SG_ 643 PwTgateStepMsgTxt_B_Rq 3;
BA_ "U_T6_MCA_MY2020_Rx" SG_ 643 PwTgateStepMsgTxt_B_Rq 1;
BA_ "U_U55X_MY2022_Rx" SG_ 643 PwTgateStepMsgTxt_B_Rq 1;
BA_ "U_T6_MCA_MY2020_Rx" SG_ 643 PwTgateStepMsgTxt_B_Rq_UB 1;
BA_ "U_U55X_MY2022_Rx" SG_ 643 PwTgateStepMsgTxt_B_Rq_UB 1;
BA_ "U_T6_MCA_MY2020_Rx" SG_ 643 PwTgateMsgTxt_B_Rq_UB 1;
BA_ "U_U55X_MY2022_Rx" SG_ 643 PwTgateMsgTxt_B_Rq_UB 1;
BA_ "U_T6_MCA_MY2020_Rx" SG_ 643 PwTgateLamp_B_Rq_UB 1;
BA_ "U_U55X_MY2022_Rx" SG_ 643 PwTgateLamp_B_Rq_UB 1;
BA_ "GenSigSendType" SG_ 643 PwTgateMsgTxt_B_Rq 3;
BA_ "U_T6_MCA_MY2020_Rx" SG_ 643 PwTgateMsgTxt_B_Rq 1;
BA_ "U_U55X_MY2022_Rx" SG_ 643 PwTgateMsgTxt_B_Rq 1;
BA_ "GenSigSendType" SG_ 643 PwTgateLamp_B_Rq 3;
BA_ "U_T6_MCA_MY2020_Rx" SG_ 643 PwTgateLamp_B_Rq 1;
BA_ "U_U55X_MY2022_Rx" SG_ 643 PwTgateLamp_B_Rq 1;
BA_ "U_T6_MCA_MY2020_Rx" SG_ 643 PwRnngBoardSwtch_D_Stat_UB 1;
BA_ "U_U55X_MY2022_Rx" SG_ 643 PwRnngBoardSwtch_D_Stat_UB 1;
BA_ "U_CD542_MY2021_Rx" SG_ 643 PwRnngBoardSwtch_D_Stat_UB 1;
BA_ "U_T6_MCA_MY2020_Rx" SG_ 643 PwRnngBoardT_D_Stat_UB 1;
BA_ "U_U55X_MY2022_Rx" SG_ 643 PwRnngBoardT_D_Stat_UB 1;
BA_ "U_CD542_MY2021_Rx" SG_ 643 PwRnngBoardT_D_Stat_UB 1;
BA_ "GenSigSendType" SG_ 643 PwRnngBoardT_D_Stat 3;
BA_ "U_T6_MCA_MY2020_Rx" SG_ 643 PwRnngBoardT_D_Stat 1;
BA_ "U_U55X_MY2022_Rx" SG_ 643 PwRnngBoardT_D_Stat 1;
BA_ "U_CD542_MY2021_Rx" SG_ 643 PwRnngBoardT_D_Stat 1;
BA_ "GenSigSendType" SG_ 643 PwRnngBoardSwtch_D_Stat 3;
BA_ "U_T6_MCA_MY2020_Rx" SG_ 643 PwRnngBoardSwtch_D_Stat 1;
BA_ "U_CD542_MY2021_Rx" SG_ 643 PwRnngBoardSwtch_D_Stat 1;
BA_ "U_U55X_MY2022_Rx" SG_ 643 PwRnngBoardSwtch_D_Stat 1;
BA_ "U_T6_MCA_MY2020_Rx" SG_ 643 OnePdlDrvLamp_B_Rq_UB 1;
BA_ "U_CD542_MY2021_Rx" SG_ 643 OnePdlDrv_D_Dsply_UB 1;
BA_ "U_U55X_MY2022_Rx" SG_ 643 OnePdlDrv_D_Dsply_UB 1;
BA_ "U_T6_MCA_MY2020_Rx" SG_ 643 OnePdlDrv_D_Dsply_UB 1;
BA_ "GenSigSendType" SG_ 643 OnePdlDrvLamp_B_Rq 3;
BA_ "U_T6_MCA_MY2020_Rx" SG_ 643 OnePdlDrvLamp_B_Rq 1;
BA_ "GenSigSendType" SG_ 643 OnePdlDrv_D_Dsply 3;
BA_ "U_CD542_MY2021_Rx" SG_ 643 OnePdlDrv_D_Dsply 1;
BA_ "U_U55X_MY2022_Rx" SG_ 643 OnePdlDrv_D_Dsply 1;
BA_ "U_T6_MCA_MY2020_Rx" SG_ 643 OnePdlDrv_D_Dsply 1;
BA_ "GenSigSendType" SG_ 643 SeatSlprPosMsgTxt_B_Rq 3;
BA_ "U_T6_MCA_MY2020_Rx" SG_ 643 DrPrsntRearPsngr_D_Stat_UB 1;
BA_ "U_T6_MCA_MY2020_Rx" SG_ 643 DrPsngrMsgTxt_B_Rq_UB 1;
BA_ "GenSigSendType" SG_ 643 DrPsngrMsgTxt_B_Rq 3;
BA_ "U_T6_MCA_MY2020_Rx" SG_ 643 DrPsngrMsgTxt_B_Rq 1;
BA_ "WakeupSignal" SG_ 643 DrPrsntRearPsngr_D_Stat 1;
BA_ "GenSigSendType" SG_ 643 DrPrsntRearPsngr_D_Stat 3;
BA_ "U_T6_MCA_MY2020_Rx" SG_ 643 DrPrsntRearPsngr_D_Stat 1;
BA_ "WakeupSignal" SG_ 643 DrPrsntPsngr_D_Stat 1;
BA_ "GenSigSendType" SG_ 643 DrPrsntPsngr_D_Stat 3;
BA_ "U_T6_MCA_MY2020_Rx" SG_ 643 DrPrsntRearDrv_D_Stat_UB 1;
BA_ "U_T6_MCA_MY2020_Rx" SG_ 643 DrDrvMsgTxt_B_Rq_UB 1;
BA_ "U_T6_MCA_MY2020_Rx" SG_ 643 DrPrsntDrv_D_Stat_UB 1;
BA_ "WakeupSignal" SG_ 643 DrPrsntDrv_D_Stat 1;
BA_ "GenSigSendType" SG_ 643 DrPrsntDrv_D_Stat 3;
BA_ "U_T6_MCA_MY2020_Rx" SG_ 643 DrPrsntDrv_D_Stat 1;
BA_ "WakeupSignal" SG_ 643 DrPrsntRearDrv_D_Stat 1;
BA_ "GenSigSendType" SG_ 643 DrPrsntRearDrv_D_Stat 3;
BA_ "U_T6_MCA_MY2020_Rx" SG_ 643 DrPrsntRearDrv_D_Stat 1;
BA_ "GenSigSendType" SG_ 643 DrDrvMsgTxt_B_Rq 3;
BA_ "U_T6_MCA_MY2020_Rx" SG_ 643 DrDrvMsgTxt_B_Rq 1;
BA_ "U_T6_MCA_MY2020_Rx" SG_ 643 FstChrgCmplt_T_Est_UB 1;
BA_ "U_CD542_MY2021_Rx" SG_ 643 FstChrgCmplt_T_Est_UB 1;
BA_ "U_U55X_MY2022_Rx" SG_ 643 FstChrgCmplt_T_Est_UB 1;
BA_ "U_T6_MCA_MY2020_Rx" SG_ 643 TrunkFrontOpen_D_Stat_UB 1;
BA_ "U_CD542_MY2021_Rx" SG_ 643 TrunkFrontOpen_D_Stat_UB 1;
BA_ "U_U55X_MY2022_Rx" SG_ 643 TrunkFrontOpen_D_Stat_UB 1;
BA_ "WakeupSignal" SG_ 643 TrunkFrontOpen_D_Stat 1;
BA_ "GenSigStartValue" SG_ 643 TrunkFrontOpen_D_Stat 2;
BA_ "GenSigSendType" SG_ 643 TrunkFrontOpen_D_Stat 3;
BA_ "U_T6_MCA_MY2020_Rx" SG_ 643 TrunkFrontOpen_D_Stat 1;
BA_ "U_CD542_MY2021_Rx" SG_ 643 TrunkFrontOpen_D_Stat 1;
BA_ "U_U55X_MY2022_Rx" SG_ 643 TrunkFrontOpen_D_Stat 1;
BA_ "U_U55X_MY2022_Rx" SG_ 145 MFD_Year 1;
BA_ "U_T6_MCA_MY2020_Rx" SG_ 145 MFD_Year 1;
BA_ "U_T6_MCA_MY2020_Tx" SG_ 145 MFD_Year 1;
BA_ "U_CD542_MY2021_Tx" SG_ 145 MFD_Year 1;
BA_ "U_U55X_MY2022_Tx" SG_ 145 MFD_Year 1;
BA_ "GenSigSendType" SG_ 145 MFD_Second 3;
BA_ "U_U55X_MY2022_Rx" SG_ 145 MFD_Second 1;
BA_ "U_T6_MCA_MY2020_Rx" SG_ 145 MFD_Second 1;
BA_ "U_T6_MCA_MY2020_Tx" SG_ 145 MFD_Second 1;
BA_ "U_CD542_MY2021_Tx" SG_ 145 MFD_Second 1;
BA_ "U_U55X_MY2022_Tx" SG_ 145 MFD_Second 1;
BA_ "U_U55X_MY2022_Rx" SG_ 145 MFD_Month 1;
BA_ "U_T6_MCA_MY2020_Rx" SG_ 145 MFD_Month 1;
BA_ "U_T6_MCA_MY2020_Tx" SG_ 145 MFD_Month 1;
BA_ "U_CD542_MY2021_Tx" SG_ 145 MFD_Month 1;
BA_ "U_U55X_MY2022_Tx" SG_ 145 MFD_Month 1;
BA_ "U_U55X_MY2022_Rx" SG_ 145 MFD_Minute 1;
BA_ "U_T6_MCA_MY2020_Rx" SG_ 145 MFD_Minute 1;
BA_ "U_T6_MCA_MY2020_Tx" SG_ 145 MFD_Minute 1;
BA_ "U_CD542_MY2021_Tx" SG_ 145 MFD_Minute 1;
BA_ "U_U55X_MY2022_Tx" SG_ 145 MFD_Minute 1;
BA_ "U_U55X_MY2022_Rx" SG_ 145 MFD_Hour 1;
BA_ "U_T6_MCA_MY2020_Rx" SG_ 145 MFD_Hour 1;
BA_ "U_T6_MCA_MY2020_Tx" SG_ 145 MFD_Hour 1;
BA_ "U_CD542_MY2021_Tx" SG_ 145 MFD_Hour 1;
BA_ "U_U55X_MY2022_Tx" SG_ 145 MFD_Hour 1;
BA_ "U_U55X_MY2022_Rx" SG_ 145 MFD_Day 1;
BA_ "U_T6_MCA_MY2020_Rx" SG_ 145 MFD_Day 1;
BA_ "U_T6_MCA_MY2020_Tx" SG_ 145 MFD_Day 1;
BA_ "U_CD542_MY2021_Tx" SG_ 145 MFD_Day 1;
BA_ "U_U55X_MY2022_Tx" SG_ 145 MFD_Day 1;
VAL_ 884 UltraFreshCabn_D_Stat 7 "NotUsed_2" 6 "NotUsed_1" 5 "NotSupported" 4 "Interrupted" 3 "Complete" 2 "Active" 1 "Inactive" 0 "Null" ;
VAL_ 884 PmSnsCabn_D_Stat 7 "NotUsed_1" 6 "IntermittentInhibit" 5 "NoIssue" 4 "BlankField" 3 "ReplaceSensor" 2 "CleanSensor" 1 "Unsupported" 0 "Initializing" ;
VAL_ 884 PmCabn_Conc_Actl 511 "Faulty" 510 "NoDataExists" ;
VAL_ 884 PmCabn20Mnte_Conc_Actl 511 "Faulty" 510 "NoDataExists" ;
VAL_ 884 PmCabn18Mnte_Conc_Actl 511 "Faulty" 510 "NoDataExists" ;
VAL_ 884 PmCabn16Mnte_Conc_Actl 511 "Faulty" 510 "NoDataExists" ;
VAL_ 884 PmCabn14Mnte_Conc_Actl 511 "Faulty" 510 "NoDataExists" ;
VAL_ 884 PmCabn12Mnte_Conc_Actl 511 "Faulty" 510 "NoDataExists" ;
VAL_ 883 PmCabn10Mnte_Conc_Actl 511 "Faulty" 510 "NoDataExists" ;
VAL_ 883 PmCabn08Mnte_Conc_Actl 511 "Faulty" 510 "NoDataExists" ;
VAL_ 883 PmCabn06Mnte_Conc_Actl 511 "Faulty" 510 "NoDataExists" ;
VAL_ 883 PmCabn04Mnte_Conc_Actl 511 "Faulty" 510 "NoDataExists" ;
VAL_ 883 PmCabn02Mnte_Conc_Actl 511 "Faulty" 510 "NoDataExists" ;
VAL_ 1090 VehElRnge_L_Dsply 4094 "NoDataExists" 4095 "Fault" ;
VAL_ 1090 Mtr2State_D_ActlMntr 7 "Faulty" 6 "NoDataExists" 5 "NotUsed_1" 4 "ReadinessState" 3 "DeactivationState" 2 "PowerGeneration" 1 "PowerConsumption" 0 "Null" ;
VAL_ 1090 Inv1Ain_I_ActlMntr 32767 "Faulty" 32766 "NoDataExists" ;
VAL_ 1090 HybVehMde_D_ActlMntr 7 "Faulty" 6 "NoDataExists" 5 "NotUsed_2" 4 "NotUsed_1" 3 "Fuel" 2 "HybridElectric" 1 "AllElectric" 0 "Null" ;
VAL_ 1090 ChrgStat_D_ActlMntr 7 "Faulty" 6 "NoDataExists" 5 "NotUsed" 4 "ChargingCompleted" 3 "NotCharging" 2 "ChargingInDrivingState" 1 "ChargingInParkingState" 0 "Null" ;
VAL_ 677 SeatFnPsgr_D_Rq3 7 "CushionMassage" 6 "LumbarMassage" 5 "UpperBolster" 4 "LowerBolster" 3 "UpperLumbar" 2 "MiddleLumbar" 1 "LowerLumbar" 0 "Null" ;
VAL_ 677 SeatFnDrv_D_Rq3 7 "CushionMassage" 6 "LumbarMassage" 5 "UpperBolster" 4 "LowerBolster" 3 "UpperLumbar" 2 "MiddleLumbar" 1 "LowerLumbar" 0 "Null" ;
VAL_ 677 SeatMasgPsngrRr_D_Rq2 15 "NotUsed_10" 14 "NotUsed_9" 13 "NotUsed_8" 12 "NotUsed_7" 11 "NotUsed_6" 10 "NotUsed_5" 9 "NotUsed_4" 8 "NotUsed_3" 7 "NotUsed_2" 6 "NotUsed_1" 5 "Pattern5" 4 "Pattern4" 3 "Pattern3" 2 "Pattern2" 1 "Pattern1" 0 "Null" ;
VAL_ 677 SeatMasgDrvRr_D_Rq2 15 "NotUsed_10" 14 "NotUsed_9" 13 "NotUsed_8" 12 "NotUsed_7" 11 "NotUsed_6" 10 "NotUsed_5" 9 "NotUsed_4" 8 "NotUsed_3" 7 "NotUsed_2" 6 "NotUsed_1" 5 "Pattern5" 4 "Pattern4" 3 "Pattern3" 2 "Pattern2" 1 "Pattern1" 0 "Null" ;
VAL_ 677 SeatFnChngPsgr2_D_Rq3 15 "Faulty" 14 "NotUsed9" 13 "NotUsed8" 12 "NotUsed7" 11 "NotUsed6" 10 "High_2" 9 "Med_2" 8 "Low_2" 7 "Off_2" 6 "High" 5 "Low" 4 "Off" 3 "Decrease" 2 "Increase" 1 "NotUsed1" 0 "Inactive" ;
VAL_ 677 SeatFnChngDrv2_D_Rq3 15 "Faulty" 14 "NotUsed9" 13 "NotUsed8" 12 "NotUsed7" 11 "NotUsed6" 10 "High_2" 9 "Med_2" 8 "Low_2" 7 "Off_2" 6 "High" 5 "Low" 4 "Off" 3 "Decrease" 2 "Increase" 1 "NotUsed1" 0 "Inactive" ;
VAL_ 1238 TjaLaneBias_D_Stat 7 "NotUsed" 6 "ElBiasRight" 5 "ElBiasLeft" 4 "SystemBiasRight" 3 "SystemBiasLeft" 2 "ManualBiasRight" 1 "ManualBiasLeft" 0 "NoBias" ;
VAL_ 1238 IaccVAdjReas_D_Dsply 15 "NotUsed_21" 11 "NotUsed_1" 10 "SpeedSign" 9 "LeftRamp" 8 "RightRamp" 7 "Roundabout_CCW" 6 "Roundabout_CW" 5 "LeftCurve" 4 "RightCurve" 3 "LeftTurnIntersection" 2 "RightTurnIntersection" 1 "RoadGeometryUnavailable" 0 "NoDisplay" ;
VAL_ 1041 ElCmprPerfErr_D_Falt 3 "NotUsed" 2 "Pass" 1 "Fail" 0 "Not_Diagnose_Yet" ;
VAL_ 1041 ElCmprInnrErr_D_Falt 3 "NotUsed" 2 "Pass" 1 "Fail" 0 "Not_Diagnose_Yet" ;
VAL_ 1041 ElCmprLostComm_D_Falt 3 "NotUsed" 2 "Pass" 1 "Fail" 0 "Not_Diagnose_Yet" ;
VAL_ 1041 ElCmprOverLoad_D_Falt 3 "NotUsed" 2 "Pass" 1 "Fail" 0 "Not_Diagnose_Yet" ;
VAL_ 1041 ElCmprOverTe_D_Falt 3 "NotUsed" 2 "Pass" 1 "Fail" 0 "Not_Diagnose_Yet" ;
VAL_ 1041 ElCmprBattURng_D_Falt 3 "NotUsed" 2 "Pass" 1 "Fail" 0 "Not_Diagnose_Yet" ;
VAL_ 1041 ElCmprBattSysU_D_Falt 3 "NotUsed" 2 "Pass" 1 "Fail" 0 "Not_Diagnose_Yet" ;
VAL_ 1041 ElCmprSysU_D_Falt 3 "NotUsed" 2 "Pass" 1 "Fail" 0 "Not_Diagnose_Yet" ;
VAL_ 1041 ElCmprUHi_D_Stat 3 "Overvoltage" 2 "Undervoltage" 1 "InRange" 0 "Undetermined" ;
VAL_ 1041 ElCmprOverTe_D_Stat 3 "OverTempStop" 2 "OverTempWarning" 1 "Normal" 0 "Undefined" ;
VAL_ 1041 ElCmpr_N_Actl 255 "Invalid" ;
VAL_ 1041 ElCmpr_Pw_Actl 255 "Invalid" ;
VAL_ 1041 ElCmpr_D_Stat 7 "Signal_Invalid" 6 "Comp_Off_ActlSpd_Abnormal" 5 "Comp_Off_TrgtSpd_OutRange" 4 "Comp_Shutdown" 3 "Comp_Stopped_Self_Protect" 2 "Comp_Degraded" 1 "Comp_On" 0 "Comp_Off" ;
VAL_ 557 AudioToneTouchY_D_Stat 255 "Value254" 2 "Value1_up_to_0xFE_Value253" 1 "Value0" 0 "Null" ;
VAL_ 557 AudioToneTouchX_D_Stat 255 "Value254" 2 "Value1_up_to_0xFE_Value253" 1 "Value0" 0 "Null" ;
VAL_ 557 AudioToneTouch_D_Stat 3 "NotUsed" 2 "Enabled" 1 "Disabled" 0 "Null" ;
VAL_ 1236 ApaSlotRight3_D_Stat 7 "NotUsed_3" 6 "NotUsed_2" 5 "NotUsed_1" 4 "IPeReady" 3 "IPeFound" 2 "IPaReady" 1 "IPaFound" 0 "None" ;
VAL_ 1236 ApaSlotRight3_B_Altr 1 "Available" 0 "NotAvailable" ;
VAL_ 1236 ApaSlotRight2_D_Stat 7 "NotUsed_3" 6 "NotUsed_2" 5 "NotUsed_1" 4 "IPeReady" 3 "IPeFound" 2 "IPaReady" 1 "IPaFound" 0 "None" ;
VAL_ 1236 ApaSlotRight2_B_Altr 1 "Available" 0 "NotAvailable" ;
VAL_ 1236 ApaSlotRight1_D_Stat 7 "NotUsed_3" 6 "NotUsed_2" 5 "NotUsed_1" 4 "IPeReady" 3 "IPeFound" 2 "IPaReady" 1 "IPaFound" 0 "None" ;
VAL_ 1236 ApaSlotRight1_B_Altr 1 "Available" 0 "NotAvailable" ;
VAL_ 1236 ApaSlotRear_D_Stat 1 "True" 0 "False" ;
VAL_ 1235 ApaSlotFront_D_Stat 1 "True" 0 "False" ;
VAL_ 1235 ApaSlotLeft3_D_Stat 7 "NotUsed_3" 6 "NotUsed_2" 5 "NotUsed_1" 4 "IPeReady" 3 "IPeFound" 2 "IPaReady" 1 "IPaFound" 0 "None" ;
VAL_ 1235 ApaSlotLeft3_B_Altr 1 "Available" 0 "NotAvailable" ;
VAL_ 1235 ApaSlotLeft2_D_Stat 7 "NotUsed_3" 6 "NotUsed_2" 5 "NotUsed_1" 4 "IPeReady" 3 "IPeFound" 2 "IPaReady" 1 "IPaFound" 0 "None" ;
VAL_ 1235 ApaSlotLeft2_B_Altr 1 "Unavailable" 0 "Available" ;
VAL_ 1235 ApaSlotLeft1_D_Stat 7 "NotUsed_3" 6 "NotUsed_2" 5 "NotUsed_1" 4 "IPeReady" 3 "IPeFound" 2 "IPaReady" 1 "IPaFound" 0 "None" ;
VAL_ 1235 ApaSlotLeft1_B_Altr 1 "Unavailable" 0 "Available" ;
VAL_ 1234 RmtCtlSnsBlckg_B_Stat 1 "Yes" 0 "No" ;
VAL_ 1234 RmtCtlConfgSrc_D_Stat 7 "NotUsed_2" 6 "NotUsed_1" 5 "BPO" 4 "ApaHmi" 3 "FAP_Handover" 2 "User" 1 "None" 0 "NotDetermined" ;
VAL_ 1234 RmtCtlTrjctry_D_Avail 3 "NotUsed" 2 "Available" 1 "NotAvailable" 0 "Null" ;
VAL_ 1234 RmtCtlSns_D_Err 1 "Yes" 0 "No" ;
VAL_ 1234 RmtCtlPathPlan_D_Stat 7 "NotUsed_3" 6 "NotUsed_2" 5 "NotUsed_1" 4 "FinishedMovesExceeded" 3 "FinishedDistanceExceeded" 2 "Finished" 1 "Ongoing" 0 "None" ;
VAL_ 1234 RmtCtlPathPlan_B_Err 1 "Yes" 0 "No" ;
VAL_ 1234 RmtCtlAdas_D_Stat 7 "Paused" 6 "Abort" 5 "ManeuverFinished" 4 "EndPositionReached" 3 "Backward" 2 "Forward" 1 "ManeuverBegin" 0 "Inactive" ;
VAL_ 1234 RmtCtlAdas_B_Err 1 "Yes" 0 "No" ;
VAL_ 976 VehLong2_A_Actl_UB 1 "Fresh_data" 0 "Unchanged_data" ;
VAL_ 976 VehLong2_A_Actl 8191 "Faulty" 8190 "NoDataExists" ;
VAL_ 898 SecondRowBcklPsngrMid 3 "Unknown" 2 "Unbelted" 1 "Belted" 0 "Faulty" ;
VAL_ 898 SecondRowBckleDrvMid 3 "Unknown" 2 "Unbelted" 1 "Belted" 0 "Faulty" ;
VAL_ 898 FourthRowBucklePsngr 3 "Unknown" 2 "Unbelted" 1 "Belted" 0 "Faulty" ;
VAL_ 898 FourthRowBuckleMid 3 "Unknown" 2 "Unbelted" 1 "Belted" 0 "Faulty" ;
VAL_ 898 FourthRowBuckleDriver 3 "Unknown" 2 "Unbelted" 1 "Belted" 0 "Faulty" ;
VAL_ 898 Row3PsngrPrsnc_D_Actl 3 "Unknown" 2 "Empty" 1 "Occupied" 0 "Fault" ;
VAL_ 898 Row3MidPrsnc_D_Actl 3 "Unknown" 2 "Empty" 1 "Occupied" 0 "Fault" ;
VAL_ 898 Row3DrvPrsnc_D_Actl 3 "Unknown" 2 "Empty" 1 "Occupied" 0 "Fault" ;
VAL_ 898 Row2PsngrPrsnc_D_Actl 3 "Unknown" 2 "Empty" 1 "Occupied" 0 "Fault" ;
VAL_ 898 Row2MidPrsnc_D_Actl 3 "Unknown" 2 "Empty" 1 "Occupied" 0 "Fault" ;
VAL_ 898 Row2DrvPrsnc_D_Actl 3 "Unknown" 2 "Empty" 1 "Occupied" 0 "Fault" ;
VAL_ 925 VehElEffTrip_No_Dsply 127 "Faulty" 126 "NoDataExists" ;
VAL_ 925 TripSumDrvE_Pc_Dsply 1023 "Faulty" 1022 "NoDataExists" ;
VAL_ 925 TripExtFctrE_Pc_Dsply 1023 "Faulty" 1022 "NoDataExists" ;
VAL_ 925 TripClimE_Pc_Dsply 1023 "Faulty" 1022 "NoDataExists" ;
VAL_ 925 TripBattULoE_Pc_Dsply 1023 "Faulty" 1022 "NoDataExists" ;
VAL_ 473 NAV_StorePreset2_Rq 31 "Reserved" 30 "Preset30" 29 "Preset29" 28 "Preset28" 27 "Preset27" 26 "Preset26" 25 "Preset25" 24 "Preset24" 23 "Preset23" 22 "Preset22" 21 "Preset21" 20 "Preset20" 19 "Preset19" 18 "Preset18" 17 "Preset17" 16 "Preset16" 15 "Preset15" 14 "Preset14" 13 "Preset13" 12 "Preset12" 11 "Preset11" 10 "Preset10" 9 "Preset9" 8 "Preset8" 7 "Preset7" 6 "Preset6" 5 "Preset5" 4 "Preset4" 3 "Preset3" 2 "Preset2" 1 "Preset1" 0 "Inactive" ;
VAL_ 473 NAV_SetAFMode_Rq 0 "Inactive" 1 "AfOn" 2 "AfOff" 3 "Auto" ;
VAL_ 473 NAV_StorePreset_Rq 10 "Preset10" 9 "Preset9" 8 "Preset8" 7 "Preset7" 0 "Inactive" 1 "Preset1" 2 "Preset2" 3 "Preset3" 4 "Preset4" 5 "Preset5" 6 "Preset6" ;
VAL_ 473 HMI_StorePreset2_Rq 31 "Reserved" 30 "Preset30" 29 "Preset29" 28 "Preset28" 27 "Preset27" 26 "Preset26" 25 "Preset25" 24 "Preset24" 23 "Preset23" 22 "Preset22" 21 "Preset21" 20 "Preset20" 19 "Preset19" 18 "Preset18" 17 "Preset17" 16 "Preset16" 15 "Preset15" 14 "Preset14" 13 "Preset13" 12 "Preset12" 11 "Preset11" 10 "Preset10" 9 "Preset9" 8 "Preset8" 7 "Preset7" 6 "Preset6" 5 "Preset5" 4 "Preset4" 3 "Preset3" 2 "Preset2" 1 "Preset1" 0 "Inactive" ;
VAL_ 473 NAV_SetTUServiceLink_Rq 3 "reserved" 2 "Inactive" 1 "Active" 0 "Invalid" ;
VAL_ 473 NAV_SetTAMode_Rq 0 "Inactive" 1 "TaLocalOn" 2 "TaDistantOn" 3 "TaOff" ;
VAL_ 473 NAV_SetReg_Rq 2 "On" 1 "Off" 0 "Inactive" ;
VAL_ 473 NAV_SelectPTYCodeSet_Rq 0 "Inactive" 1 "SetCode" ;
VAL_ 473 NAV_CDSetShuffle_Rq 0 "Inactive" 1 "On" 2 "Off" 3 "OnFolder" ;
VAL_ 473 NAV_CDSetRepeat_Rq 0 "Inactive" 1 "RepeatOnTrack" 2 "Off" 3 "OnFolder" ;
VAL_ 473 NAV_CDSetIntroScan_Rq 0 "Inactive" 1 "On" 2 "Off" 3 "OnFolder" ;
VAL_ 810 ExtLghtDsply_B_StatArb 1 "On" 0 "Off" ;
VAL_ 810 OneTEditActv_B_RqCld 1 "Yes" 0 "No" ;
VAL_ 482 SDARS_Firm_Update2_St 0 "Invalid" 2 "Active" 1 "Inactive" ;
VAL_ 482 SDARS_UnSubscrb_Chan2_St 0 "Invalid" 2 "Active" 1 "Inactive" ;
VAL_ 482 SDARS_UnSubscrb2_St 0 "Invalid" 2 "Active" 1 "Inactive" ;
VAL_ 482 SDARS_Subscription2_St 0 "Invalid" 2 "Active" 1 "Inactive" ;
VAL_ 482 SDARS_Seek_Scan2_St 1 "NoChannelsAvailable" 0 "Invalid" ;
VAL_ 482 SDARS_Receive_Err2_St 0 "Invalid" 2 "Active" 1 "Inactive" ;
VAL_ 482 SDARS_Loss_Ant2_St 0 "Invalid" 2 "Active" 1 "Inactive" ;
VAL_ 482 SDARS_Invalid_Chan2_St 0 "Invalid" 2 "Active" 1 "Inactive" ;
VAL_ 482 SDARS_GCI_Update2_St 0 "Invalid" 2 "Active" 1 "Inactive" ;
VAL_ 482 SDARS_Error_Conf2_St 0 "Invalid" 2 "SDARS_OFF" 1 "SDARS_ON" ;
VAL_ 482 SDARS_Antenna_Err2_St 0 "Invalid" 2 "Active" 1 "Inactive" ;
VAL_ 764 SdarsSampleRate_D_Stat 3 "NotUsed_1" 2 "SampleRate_48000Hz" 1 "SampleRate_44100Hz" 0 "Null" ;
VAL_ 764 SdarsBaudRate_D_Stat 7 "NotUsed_3" 6 "NotUsed_2" 5 "NotUsed_1" 4 "BaudRate_460800bps" 3 "BaudRate_230400bps" 2 "BaudRate_115200bps" 1 "BaudRate_57600bps" 0 "Null" ;
VAL_ 764 SDARS_ChannelUpdate_St 3 "NotUsed_1" 2 "NewUpdatesAvailable" 1 "NoUpdates" 0 "Inactive" ;
VAL_ 764 SDARS_Channel_Lock2 0 "Invalid" 2 "Unlocked" 1 "Locked" ;
VAL_ 628 CamraRearBttn_D_Stat_UB 1 "Fresh_data" 0 "Unchanged_data" ;
VAL_ 628 CamraRearBttn_D_Stat 1 "Pressed" 0 "Not_Pressed" ;
VAL_ 628 GearEngag_D_Actl_UB 1 "Fresh_data" 0 "Unchanged_data" ;
VAL_ 628 GearEngag_D_Actl 7 "Undefined" 6 "Fwd_Clutch_Fully_Engaged" 5 "Neutral_Idle" 4 "Disengaged_to_Neutral_Idle" 3 "Disengaged_to_Neutral_Park" 2 "Engagement_in_Progress" 1 "InitializeFwdClutchEngagmt" 0 "Park_Neutral" ;
VAL_ 628 RvltnMatchAllw_D_Stat_UB 1 "Fresh_data" 0 "Unchanged_data" ;
VAL_ 628 RvltnMatchAllw_D_Stat 3 "RevolutionMatchDisabled" 2 "RevolutionMatchEnabled" 1 "ChangeWithDriveMode" 0 "NoSelection" ;
VAL_ 628 SeatScrnPsngrOn_B_Rq 1 "On" 0 "Off" ;
VAL_ 628 SeatScrnPsngrOn_B_Rq_UB 1 "Fresh_data" 0 "Unchanged_data" ;
VAL_ 628 CamraRearOn_B_RqBalrl_UB 1 "Fresh_data" 0 "Unchanged_data" ;
VAL_ 628 CamraRearOn_B_RqBalrr_UB 1 "Fresh_data" 0 "Unchanged_data" ;
VAL_ 628 CamraRearOn_B_RqBalrr 1 "Active" 0 "Inactive" ;
VAL_ 628 CamraRearOn_B_RqBalrl 1 "Active" 0 "Inactive" ;
VAL_ 628 PwFlwFuelDrv_D_Dsply 7 "NotUsed_4" 6 "NotUsed_3" 5 "NotUsed_2" 4 "NotUsed_1" 3 "FlwFromFuelToAllWhls" 2 "FlwFromFuelToFrontWhls" 1 "FlwFromFuelToRearWhls" 0 "NoFlow" ;
VAL_ 628 PwFlwFuelClimt_B_Dsply 1 "On" 0 "Off" ;
VAL_ 628 PwFlwFuelBatt_B_Dsply 1 "On" 0 "Off" ;
VAL_ 628 PwFlwBattGen_D_Dsply 1 "On" 0 "Off" ;
VAL_ 628 PwFlwBattClimt_B_Dsply 1 "On" 0 "Off" ;
VAL_ 628 PwFlwBatt_D_Dsply 15 "NotUsed_8" 14 "NotUsed_7" 13 "NotUsed_6" 12 "NotUsed_5" 11 "NotUsed_4" 10 "NotUsed_3" 9 "NotUsed_2" 8 "NotUsed_1" 7 "FlwFromWallToBatt" 6 "FlwFromAllWhlsToBatt" 5 "FlwFromBattToAllWhls" 4 "FlwFromFrontWhlsToBatt" 3 "FlwFromBattToFrontWhls" 2 "FlwFromRearWhlsToBatt" 1 "FlwFromBattToRearWhls" 0 "NoFlow" ;
VAL_ 628 PwFlwFuelDrv_D_Dsply_UB 1 "Fresh_data" 0 "Unchanged_data" ;
VAL_ 628 PwFlwFuelClimt_B_Dsply_UB 1 "Fresh_data" 0 "Unchanged_data" ;
VAL_ 628 PwFlwFuelBatt_B_Dsply_UB 1 "Fresh_data" 0 "Unchanged_data" ;
VAL_ 628 PwFlwBattGen_D_Dsply_UB 1 "Fresh_data" 0 "Unchanged_data" ;
VAL_ 628 PwFlwBattClimt_B_Dsply_UB 1 "Fresh_data" 0 "Unchanged_data" ;
VAL_ 628 PwFlwBatt_D_Dsply_UB 1 "Fresh_data" 0 "Unchanged_data" ;
VAL_ 628 TrailCtlMsgTxt_D_Rq 15 "Message15" 14 "Message14" 13 "Message13" 12 "Message12" 11 "Message11" 10 "Message10" 9 "Message9" 8 "Message8" 7 "Message7" 6 "Message6" 5 "Message5" 4 "Message4" 3 "Message3" 2 "Message2" 1 "Message1" 0 "NoMessage" ;
VAL_ 628 TrailCtlMsgTxt_D_Rq_UB 1 "Fresh_data" 0 "Unchanged_data" ;
VAL_ 628 TrailCtl_D_Stat_UB 1 "Fresh_data" 0 "Unchanged_data" ;
VAL_ 628 TrailCtl_D_Stat 7 "Faulty" 6 "DescentOnly" 5 "EnabledDeny" 4 "StandbyOverThreshold" 3 "StandbyOverride" 2 "Active" 1 "EnabledDescent" 0 "Off" ;
VAL_ 628 Veh_V_DsplyTrailCtlSet 63 "Faulty" ;
VAL_ 628 Veh_V_DsplyTrailCtlSet_UB 1 "Fresh_data" 0 "Unchanged_data" ;
VAL_ 628 SeatScrnDrvOn_B_Rq_UB 1 "Fresh_data" 0 "Unchanged_data" ;
VAL_ 628 SeatScrnDrvOn_B_Rq 1 "On" 0 "Off" ;
VAL_ 770 ScPayloadUpdate_B_Stat 3 "NotUsed" 2 "Complete" 1 "InProcess" 0 "Null" ;
VAL_ 770 ScChrgrPwMax_Pw_Actl 4095 "Faulty" ;
VAL_ 770 ScEnbl_B_Stat 1 "On" 0 "Off" ;
VAL_ 785 VehVLimMsgTxt_B_Rq 1 "Yes" 0 "No" ;
VAL_ 785 BattTracLimPerf_D_Dsply 3 "NotUsed" 2 "SeverelyLimitedPerformance" 1 "LimitedPerformance" 0 "NoDisplay" ;
VAL_ 785 EcoIdl_D_Stat 3 "NotUsed" 2 "Enabled" 1 "Disabled" 0 "Null" ;
VAL_ 785 DteVehOffst_L_Dsply 8191 "Faulty" 8190 "NoDataExists" ;
VAL_ 785 DteVehOffstMsgTxt_D_Rq 15 "NotUsed_7" 14 "NotUsed_6" 13 "NotUsed_5" 12 "NotUsed_4" 11 "NotUsed_3" 10 "NotUsed_2" 9 "NotUsed_1" 8 "PowerToTheBox" 7 "Payload" 6 "TrailerTowing_Off" 5 "TrailerTowing_On" 4 "TrafficAlongRoute" 3 "ExternalTemperature" 2 "HillyTerrain" 1 "DestinationRoute" 0 "NoMessage" ;
VAL_ 785 PwPckTqRdyChime_B_Rq 3 "NotUsed" 2 "Shutdown" 1 "Startup" 0 "Null" ;
VAL_ 785 BattTracLoThres_D_Stat 7 "NotUsed" 6 "Thres80km_50mi" 5 "Thres50km_31mi" 4 "Thres30km_18mi" 3 "Thres50mi_80km" 2 "Thres30mi_48km" 1 "Thres20mi_32km" 0 "Null" ;
VAL_ 785 BattTracLoMsgTxt_D_Rq 7 "NotUsed_2" 6 "NotUsed_1" 5 "ZeroDteBatteryDepleted" 4 "ClimateLowDteSecondAlert" 3 "ClimateLowDteFirstAlert" 2 "LowDteSecondAlert" 1 "LowDteFirstAlert" 0 "Null" ;
VAL_ 785 BattTracLoSoc_D_Dsply 3 "NotUsed" 2 "ZeroDteDepletedBattery" 1 "LoDte" 0 "Null" ;
VAL_ 391 ACU_CtrlChimeChan_Rq 3 "Reserved2" 2 "Reserved1" 1 "Mute" 0 "Inactive" ;
VAL_ 415 LBC3_Opcode 3 "NotUsed" 2 "SetItemIfno_Rq" 1 "GetItemInfo_Rq" 0 "Inactive" ;
VAL_ 501 Dsp_PresetArea_Rq 0 "Inactive" 1 "GetFm1PresetData" 2 "GetFm2PresetData" 3 "GetFm3PresetData" 4 "GetFmAstPresetData" 5 "GetAmAstPresetData" 6 "GetAmPresetData" 7 "GetFmStationListPresetData" ;
VAL_ 501 Dsp_SetRadSeekMode_Rq 15 "Reseved" 14 "ContAutoDown" 0 "Inactive" 1 "SeekOff" 2 "AutoUp" 3 "AutoDown" 4 "ManSingleStepUp" 5 "ManSingleStepDown" 6 "ContManualUp" 7 "ContManualDown" 8 "ScanUp" 9 "ScanDown" 10 "PtySeekUp" 11 "PtySeekDown" 12 "Autostore" 13 "ContAutoUp" ;
VAL_ 501 Dsp_SetCRadioBand_Rq 0 "Inactive" 1 "Fm1" 2 "Fm2" 3 "Fm3" 4 "FmAst" 5 "Am" 6 "AmAst" ;
VAL_ 501 Dsp_FreezeFMSL_Rq 3 "NotUsed" 2 "True" 1 "False" 0 "Inactive" ;
VAL_ 651 TelematicsSrvc_D_St 7 "NotUsed" 6 "NotifyNotActivatedYet" 5 "NotActivatedYet" 4 "NotifyExpired" 3 "Expired" 2 "ExpiringSoon" 1 "Active" 0 "Null" ;
VAL_ 651 EmgcyCallMute_D_Stat 7 "NotUsed4" 6 "NotUsed3" 5 "NotUsed2" 4 "NotUsed1" 3 "ManualEmergencyCallMute" 2 "AutomaticEmergencyCallMute" 1 "EmergencyCallUnmute" 0 "Null" ;
VAL_ 1098 EdmSailMdeOn_B_Stat 1 "On" 0 "Off" ;
VAL_ 1098 EdmMsgTxt_D_Rq 15 "NotUsed_4" 14 "NotUsed_3" 13 "NotUsed_2" 12 "NotUsed_1" 11 "OverallGoodScore" 10 "WorkOnCompliance" 9 "GoodCompliance" 8 "WorkOnGearShifting" 7 "GoodGearShifting" 6 "WorkOnEfficientSpeed" 5 "GoodEfficientSpeed" 4 "WorkOnDeceleration" 3 "GoodDeceleration" 2 "WorkOnAcceleration" 1 "GoodAcceleration" 0 "NoMessage" ;
VAL_ 1098 EdmLamp_D_Dsply 15 "NotUsed_7" 14 "NotUsed_6" 13 "NotUsed_5" 12 "NotUsed_4" 11 "NotUsed_3" 10 "NotUsed_2" 9 "NotUsed_1" 8 "CoastingEngineBrake" 7 "CoastingShiftToNeutral" 6 "FreewayJunction" 5 "Curve2" 4 "Curve1" 3 "SpeedLimit" 2 "Crossing" 1 "FreewayExit" 0 "NoRecommendation" ;
VAL_ 1098 EdmCmplnc_B_Dsply 1 "Yes" 0 "No" ;
VAL_ 629 GearPos_D_Actl_UB 1 "Fresh_data" 0 "Unchanged_data" ;
VAL_ 629 GearPos_D_Actl 15 "Unknown" 14 "Reverse" 13 "Undefined_5" 12 "Undefined_4" 11 "Undefined_3" 10 "Tenth" 9 "Ninth" 8 "Eighth" 7 "Seventh" 6 "Sixth" 5 "Fifth" 4 "Fourth" 3 "Third" 2 "Second" 1 "First" 0 "Neutral" ;
VAL_ 629 BattTrac2_E_Max_UB 1 "Fresh_data" 0 "Unchanged_data" ;
VAL_ 629 BattTrac2_E_Avail_UB 1 "Fresh_data" 0 "Unchanged_data" ;
VAL_ 629 BattTrac2_E_Max 4095 "Faulty" 4094 "NoDataExists" ;
VAL_ 629 BattTrac2_E_Avail 4095 "Faulty" 4094 "NoDataExists" ;
VAL_ 629 BattULoChrgHyb_D_Stat_UB 1 "Fresh_data" 0 "Unchanged_data" ;
VAL_ 629 TrnRng_D_Rq_UB 1 "Fresh_data" 0 "Unchanged_data" ;
VAL_ 629 TrnRng_D_Rq 15 "Fault" 14 "Unknown_Position" 13 "NotUsed_2" 12 "NotUsed_1" 11 "Range6" 10 "Range5" 9 "Range4" 8 "Range3_M3_L3" 7 "Range2_M2_L2" 6 "Range1_M1_L1" 5 "Low" 4 "Sport_DriveSport_Mposition" 3 "Drive" 2 "Neutral" 1 "Reverse" 0 "Park" ;
VAL_ 629 BattULoChrgHyb_D_Stat 7 "NotUsed_4" 6 "NotUsed_3" 5 "NotUsed_2" 4 "NotUsed_1" 3 "VehicleServiceRequired" 2 "EvRangeLossDueToLoadActive" 1 "BatteryServiceRequired" 0 "Null" ;
VAL_ 629 BattTracHazrd_D_Stat_UB 1 "Fresh_data" 0 "Unchanged_data" ;
VAL_ 629 BattTracHazrd_D_Stat 3 "NotUsed" 2 "HazardConfirmed" 1 "ExternalMonitoringRequired" 0 "NoHazardDetected" ;
VAL_ 672 BCP_Audible_Beep_Rq 1 "Active" 0 "Inactive" ;
VAL_ 672 Coding_BtnID_D 1 "Pressed" 0 "Not_Pressed" ;
VAL_ 672 Coding_BtnID_C 1 "Pressed" 0 "Not_Pressed" ;
VAL_ 672 Coding_BtnID_B 1 "Pressed" 0 "Not_Pressed" ;
VAL_ 672 Coding_BtnID_A 1 "Pressed" 0 "Not_Pressed" ;
VAL_ 1205 CstmDrvMdeCfg2_B_Avail 1 "Available" 0 "NotAvailable" ;
VAL_ 1205 CstmDrvMdeCfg1_B_Avail 1 "Available" 0 "NotAvailable" ;
VAL_ 816 KeylessIdl_D_Rq 3 "Cancel" 2 "IgnitionOff" 1 "Active" 0 "Inactive" ;
VAL_ 816 KeyPadCodeDgt7_D_Stat 15 "NotUsed_4" 14 "NotUsed_3" 13 "NotUsed_2" 12 "NotUsed_1" 11 "Button7_8and9_0" 10 "Button0" 9 "Button9_0or9" 8 "Button8" 7 "Button7_8or7" 6 "Button6" 5 "Button5_6or5" 4 "Button4" 3 "Button3_4or3" 2 "Button2" 1 "Button1_2or1" 0 "EndofString" ;
VAL_ 816 KeyPadCodeDgt6_D_Stat 15 "NotUsed_4" 14 "NotUsed_3" 13 "NotUsed_2" 12 "NotUsed_1" 11 "Button7_8and9_0" 10 "Button0" 9 "Button9_0or9" 8 "Button8" 7 "Button7_8or7" 6 "Button6" 5 "Button5_6or5" 4 "Button4" 3 "Button3_4or3" 2 "Button2" 1 "Button1_2or1" 0 "EndofString" ;
VAL_ 816 KeyPadCodeDgt5_D_Stat 15 "NotUsed_4" 14 "NotUsed_3" 13 "NotUsed_2" 12 "NotUsed_1" 11 "Button7_8and9_0" 10 "Button0" 9 "Button9_0or9" 8 "Button8" 7 "Button7_8or7" 6 "Button6" 5 "Button5_6or5" 4 "Button4" 3 "Button3_4or3" 2 "Button2" 1 "Button1_2or1" 0 "EndofString" ;
VAL_ 816 KeyPadCodeDgt4_D_Stat 15 "NotUsed_4" 14 "NotUsed_3" 13 "NotUsed_2" 12 "NotUsed_1" 11 "Button7_8and9_0" 10 "Button0" 9 "Button9_0or9" 8 "Button8" 7 "Button7_8or7" 6 "Button6" 5 "Button5_6or5" 4 "Button4" 3 "Button3_4or3" 2 "Button2" 1 "Button1_2or1" 0 "EndofString" ;
VAL_ 816 KeyPadCodeDgt3_D_Stat 15 "NotUsed_4" 14 "NotUsed_3" 13 "NotUsed_2" 12 "NotUsed_1" 11 "Button7_8and9_0" 10 "Button0" 9 "Button9_0or9" 8 "Button8" 7 "Button7_8or7" 6 "Button6" 5 "Button5_6or5" 4 "Button4" 3 "Button3_4or3" 2 "Button2" 1 "Button1_2or1" 0 "EndofString" ;
VAL_ 816 KeyPadCodeDgt2_D_Stat 15 "NotUsed_4" 14 "NotUsed_3" 13 "NotUsed_2" 12 "NotUsed_1" 11 "Button7_8and9_0" 10 "Button0" 9 "Button9_0or9" 8 "Button8" 7 "Button7_8or7" 6 "Button6" 5 "Button5_6or5" 4 "Button4" 3 "Button3_4or3" 2 "Button2" 1 "Button1_2or1" 0 "EndofString" ;
VAL_ 816 KeyPadCodeDgt1_D_Stat 15 "NotUsed_4" 14 "NotUsed_3" 13 "NotUsed_2" 12 "NotUsed_1" 11 "Button7_8and9_0" 10 "Button0" 9 "Button9_0or9" 8 "Button8" 7 "Button7_8or7" 6 "Button6" 5 "Button5_6or5" 4 "Button4" 3 "Button3_4or3" 2 "Button2" 1 "Button1_2or1" 0 "EndofString" ;
VAL_ 816 CntrStk2_D_RqAssoc 7 "Unused_2" 6 "Cancel" 5 "Set_Keycode" 4 "RKE" 3 "Null" 2 "Key" 1 "Erase_KeyCode" 0 "Check_KeyCode" ;
VAL_ 636 WifiHtsptFqBand_D_Stat 3 "NotUsed_1" 2 "Band_2" 1 "Band_1" 0 "Null" ;
VAL_ 636 WifiHtspt_D_Falt 15 "Error15" 14 "Error14" 13 "Error13" 12 "Error12" 11 "Error11" 10 "Error10" 9 "Error9" 8 "Error8" 7 "Error7" 6 "Error6" 5 "Error5" 4 "Error4" 3 "Error3" 2 "Error2" 1 "Error1" 0 "Null" ;
VAL_ 636 WifiHtsptCnnct_D_Stat 3 "NotUsed" 2 "Connected" 1 "NotConnected" 0 "Null" ;
VAL_ 636 Telematics_D_Falt 7 "NotUsed_5" 6 "NotUsed_4" 5 "NotUsed_3" 4 "NotUsed_2" 3 "NotUsed_1" 2 "RunTimeError" 1 "ChipsetInitializationFailu" 0 "Null" ;
VAL_ 636 WifiEnbl_D_Stat 3 "NotUsed" 2 "Enable" 1 "Disable" 0 "Null" ;
VAL_ 636 WifiHtsptVisbl_D_Stat 3 "Not  used" 2 "On" 1 "Off" 0 "Null" ;
VAL_ 636 WifiHtsptScrty_D_Stat 3 "NotUsed_1" 2 "Wapi" 1 "Wpa2_Wpa" 0 "Null" ;
VAL_ 636 WifiHtsptEnbl_D_Stat 3 "OnDisabled" 2 "On" 1 "Off" 0 "Null" ;
VAL_ 636 WifiDevcListNew_B_Stat 1 "Available" 0 "NotAvailable" ;
VAL_ 636 WifiDataUsage_D_Stat 3 "PercentDataUsed" 2 "DataPlanExpired" 1 "FreeTrialPeriodWaiting" 0 "Null" ;
VAL_ 636 ModemSigStren_D_Stat 7 "NotUsed_1" 6 "NotDetermined" 5 "FiveBars" 4 "FourBars" 3 "ThreeBars" 2 "TwoBars" 1 "OneBar" 0 "ZeroBars" ;
VAL_ 636 ModemTechnology_D2_Stat 7 "Lte" 6 "HspaPlus" 5 "Umts" 4 "Edge" 3 "Gprs" 2 "Gsm" 1 "NoNetwork" 0 "Null" ;
VAL_ 636 WifiHtsptCrdntl_B_Stat 1 "Available" 0 "NotAvailable" ;
VAL_ 636 WifiHtsptFq_D_Avail 7 "NotUsed_3" 6 "NotUsed_2" 5 "NotUsed_1" 4 "AllAvailable" 3 "Band_2_Only" 2 "Band_1_Only" 1 "AllRestricted" 0 "Null" ;
VAL_ 636 WifiDataUsageOn_D_Stat 3 "NotUsed" 2 "On" 1 "Off" 0 "Null" ;
VAL_ 807 ElDistTripUnit_D_Stat 3 "NotUsed" 2 "Miles" 1 "Kilometers" 0 "Inactive" ;
VAL_ 807 ElDistTripCur_No_Dsply 0 "0 second" ;
VAL_ 974 EngExhMdeHrStrt_D_Stat 31 "NotUsed_7" 30 "NotUsed_6" 29 "NotUsed_5" 28 "NotUsed_4" 27 "NotUsed_3" 26 "NotUsed_2" 25 "NotUsed_1" 24 "Hour23_11pm" 23 "Hour22_10pm" 22 "Hour21_9pm" 21 "Hour20_8pm" 20 "Hour19_7pm" 19 "Hour18_6pm" 18 "Hour17_5pm" 17 "Hour16_4pm" 16 "Hour15_3pm" 15 "Hour14_2pm" 14 "Hour13_1pm" 13 "Hour12_12pm" 12 "Hour11_11am" 11 "Hour10_10am" 10 "Hour9_9am" 9 "Hour8_8am" 8 "Hour7_7am" 7 "Hour6_6am" 6 "Hour5_5am" 5 "Hour4_4am" 4 "Hour3_3am" 3 "Hour2_2am" 2 "Hour1_1am" 1 "Hour0_12am" 0 "Null" ;
VAL_ 974 EngExhMdeHrEnd_D_Stat 31 "NotUsed_7" 30 "NotUsed_6" 29 "NotUsed_5" 28 "NotUsed_4" 27 "NotUsed_3" 26 "NotUsed_2" 25 "NotUsed_1" 24 "Hour23_11pm" 23 "Hour22_10pm" 22 "Hour21_9pm" 21 "Hour20_8pm" 20 "Hour19_7pm" 19 "Hour18_6pm" 18 "Hour17_5pm" 17 "Hour16_4pm" 16 "Hour15_3pm" 15 "Hour14_2pm" 14 "Hour13_1pm" 13 "Hour12_12pm" 12 "Hour11_11am" 11 "Hour10_10am" 10 "Hour9_9am" 9 "Hour8_8am" 8 "Hour7_7am" 7 "Hour6_6am" 6 "Hour5_5am" 5 "Hour4_4am" 4 "Hour3_3am" 3 "Hour2_2am" 2 "Hour1_1am" 1 "Hour0_12am" 0 "Null" ;
VAL_ 974 EngExhMdeHrEnbl_D_Stat 3 "NotUsed" 2 "Enabled" 1 "Disabled" 0 "Null" ;
VAL_ 974 DcacOut_Pw_DsplyMx 1023 "Faulty" ;
VAL_ 974 DcacOut1_Pw_Dsply 63 "Faulty" ;
VAL_ 974 DcacOut2_Pw_Dsply 63 "Faulty" ;
VAL_ 974 DcacHw_D_Confg 15 "NotUsed_11" 14 "NotUsed_10" 13 "NotUsed_9" 12 "NotUsed_8" 11 "NotUsed_7" 10 "NotUsed_6" 9 "NotUsed_5" 8 "NotUsed_4" 7 "NotUsed_3" 6 "NotUsed_2" 5 "NotUsed_1" 4 "Power_2300W" 3 "Power_7200W" 2 "Power_2400W" 1 "Power_2000W" 0 "NoDcacHardware" ;
VAL_ 974 DcacFaltMsgTxt_D_Rq 15 "NotUsed" 14 "OvercurrentLP" 13 "EngineRun" 12 "Service" 11 "NotAvailable" 10 "PlugWarn" 9 "PlugWarnDrive" 8 "BreakerC" 7 "BreakerB" 6 "BreakerA" 5 "FuelLow" 4 "AcOnOutput" 3 "Temperature" 2 "Gfci" 1 "Overcurrent" 0 "Ok" ;
VAL_ 974 DcacLoFuelMsgTxt_D_Rq 31 "Minute_31" 30 "Minute_30" 29 "Minute_29" 28 "Minute_28" 27 "Minute_27" 26 "Minute_26" 25 "Minute_25" 24 "Minute_24" 23 "Minute_23" 22 "Minute_22" 21 "Minute_21" 20 "Minute_20" 19 "Minute_19" 18 "Minute_18" 17 "Minute_17" 16 "Minute_16" 15 "Minute_15" 14 "Minute_14" 13 "Minute_13" 12 "Minute_12" 11 "Minute_11" 10 "Minute_10" 9 "Minute_9" 8 "Minute_8" 7 "Minute_7" 6 "Minute_6" 5 "Minute_5" 4 "Minute_4" 3 "Minute_3" 2 "Minute_2" 1 "Minute_1" 0 "Ok" ;
VAL_ 974 DcacEngOnMsgTxt_D_Rq 3 "NotUsed" 2 "DisplayQuestion" 1 "DisplayWarning" 0 "Ok" ;
VAL_ 974 DcacElPw_D_Stat 3 "NotUsed" 2 "High" 1 "Low" 0 "Off" ;
VAL_ 974 PwBedPnlEnbl_B_Rq 1 "Enable" 0 "Disable" ;
VAL_ 974 DcacOn_B_Rq 1 "Enable" 0 "Disable" ;
VAL_ 974 DcacSys_B_Falt 1 "Yes" 0 "No" ;
VAL_ 974 DcacLedCtl_D_Rq 3 "Fast_Flash" 2 "Slow_Flash" 1 "On" 0 "Off" ;
VAL_ 805 InstFeTripUnit_D_Stat 15 "NotUsed_12" 14 "NotUsed_11" 13 "NotUsed_10" 12 "NotUsed_9" 11 "NotUsed_8" 10 "NotUsed_7" 9 "NotUsed_6" 8 "NotUsed_5" 7 "NotUsed_4" 6 "NotUsed_3" 5 "NotUsed_2" 4 "NotUsed_1" 3 "LiterPer100kilometer" 2 "KilometerPerLiter" 1 "MilePerGallon" 0 "Inactive" ;
VAL_ 804 ConsInstActv_B_Dsply 1 "Active" 0 "Inactive" ;
VAL_ 804 ConsInstUnit_D_Stat 3 "NotUsed" 2 "LiterPerHour" 1 "GallonPerHour" 0 "Inactive" ;
VAL_ 803 DistTripUnit_D_Stat 3 "NotUsed" 2 "Miles" 1 "Kilometers" 0 "Inactive" ;
VAL_ 802 AvgFeTripUnit_D_Stat 15 "NotUsed_12" 14 "NotUsed_11" 13 "NotUsed_10" 12 "NotUsed_9" 11 "NotUsed_8" 10 "NotUsed_7" 9 "NotUsed_6" 8 "NotUsed_5" 7 "NotUsed_4" 6 "NotUsed_3" 5 "NotUsed_2" 4 "NotUsed_1" 3 "LiterPer100kilometer" 2 "KilometerPerLiter" 1 "MilePerGallon" 0 "Inactive" ;
VAL_ 802 AvgFeTrip2Actv_B_Dsply 1 "Active" 0 "Inactive" ;
VAL_ 802 AvgFeTrip1Actv_B_Dsply 1 "Active" 0 "Inactive" ;
VAL_ 802 AvgFeActv_B_Dsply 1 "Active" 0 "Inactive" ;
VAL_ 812 TimerTrip2_T_Dsply 0 "0 second" ;
VAL_ 812 TimerTrip1_T_Dsply 0 "0 second" ;
VAL_ 885 VehStrtInhbt_D_Dsply 15 "NotUsed_12" 14 "NotUsed_11" 13 "NotUsed_10" 12 "NotUsed_9" 11 "NotUsed_8" 10 "NotUsed_7" 9 "NotUsed_6" 8 "NotUsed_5" 7 "NotUsed_4" 6 "NotUsed_3" 5 "NotUsed_2" 4 "OtaSuccess" 3 "PostOtaActivatePermFail" 2 "PostOtaActivateWarning" 1 "DuringOtaActivate" 0 "NoMessage" ;
VAL_ 885 OtaActv_D_Stat 15 "NotUsed_10" 14 "NotUsed_9" 13 "NotUsed_8" 12 "NotUsed_7" 11 "NotUsed_6" 10 "NotUsed_5" 9 "NotUsed_4" 8 "NotUsed_3" 7 "NotUsed_2" 6 "NotUsed_1" 5 "NonInterruptible_Pending" 4 "NonInterruptible_Config" 3 "NonInterruptible_ER" 2 "NonInterruptible_AB" 1 "Interruptible_AB" 0 "NoInVehicleOta" ;
VAL_ 784 TrlrTireTSensRr_D_Stat 3 "Faulty" 2 "HighTempWarning" 1 "Normal" 0 "NotAvailable" ;
VAL_ 784 TrlrTireTSensRm_D_Stat 3 "Faulty" 2 "HighTempWarning" 1 "Normal" 0 "NotAvailable" ;
VAL_ 784 TrlrTireTSensRf_D_Stat 3 "Faulty" 2 "HighTempWarning" 1 "Normal" 0 "NotAvailable" ;
VAL_ 784 TrlrTireTSensLr_D_Stat 3 "Faulty" 2 "HighTempWarning" 1 "Normal" 0 "NotAvailable" ;
VAL_ 784 TrlrTireTSensLm_D_Stat 3 "Faulty" 2 "HighTempWarning" 1 "Normal" 0 "NotAvailable" ;
VAL_ 784 TrlrTireTSensLf_D_Stat 3 "Faulty" 2 "HighTempWarning" 1 "Normal" 0 "NotAvailable" ;
VAL_ 784 TrlrTireTempSys_D_Stat 3 "Faulty" 2 "HighTempWarning" 1 "Normal" 0 "NotSupported" ;
VAL_ 784 TrlrTireRr_T_Actl 255 "NotSupported" 254 "Invalid" ;
VAL_ 784 TrlrTireRm_T_Actl 255 "NotSupported" 254 "Invalid" ;
VAL_ 784 TrlrTireRf_T_Actl 255 "NotSupported" 254 "Invalid" ;
VAL_ 784 TrlrTireLr_T_Actl 255 "NotSupported" 254 "Invalid" ;
VAL_ 784 TrlrTireLm_T_Actl 255 "NotSupported" 254 "Invalid" ;
VAL_ 784 TrlrTireLf_T_Actl 255 "NotSupported" 254 "Invalid" ;
VAL_ 290 WifiHtsptFqBand_D_Rq 3 "NotUsed_1" 2 "Band_2" 1 "Band_1" 0 "Null" ;
VAL_ 290 WifiHtsptTrial_D_RqDrv 3 "NotUsed_1" 2 "StopReminders" 1 "RemindMeLater" 0 "Null" ;
VAL_ 290 WifiHtsptEnbl_D_Rq 3 "Not used" 2 "On" 1 "Off" 0 "Null" ;
VAL_ 290 WifiRemoveDevc_D_Rq 3 "NotUsed_1" 2 "FromBlockedList" 1 "FromConnectedList" 0 "Null" ;
VAL_ 290 WifiHtsptVisbl_D_Rq 3 "Not used" 2 "On" 1 "Off" 0 "Null" ;
VAL_ 290 WifiHtsptMacAddr_B_Rq 1 "Request" 0 "No request" ;
VAL_ 290 WifiDevcList_D_Rq 3 "NoEntry" 2 "BlockedList" 1 "ConnectedList" 0 "Null" ;
VAL_ 290 WifiDataUsage_D_Rq 3 "RetriveDataFromBackend" 2 "RefreshData" 1 "CurrentData" 0 "Null" ;
VAL_ 290 WifiCarrierInfo_B_Rq 1 "Request" 0 "No  request" ;
VAL_ 290 WifiHtsptScrty_D_Rq 3 "NotUsed_1" 2 "Wapi" 1 "Wpa2_Wpa" 0 "Null" ;
VAL_ 1043 SelDrvMdeHmi02_D_Rq 31 "Faulty" 30 "SelDrvMde31" 29 "SelDrvMde30" 28 "SelDrvMde29" 27 "SelDrvMde28" 26 "SelDrvMde27" 25 "SelDrvMde26" 24 "SelDrvMde25" 23 "SelDrvMde24" 22 "SelDrvMde23" 21 "SelDrvMde22" 20 "SelDrvMde21" 19 "SelDrvMde20" 18 "SelDrvMde19" 17 "SelDrvMde18" 16 "SelDrvMde17" 15 "SelDrvMde16" 14 "SelDrvMde15" 13 "SelDrvMde14" 12 "SelDrvMde13" 11 "SelDrvMde12" 10 "SelDrvMde11" 9 "SelDrvMde10" 8 "SelDrvMde09" 7 "SelDrvMde08" 6 "SelDrvMde07" 5 "SelDrvMde06" 4 "SelDrvMde05" 3 "SelDrvMde04" 2 "SelDrvMde03" 1 "SelDrvMde02" 0 "SelDrvMde01" ;
VAL_ 1043 SelDrvMdeHmi04_D_Rq 31 "Faulty" 30 "SelDrvMde31" 29 "SelDrvMde30" 28 "SelDrvMde29" 27 "SelDrvMde28" 26 "SelDrvMde27" 25 "SelDrvMde26" 24 "SelDrvMde25" 23 "SelDrvMde24" 22 "SelDrvMde23" 21 "SelDrvMde22" 20 "SelDrvMde21" 19 "SelDrvMde20" 18 "SelDrvMde19" 17 "SelDrvMde18" 16 "SelDrvMde17" 15 "SelDrvMde16" 14 "SelDrvMde15" 13 "SelDrvMde14" 12 "SelDrvMde13" 11 "SelDrvMde12" 10 "SelDrvMde11" 9 "SelDrvMde10" 8 "SelDrvMde09" 7 "SelDrvMde08" 6 "SelDrvMde07" 5 "SelDrvMde06" 4 "SelDrvMde05" 3 "SelDrvMde04" 2 "SelDrvMde03" 1 "SelDrvMde02" 0 "SelDrvMde01" ;
VAL_ 1043 IndvMdeSel_D_Stat 3 "NotUsed" 2 "DriveModeChangeRequest" 1 "DriveModeChangeSelection" 0 "NoDriveModeChangeRequest" ;
VAL_ 1043 IndvMdeMsgTxt_D_Rq 15 "Message15" 14 "Message14" 13 "Message13" 12 "Message12" 11 "Message11" 10 "Message10" 9 "Message9" 8 "Message8" 7 "Message7" 6 "Message6" 5 "Message5" 4 "Message4" 3 "Message3" 2 "Message2" 1 "Message1" 0 "NoMessage" ;
VAL_ 1043 IndvMde5_B_Avail 1 "Available" 0 "NotAvailable" ;
VAL_ 1043 IndvMde4_B_Avail 1 "Available" 0 "NotAvailable" ;
VAL_ 1043 IndvMde3_B_Avail 1 "Available" 0 "NotAvailable" ;
VAL_ 1043 IndvMde2_B_Avail 1 "Available" 0 "NotAvailable" ;
VAL_ 1043 IndvMde1_B_Avail 1 "Available" 0 "NotAvailable" ;
VAL_ 1043 TrailOnePdlMde_D_Ind 7 "NotUsed_4" 6 "NotUsed_3" 5 "NotUsed_2" 4 "NotUsed_1" 3 "Standby" 2 "Active" 1 "Fault" 0 "Off" ;
VAL_ 1043 TrailOnePdlMsgTxt_D_Rq 7 "Message7" 6 "Message6" 5 "Message5" 4 "Message4" 3 "Message3" 2 "Message2" 1 "Message1" 0 "NoMessage" ;
VAL_ 1043 OrtaSwtchLamp_B_Rq 1 "On" 0 "Off" ;
VAL_ 1043 OrtaMsgTxt_D_Rq 15 "Message15" 14 "Message14" 13 "Message13" 12 "Message12" 11 "Message11" 10 "Message10" 9 "Message9" 8 "Message8" 7 "Message7" 6 "Message6" 5 "Message5" 4 "Message4" 3 "Message3" 2 "Message2" 1 "Message1" 0 "NoMessage" ;
VAL_ 1043 OrtaMde_D_Ind 7 "Faulty" 6 "NotUsed_2" 5 "NotUsed_1" 4 "ActiveRight" 3 "ActiveLeft" 2 "StandbyRight" 1 "StandbyLeft" 0 "Off" ;
VAL_ 813 TimerTripCurnt_T_Dsply 0 "0 second" ;
VAL_ 639 OfbChrgPrflUpdate_B_Rq 1 "Request" 0 "NoRequest" ;
VAL_ 639 OfbChrgClearAll_B_Rq 1 "Request" 0 "NoRequest" ;
VAL_ 639 OfbChrgGoTTouch_D_Rq 3 "NotUsed" 2 "On" 1 "Off" 0 "Null" ;
VAL_ 639 OfbChrgGoTPrcond_D_Rq 3 "High" 2 "Medium" 1 "Low" 0 "Off" ;
VAL_ 639 OfbChrgGoTOn_D_Rq 3 "NotUsed" 2 "On" 1 "Off" 0 "Null" ;
VAL_ 639 OfbChrgGoTMnte_D_Rq 15 "NotUsed_4" 14 "NotUsed_3" 13 "NotUsed_2" 12 "NotUsed_1" 11 "Minute_55" 10 "Minute_50" 9 "Minute_45" 8 "Minute_40" 7 "Minute_35" 6 "Minute_30" 5 "Minute_25" 4 "Minute_20" 3 "Minute_15" 2 "Minute_10" 1 "Minute_5" 0 "Minute_0" ;
VAL_ 639 OfbChrgGoTHr_T_Rq 31 "Faulty" 30 "NoDataExists" ;
VAL_ 639 OfbChrgGoTExtHtr_D_Rq 3 "NotUsed" 2 "On" 1 "Off" 0 "Null" ;
VAL_ 639 OfbChrgGoTDelete_B_Rq 1 "Request" 0 "NoRequest" ;
VAL_ 639 OfbChrgGoTUpdate_B_Rq 1 "Request" 0 "NoRequest" ;
VAL_ 419 MK_SpeedValue_Rq 31 "mph90" 30 "mph85" 29 "mph80" 28 "mph75" 27 "mph70" 26 "mph65" 25 "mph60" 24 "mph55" 23 "mph50" 22 "mph45" 21 "mph40" 20 "Kmh165" 19 "Kmh160" 18 "Kmh155" 17 "Kmh150" 16 "Kmh145" 15 "Kmh140" 14 "Kmh135" 13 "Kmh130" 12 "Kmh125" 11 "Kmh120" 10 "Kmh115" 9 "Kmh110" 8 "Kmh105" 7 "Kmh100" 6 "kmh95" 5 "kmh90" 4 "kmh85" 3 "kmh80" 2 "kmh75" 1 "kmh70" 0 "Off" ;
VAL_ 419 MK_SpeedSetting_Rq 15 "Reserved_last" 3 "Reserved" 2 "SpeedMinder" 1 "SpeedLimit" 0 "Inactive" ;
VAL_ 419 MK_ResetAllUserKeys_Rq 1 "ResetAllKeys" 0 "Inactive" ;
VAL_ 419 MK_MyKeySystemInfo_Rq 1 "GetData" 0 "Inactive" ;
VAL_ 419 MK_ESCRestrictConf_Rq 2 "On" 1 "Off" 0 "Inactive" ;
VAL_ 419 MK_ECalRestrictConf_Rq 2 "On" 1 "Off" 0 "Inactive" ;
VAL_ 419 MK_DNDRestrictConf_Rq 2 "On" 1 "Off" 0 "Inactive" ;
VAL_ 419 MK_CreateMyKey_Rq 1 "Create" 0 "Inactive" ;
VAL_ 419 MK_AudioLimitConfig_Rq 2 "On" 1 "Off" 0 "Inactive" ;
VAL_ 419 MK_ACSRestrictConf_Rq 2 "On" 1 "Off" 0 "Inactive" ;
VAL_ 554 DrvHazrdModel_D_St 15 "NotUsed_13" 14 "NotUsed_12" 13 "NotUsed_11" 12 "NotUsed_10" 11 "NotUsed_9" 10 "NotUsed_8" 9 "NotUsed_7" 8 "NotUsed_6" 7 "NotUsed_5" 6 "NotUsed_4" 5 "NotUsed_3" 4 "NotUsed_2" 3 "NotUsed_1" 2 "TpegTec" 1 "DenmEm" 0 "None" ;
VAL_ 554 PtWakeupActv1_B_Rq 1 "Wake_up_Powertrain_via_HW" 0 "Don_t_Wake_Up_Powertrain" ;
VAL_ 554 DrvHazrd_D_St 7 "NotUsed_1" 6 "Suspended" 5 "Available" 4 "NoService" 3 "NoSession" 2 "bAllowOff" 1 "bSAllowOff" 0 "NoStatus" ;
VAL_ 494 HEC_TUPresetArea_Rq 13 "reserved" 12 "GetSAT3PresetData" 11 "GetSAT2PresetData" 15 "reserved_last" 10 "GetSAT1PresetData" 9 "GetDAB2PresetData" 8 "GetDAB1PresetData" 7 "Reserved1" 6 "GetAmPresetData" 5 "GetAmAstPresetData" 4 "GetFmAstPresetData" 3 "GetFm3PresetData" 2 "GetFm2PresetData" 1 "GetFm1PresetData" 0 "Inactive" ;
VAL_ 494 HEC_SetCurrTUBand_Rq 12 "reserved" 11 "SAT3" 10 "SAT2" 15 "reserved_last" 9 "SAT1" 8 "DAB2" 7 "DAB1" 6 "AmAst" 5 "Am" 4 "FmAst" 3 "Fm3" 2 "Fm2" 1 "Fm1" 0 "Inactive" ;
VAL_ 498 HEC_ARReqstrPriority_Rq 0 "EmergencyServ" 1 "TelService" 2 "AutoAnswer" 3 "Ta" 4 "PttMutevoice" 5 "NavUserVoiceCmd" 6 "NavSysVoiceCmd" 7 "Radio" 8 "Disc" 9 "Alarm" 10 "Ptynews" 11 "Aux_ExtSource" 12 "BT_BTNavAndTelMute" 13 "ManualAudioMute" 14 "NotReq" ;
VAL_ 498 HEC_AROperationType_Rq 0 "Inactive" 1 "Requestaudioresource" 2 "Releaseaudioresource" 3 "Releaseallaudioresouces" 4 "Getresourceupdate" 5 "Getallresourceupdates" ;
VAL_ 498 HEC_ARReqstrSystem_Rq 0 "FrontRequester" 1 "RearRequester" ;
VAL_ 498 HEC_ARAudioSource_Rq 15 "iPod" 14 "USB" 13 "BTAudio" 0 "AmfmRadio" 1 "FrontDisc" 2 "SDARS_DAB" 3 "InDashCdChanger" 4 "VoiceRecogniser" 5 "TelematicUnit" 6 "BluetoothPhone" 7 "RearDisc" 8 "APIM" 9 "FrontAuxInput" 10 "Navigation" 11 "RearAux" 12 "NotReq" ;
VAL_ 644 VehOnSrc_D_Stat_UB 1 "Fresh_data" 0 "Unchanged_data" ;
VAL_ 644 VehOnSrc_D_Stat 15 "NotUsed_11" 14 "NotUsed_10" 13 "NotUsed_9" 12 "NotUsed_8" 11 "NotUsed_7" 10 "NotUsed_6" 9 "NotUsed_5" 8 "NotUsed_4" 7 "SecureIdle" 6 "FleetVehicleInhibit" 5 "StolenVehicleInhibit" 4 "OverTheAir" 3 "RemoteParkAssist" 2 "RemoteStart" 1 "Manual" 0 "Off" ;
VAL_ 643 StrtInGearMsgTxt_D_Rq_UB 1 "Fresh_data" 0 "Unchanged_data" ;
VAL_ 643 StrtInGearMsgTxt_D_Rq 15 "Message15" 14 "Message14" 13 "Message13" 12 "Message12" 11 "Message11" 10 "Message10" 9 "Message9" 8 "Message8" 7 "Message7" 6 "Message6" 5 "Message5" 4 "Message4" 3 "Message3" 2 "Message2" 1 "Message1" 0 "NoMessage" ;
VAL_ 643 StabBarCnnct_D_Stat_UB 1 "Fresh_data" 0 "Unchanged_data" ;
VAL_ 643 StabBarCnnct_D_Stat 15 "Faulty" 14 "NotUsed_7" 13 "NotUsed_6" 12 "NotUsed_5" 11 "NotUsed_4" 10 "NotUsed_3" 9 "NotUsed_2" 8 "NotUsed_1" 7 "SbdFailure2" 6 "SbdFailure1" 5 "Shutdown" 4 "NormalClosing" 3 "NormalOpen" 2 "NormalOpening" 1 "NormalClosed" 0 "Initialize" ;
VAL_ 643 GearPos_D_Trg_UB 1 "Fresh_data" 0 "Unchanged_data" ;
VAL_ 643 GearPos_D_Trg 15 "Unknown" 14 "Reverse" 13 "Undefined_5" 12 "Undefined_4" 11 "Undefined_3" 10 "Tenth" 9 "Ninth" 8 "Eighth" 7 "Seventh" 6 "Sixth" 5 "Fifth" 4 "Fourth" 3 "Third" 2 "Second" 1 "First" 0 "Neutral" ;
VAL_ 643 PwTgateStepMsgTxt_B_Rq 1 "DisplayMessage" 0 "NoMessage" ;
VAL_ 643 PwTgateStepMsgTxt_B_Rq_UB 1 "Fresh_data" 0 "Unchanged_data" ;
VAL_ 643 PwTgateMsgTxt_B_Rq_UB 1 "Fresh_data" 0 "Unchanged_data" ;
VAL_ 643 PwTgateLamp_B_Rq_UB 1 "Fresh_data" 0 "Unchanged_data" ;
VAL_ 643 PwTgateMsgTxt_B_Rq 1 "DisplayMessage" 0 "NoMessage" ;
VAL_ 643 PwTgateLamp_B_Rq 1 "On" 0 "Off" ;
VAL_ 643 PwRnngBoardSwtch_D_Stat_UB 1 "Fresh_data" 0 "Unchanged_data" ;
VAL_ 643 PwRnngBoardT_D_Stat_UB 1 "Fresh_data" 0 "Unchanged_data" ;
VAL_ 643 PwRnngBoardT_D_Stat 3 "NotUsed" 2 "Timer2" 1 "Timer1" 0 "Inactive" ;
VAL_ 643 PwRnngBoardSwtch_D_Stat 3 "NotUsed" 2 "DeployUnlocked" 1 "AlwaysActive" 0 "Inactive" ;
VAL_ 643 OnePdlDrvLamp_B_Rq_UB 1 "Fresh_data" 0 "Unchanged_data" ;
VAL_ 643 OnePdlDrv_D_Dsply_UB 1 "Fresh_data" 0 "Unchanged_data" ;
VAL_ 643 OnePdlDrvLamp_B_Rq 1 "On" 0 "Off" ;
VAL_ 643 OnePdlDrv_D_Dsply 3 "Faulty" 2 "Suspended" 1 "On" 0 "Off" ;
VAL_ 643 SeatSlprPosMsgTxt_B_Rq_UB 1 "Fresh_data" 0 "Unchanged_data" ;
VAL_ 643 SeatSlprPosMsgTxt_B_Rq 1 "On" 0 "Off" ;
VAL_ 643 DrPrsntRearPsngr_D_Stat_UB 1 "Fresh_data" 0 "Unchanged_data" ;
VAL_ 643 DrPrsntPsngr_D_Stat_UB 1 "Fresh_data" 0 "Unchanged_data" ;
VAL_ 643 DrPsngrMsgTxt_B_Rq_UB 1 "Fresh_data" 0 "Unchanged_data" ;
VAL_ 643 DrPsngrMsgTxt_B_Rq 1 "Yes" 0 "No" ;
VAL_ 643 DrPrsntRearPsngr_D_Stat 3 "Faulty" 2 "Present" 1 "NotPresent" 0 "NotDetermined" ;
VAL_ 643 DrPrsntPsngr_D_Stat 3 "Faulty" 2 "Present" 1 "NotPresent" 0 "NotDetermined" ;
VAL_ 643 DrPrsntRearDrv_D_Stat_UB 1 "Fresh_data" 0 "Unchanged_data" ;
VAL_ 643 DrDrvMsgTxt_B_Rq_UB 1 "Fresh_data" 0 "Unchanged_data" ;
VAL_ 643 DrPrsntDrv_D_Stat_UB 1 "Fresh_data" 0 "Unchanged_data" ;
VAL_ 643 DrPrsntDrv_D_Stat 3 "Faulty" 2 "Present" 1 "NotPresent" 0 "NotDetermined" ;
VAL_ 643 DrPrsntRearDrv_D_Stat 3 "Faulty" 2 "Present" 1 "NotPresent" 0 "NotDetermined" ;
VAL_ 643 DrDrvMsgTxt_B_Rq 1 "Yes" 0 "No" ;
VAL_ 643 FstChrgCmplt_T_Est_UB 1 "Fresh_data" 0 "Unchanged_data" ;
VAL_ 643 TrunkFrontOpen_D_Stat_UB 1 "Fresh_data" 0 "Unchanged_data" ;
VAL_ 643 TrunkFrontOpen_D_Stat 3 "NotUsed" 2 "NotRestricted" 1 "Restricted" 0 "Null" ;
